[part 1 of 3: package /BMW/SystemComposition]
AUTOSAR XML (schema 4-2-2)
package /BMW/SystemComposition
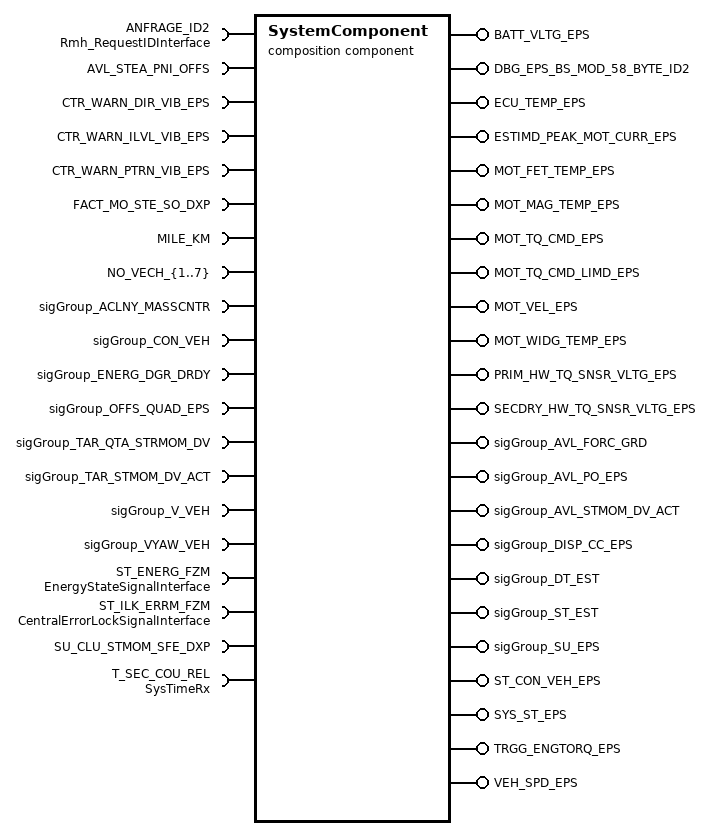
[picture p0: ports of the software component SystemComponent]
  composition sw component type SystemComponent
    23 x provide port:
      BATT_VLTG_EPS: nonqueued-sender-com-spec{data-element=BATT_VLTG_EPS, init-value=0}, provided-interface=BATT_VLTG_EPS
      DBG_EPS_BS_MOD_58_BYTE_ID2: nonqueued-sender-com-spec{data-element=DBG_EPS_BS_MOD_58_BYTE_ID2, init-value=1}, provided-interface=DBG_EPS_BS_MOD_58_BYTE_ID2
      ECU_TEMP_EPS: nonqueued-sender-com-spec=data-element=ECU_TEMP_EPS, provided-interface=ECU_TEMP_EPS
      ESTIMD_PEAK_MOT_CURR_EPS: nonqueued-sender-com-spec=data-element=ESTIMD_PEAK_MOT_CURR_EPS, provided-interface=ESTIMD_PEAK_MOT_CURR_EPS
      MOT_FET_TEMP_EPS: nonqueued-sender-com-spec=data-element=MOT_FET_TEMP_EPS, provided-interface=MOT_FET_TEMP_EPS
      MOT_MAG_TEMP_EPS: nonqueued-sender-com-spec=data-element=MOT_MAG_TEMP_EPS, provided-interface=MOT_MAG_TEMP_EPS
      MOT_TQ_CMD_EPS: nonqueued-sender-com-spec=data-element=MOT_TQ_CMD_EPS, provided-interface=MOT_TQ_CMD_EPS
      MOT_TQ_CMD_LIMD_EPS: nonqueued-sender-com-spec=data-element=MOT_TQ_CMD_LIMD_EPS, provided-interface=MOT_TQ_CMD_LIMD_EPS
      MOT_VEL_EPS: nonqueued-sender-com-spec=data-element=MOT_VEL_EPS, provided-interface=MOT_VEL_EPS
      MOT_WIDG_TEMP_EPS: nonqueued-sender-com-spec=data-element=MOT_WIDG_TEMP_EPS, provided-interface=MOT_WIDG_TEMP_EPS
      PRIM_HW_TQ_SNSR_VLTG_EPS: nonqueued-sender-com-spec=data-element=PRIM_HW_TQ_SNSR_VLTG_EPS, provided-interface=PRIM_HW_TQ_SNSR_VLTG_EPS
      SECDRY_HW_TQ_SNSR_VLTG_EPS: nonqueued-sender-com-spec=data-element=SECDRY_HW_TQ_SNSR_VLTG_EPS, provided-interface=SECDRY_HW_TQ_SNSR_VLTG_EPS
      sigGroup_AVL_FORC_GRD: nonqueued-sender-com-spec{data-element=sigGroup_AVL_FORC_GRD, uses-end-to-end-protection=true}, provided-interface=sigGroup_AVL_FORC_GRD
      sigGroup_AVL_PO_EPS: nonqueued-sender-com-spec{data-element=sigGroup_AVL_PO_EPS, uses-end-to-end-protection=true}, provided-interface=sigGroup_AVL_PO_EPS
      sigGroup_AVL_STMOM_DV_ACT: nonqueued-sender-com-spec{data-element=sigGroup_AVL_STMOM_DV_ACT, uses-end-to-end-protection=true}, provided-interface=sigGroup_AVL_STMOM_DV_ACT
      sigGroup_DISP_CC_EPS: nonqueued-sender-com-spec{data-element=sigGroup_DISP_CC_EPS, uses-end-to-end-protection=true}, provided-interface=sigGroup_DISP_CC_EPS
      sigGroup_DT_EST: nonqueued-sender-com-spec{data-element=sigGroup_DT_EST, uses-end-to-end-protection=true}, provided-interface=sigGroup_DT_EST
      sigGroup_ST_EST: nonqueued-sender-com-spec{data-element=sigGroup_ST_EST, uses-end-to-end-protection=true}, provided-interface=sigGroup_ST_EST
      sigGroup_SU_EPS: nonqueued-sender-com-spec{data-element=sigGroup_SU_EPS, uses-end-to-end-protection=true}, provided-interface=sigGroup_SU_EPS
      ST_CON_VEH_EPS: nonqueued-sender-com-spec=data-element=ST_CON_VEH_EPS, provided-interface=ST_CON_VEH_EPS
      SYS_ST_EPS: nonqueued-sender-com-spec=data-element=SYS_ST_EPS, provided-interface=SYS_ST_EPS
      TRGG_ENGTORQ_EPS: nonqueued-sender-com-spec=data-element=TRGG_ENGTORQ_EPS, provided-interface=TRGG_ENGTORQ_EPS
      VEH_SPD_EPS: nonqueued-sender-com-spec=data-element=VEH_SPD_EPS, provided-interface=VEH_SPD_EPS
    26 x require port:
      ANFRAGE_ID2: nonqueued-receiver-com-spec{data-element=requestedMsgID, filter=data-filter-type=ALWAYS}, required-interface=Rmh_RequestIDInterface
      AVL_STEA_PNI_OFFS: nonqueued-receiver-com-spec{data-element=AVL_STEA_PNI_OFFS, uses-end-to-end-protection=true, alive-timeout=0.11, enable-update=true, filter=data-filter-type=ALWAYS, init-value=2046}, required-interface=AVL_STEA_PNI_OFFS
      CTR_WARN_DIR_VIB_EPS: nonqueued-receiver-com-spec{data-element=CTR_WARN_DIR_VIB_EPS, alive-timeout=0.55, filter=data-filter-type=ALWAYS, init-value=3}, required-interface=CTR_WARN_DIR_VIB_EPS
      CTR_WARN_ILVL_VIB_EPS: nonqueued-receiver-com-spec{data-element=CTR_WARN_ILVL_VIB_EPS, alive-timeout=0.55, filter=data-filter-type=ALWAYS, init-value=15}, required-interface=CTR_WARN_ILVL_VIB_EPS
      CTR_WARN_PTRN_VIB_EPS: nonqueued-receiver-com-spec{data-element=CTR_WARN_PTRN_VIB_EPS, alive-timeout=0.55, filter=data-filter-type=ALWAYS, init-value=15}, required-interface=CTR_WARN_PTRN_VIB_EPS
      FACT_MO_STE_SO_DXP: nonqueued-receiver-com-spec{data-element=FACT_MO_STE_SO_DXP, alive-timeout=0.045, filter=data-filter-type=ALWAYS, init-value=255}, required-interface=FACT_MO_STE_SO_DXP
      MILE_KM: nonqueued-receiver-com-spec{data-element=MILE_KM, alive-timeout=11, filter=data-filter-type=ALWAYS, init-value=0}, required-interface=MILE_KM
      NO_VECH_{1..7}: nonqueued-receiver-com-spec{data-element=NO_VECH_{1..7}, filter=data-filter-type=ALWAYS}, required-interface=NO_VECH_{1..7}
      sigGroup_ACLNY_MASSCNTR: nonqueued-receiver-com-spec{data-element=sigGroup_ACLNY_MASSCNTR, uses-end-to-end-protection=true, alive-timeout=0.015, enable-update=true, filter=data-filter-type=ALWAYS}, required-interface=sigGroup_ACLNY_MASSCNTR
      sigGroup_CON_VEH: nonqueued-receiver-com-spec{data-element=sigGroup_CON_VEH, uses-end-to-end-protection=true, alive-timeout=0.11, enable-update=true, filter=data-filter-type=ALWAYS, init-value=fields=[0, CON_VEH_dummy_56_63:15, CRC_CON_VEH:0, CTR_BS_PRTNT:15, CTR_FKTN_PRTNT:15, QU_ST_CON_VEH:0, ST_CON_VEH:0]}, required-interface=sigGroup_CON_VEH
      sigGroup_ENERG_DGR_DRDY: nonqueued-receiver-com-spec{data-element=sigGroup_ENERG_DGR_DRDY, uses-end-to-end-protection=true, alive-timeout=0.015, enable-update=true, filter=data-filter-type=ALWAYS}, required-interface=sigGroup_ENERG_DGR_DRDY
      sigGroup_OFFS_QUAD_EPS: nonqueued-receiver-com-spec{data-element=sigGroup_OFFS_QUAD_EPS, uses-end-to-end-protection=true, alive-timeout=1.1, enable-update=true, filter=data-filter-type=ALWAYS, init-value=fields=[AVL_PO_IDX_ICM:65535, ST_OFFS_QUAD_EPS:15, CRC_OFFS_QUAD_EPS:0, OFFS_QUAD_RTR_EPS:255, ALIV_OFFS_QUAD_EPS:0]}, required-interface=sigGroup_OFFS_QUAD_EPS
      sigGroup_TAR_QTA_STRMOM_DV: nonqueued-receiver-com-spec{data-element=sigGroup_TAR_QTA_STRMOM_DV, uses-end-to-end-protection=true, alive-timeout=0.015, enable-update=true, filter=data-filter-type=ALWAYS}, required-interface=sigGroup_TAR_QTA_STRMOM_DV
      sigGroup_TAR_STMOM_DV_ACT: nonqueued-receiver-com-spec{data-element=sigGroup_TAR_STMOM_DV_ACT, uses-end-to-end-protection=true, alive-timeout=0.015, enable-update=true, filter=data-filter-type=ALWAYS}, required-interface=sigGroup_TAR_STMOM_DV_ACT
      sigGroup_V_VEH: nonqueued-receiver-com-spec{data-element=sigGroup_V_VEH, uses-end-to-end-protection=true, alive-timeout=0.02, enable-update=true, filter=data-filter-type=ALWAYS, init-value=fields=[0, CRC_V_VEH:0, DVCO_VEH:0, QU_V_VEH_COG:0, ST_V_VEH_NSS:1, V_VEH_COG:0, V_VEH_dummy_39_39:0]}, required-interface=sigGroup_V_VEH
      sigGroup_VYAW_VEH: nonqueued-receiver-com-spec{data-element=sigGroup_VYAW_VEH, uses-end-to-end-protection=true, alive-timeout=0.015, enable-update=true, filter=data-filter-type=ALWAYS}, required-interface=sigGroup_VYAW_VEH
      ST_ENERG_FZM: nonqueued-receiver-com-spec{data-element=energyState, uses-end-to-end-protection=true, alive-timeout=21, enable-update=true, filter=data-filter-type=ALWAYS, init-value=15}, required-interface=EnergyStateSignalInterface
      ST_ILK_ERRM_FZM: nonqueued-receiver-com-spec{data-element=centralErrorLock, alive-timeout=21, filter=data-filter-type=ALWAYS, init-value=3}, required-interface=CentralErrorLockSignalInterface
      SU_CLU_STMOM_SFE_DXP: nonqueued-receiver-com-spec{data-element=SU_CLU_STMOM_SFE_DXP, alive-timeout=0.045, filter=data-filter-type=ALWAYS, init-value=15}, required-interface=SU_CLU_STMOM_SFE_DXP
      T_SEC_COU_REL: nonqueued-receiver-com-spec{data-element=timeSignal, filter=data-filter-type=ALWAYS}, required-interface=SysTimeRx
    263 x component:
      AAACalRegn01Inin00_Dummy: type=AAACalRegn01Inin01_Dummy
      AAACalRegn01Inin00GroupA_Dummy: type=AAACalRegn01Inin01GroupA_Dummy
      AAACalRegn01Inin00GroupC_Dummy: type=AAACalRegn01Inin01GroupC_Dummy
      AAACalRegn01Inin00GroupD_Dummy: type=AAACalRegn01Inin01GroupD_Dummy
      AAACalRegn01Inin01_Dummy: type=AAACalRegn01Inin01_Dummy
      AAACalRegn01Inin01GroupA_Dummy: type=AAACalRegn01Inin01GroupA_Dummy
      AAACalRegn01Inin01GroupC_Dummy: type=AAACalRegn01Inin01GroupC_Dummy
      AAACalRegn01Inin01GroupD_Dummy: type=AAACalRegn01Inin01GroupD_Dummy
      AAACalRegn01Inin02_Dummy: type=AAACalRegn01Inin01_Dummy
      AAACalRegn01Inin02GroupA_Dummy: type=AAACalRegn01Inin01GroupA_Dummy
      AAACalRegn01Inin02GroupC_Dummy: type=AAACalRegn01Inin01GroupC_Dummy
      AAACalRegn01Inin02GroupD_Dummy: type=AAACalRegn01Inin01GroupD_Dummy
      AAACalRegn01Inin03_Dummy: type=AAACalRegn01Inin01_Dummy
      AAACalRegn01Inin03GroupA_Dummy: type=AAACalRegn01Inin01GroupA_Dummy
      AAACalRegn01Inin03GroupC_Dummy: type=AAACalRegn01Inin01GroupC_Dummy
      AAACalRegn01Inin03GroupD_Dummy: type=AAACalRegn01Inin01GroupD_Dummy
      AAACalRegn01Inin04_Dummy: type=AAACalRegn01Inin01_Dummy
      AAACalRegn01Inin04GroupA_Dummy: type=AAACalRegn01Inin01GroupA_Dummy
      AAACalRegn01Inin04GroupC_Dummy: type=AAACalRegn01Inin01GroupC_Dummy
      AAACalRegn01Inin04GroupD_Dummy: type=AAACalRegn01Inin01GroupD_Dummy
      AAACalRegn01Inin05_Dummy: type=AAACalRegn01Inin01_Dummy
      AAACalRegn01Inin05GroupA_Dummy: type=AAACalRegn01Inin01GroupA_Dummy
      AAACalRegn01Inin05GroupC_Dummy: type=AAACalRegn01Inin01GroupC_Dummy
      AAACalRegn01Inin05GroupD_Dummy: type=AAACalRegn01Inin01GroupD_Dummy
      AAACalRegn01Inin06_Dummy: type=AAACalRegn01Inin01_Dummy
      AAACalRegn01Inin06GroupA_Dummy: type=AAACalRegn01Inin01GroupA_Dummy
      AAACalRegn01Inin06GroupC_Dummy: type=AAACalRegn01Inin01GroupC_Dummy
      AAACalRegn01Inin06GroupD_Dummy: type=AAACalRegn01Inin01GroupD_Dummy
      AAACalRegn01IninOptSetA{00..03}_Dummy: type=AAACalRegn01IninOptSetA01_Dummy
      AAACalRegn02Rt00_Dummy: type=AAACalRegn02Rt01_Dummy
      AAACalRegn02Rt00GroupA_Dummy: type=AAACalRegn02Rt01GroupA_Dummy
      AAACalRegn02Rt00GroupC_Dummy: type=AAACalRegn02Rt01GroupC_Dummy
      AAACalRegn02Rt00GroupD_Dummy: type=AAACalRegn02Rt01GroupD_Dummy
      AAACalRegn02Rt01_Dummy: type=AAACalRegn02Rt01_Dummy
      AAACalRegn02Rt01GroupA_Dummy: type=AAACalRegn02Rt01GroupA_Dummy
      AAACalRegn02Rt01GroupC_Dummy: type=AAACalRegn02Rt01GroupC_Dummy
      AAACalRegn02Rt01GroupD_Dummy: type=AAACalRegn02Rt01GroupD_Dummy
      AAACalRegn02Rt02_Dummy: type=AAACalRegn02Rt01_Dummy
      AAACalRegn02Rt02GroupA_Dummy: type=AAACalRegn02Rt01GroupA_Dummy
      AAACalRegn02Rt02GroupC_Dummy: type=AAACalRegn02Rt01GroupC_Dummy
      AAACalRegn02Rt02GroupD_Dummy: type=AAACalRegn02Rt01GroupD_Dummy
      AAACalRegn02Rt03_Dummy: type=AAACalRegn02Rt01_Dummy
      AAACalRegn02Rt03GroupA_Dummy: type=AAACalRegn02Rt01GroupA_Dummy
      AAACalRegn02Rt03GroupC_Dummy: type=AAACalRegn02Rt01GroupC_Dummy
      AAACalRegn02Rt03GroupD_Dummy: type=AAACalRegn02Rt01GroupD_Dummy
      BacComIf: type=BacComIf
      BattVltg: type=BattVltg
      BattVltgCorrln: type=BattVltgCorrln
      BmwDiagcSrvHndlg: type=BmwDiagcSrvHndlg
      BmwDrvgDynStMac: type=BmwDrvgDynStMac
      BmwFltHndlg: type=BmwFltHndlg
      BmwHaptcFb: type=BmwHaptcFb
      BmwHwAgArbnAndEotPosn: type=BmwHwAgArbnAndEotPosn
      BmwHwTqOvrlArbn: type=BmwHwTqOvrlArbn
      BmwMotTqOvrlArbn: type=BmwMotTqOvrlArbn
      BmwMsgSlot107Bas0Repn1BusFrChA: type=BmwMsgSlot107Bas0Repn1BusFrChA
      BmwMsgSlot108Bas0Repn2BusFrChA: type=BmwMsgSlot108Bas0Repn2BusFrChA
      BmwMsgSlot121Bas1Repn2BusFrChA: type=BmwMsgSlot121Bas1Repn2BusFrChA
      BmwMsgSlot234Bas1Repn2BusFrChA: type=BmwMsgSlot234Bas1Repn2BusFrChA
      BmwMsgSlot269Bas2Repn4BusFrChA: type=BmwMsgSlot269Bas2Repn4BusFrChA
      BmwMsgSlot274Bas0Repn8BusFrChA: type=BmwMsgSlot274Bas0Repn8BusFrChA
      BmwMsgSlot274Bas2Repn4BusFrChA: type=BmwMsgSlot274Bas2Repn4BusFrChA
      BmwMsgSlot276Bas4Repn8BusFrChA: type=BmwMsgSlot276Bas4Repn8BusFrChA
      BmwMsgSlot315Bas0Repn1BusFrChA: type=BmwMsgSlot315Bas0Repn1BusFrChA
      BmwMsgSlot49Bas0Repn2BusFrChA: type=BmwMsgSlot49Bas0Repn2BusFrChA
      BmwMsgSlot49Bas1Repn2BusFrChA: type=BmwMsgSlot49Bas1Repn2BusFrChA
      BmwMsgSlot51Bas0Repn2BusFrChA: type=BmwMsgSlot51Bas0Repn2BusFrChA
      BmwMsgSlot53Bas3Repn8BusFrChA: type=BmwMsgSlot53Bas3Repn8BusFrChA
      BmwMsgSlot55Bas0Repn2BusFrChA: type=BmwMsgSlot55Bas0Repn2BusFrChA
      BmwMsgSlot55Bas3Repn4BusFrChA: type=BmwMsgSlot55Bas3Repn4BusFrChA
      BmwMsgSlot56Bas0Repn2BusFrChA: type=BmwMsgSlot56Bas0Repn2BusFrChA
      BmwMsgSlot68Bas0Repn2BusFrChA: type=BmwMsgSlot68Bas0Repn2BusFrChA
      BmwMsgSlot68Bas1Repn2BusFrChA: type=BmwMsgSlot68Bas1Repn2BusFrChA
      BmwPwrPrkgDampg: type=BmwPwrPrkgDampg
      BmwSplyCurrLim: type=BmwSplyCurrLim
      BmwStReqMgr: type=BmwStReqMgr
      BmwSwFctDi: type=BmwSwFctDi
      BmwTqOvrlCdngAndDrvgDynFac: type=BmwTqOvrlCdngAndDrvgDynFac
      BmwTrfcJamAssiDampg: type=BmwTrfcJamAssiDampg
      BmwTunSetHndlr: type=BmwTunSetHndlr
      BmwVehSpd: type=BmwVehSpd
      CalRegn01Cmn: type=CalRegn01Cmn
      CalRegn01CmnGroupA: type=CalRegn01CmnGroupA
      CalRegn01CmnGroupB: type=CalRegn01CmnGroupB
      CalRegn01CmnGroupC: type=CalRegn01CmnGroupC
      CalRegn01CmnGroupD: type=CalRegn01CmnGroupD
      CalRegn01Inin00: type=CalRegn01Inin00
      CalRegn01Inin00GroupA: type=CalRegn01Inin00GroupA
      CalRegn01Inin00GroupC: type=CalRegn01Inin00GroupC
      CalRegn01Inin00GroupD: type=CalRegn01Inin00GroupD
      CalRegn01Inin01: type=CalRegn01Inin01
      CalRegn01Inin01GroupA: type=CalRegn01Inin01GroupA
      CalRegn01Inin01GroupC: type=CalRegn01Inin01GroupC
      CalRegn01Inin01GroupD: type=CalRegn01Inin01GroupD
      CalRegn01Inin02: type=CalRegn01Inin02
      CalRegn01Inin02GroupA: type=CalRegn01Inin02GroupA
      CalRegn01Inin02GroupC: type=CalRegn01Inin02GroupC
      CalRegn01Inin02GroupD: type=CalRegn01Inin02GroupD
      CalRegn01Inin03: type=CalRegn01Inin03
      CalRegn01Inin03GroupA: type=CalRegn01Inin03GroupA
      CalRegn01Inin03GroupC: type=CalRegn01Inin03GroupC
      CalRegn01Inin03GroupD: type=CalRegn01Inin03GroupD
      CalRegn01Inin04: type=CalRegn01Inin04
      CalRegn01Inin04GroupA: type=CalRegn01Inin04GroupA
      CalRegn01Inin04GroupC: type=CalRegn01Inin04GroupC
      CalRegn01Inin04GroupD: type=CalRegn01Inin04GroupD
      CalRegn01Inin05: type=CalRegn01Inin05
      CalRegn01Inin05GroupA: type=CalRegn01Inin05GroupA
      CalRegn01Inin05GroupC: type=CalRegn01Inin05GroupC
      CalRegn01Inin05GroupD: type=CalRegn01Inin05GroupD
      CalRegn01Inin06: type=CalRegn01Inin06
      CalRegn01Inin06GroupA: type=CalRegn01Inin06GroupA
      CalRegn01Inin06GroupC: type=CalRegn01Inin06GroupC
      CalRegn01Inin06GroupD: type=CalRegn01Inin06GroupD
      CalRegn01IninOptSetA{00..03}: type=CalRegn01IninOptSetA{00..03}
      CalRegn02Rt00: type=CalRegn02Rt00
      CalRegn02Rt00GroupA: type=CalRegn02Rt00GroupA
      CalRegn02Rt00GroupC: type=CalRegn02Rt00GroupC
      CalRegn02Rt00GroupD: type=CalRegn02Rt00GroupD
      CalRegn02Rt01: type=CalRegn02Rt01
      CalRegn02Rt01GroupA: type=CalRegn02Rt01GroupA
      CalRegn02Rt01GroupC: type=CalRegn02Rt01GroupC
      CalRegn02Rt01GroupD: type=CalRegn02Rt01GroupD
      CalRegn02Rt02: type=CalRegn02Rt02
      CalRegn02Rt02GroupA: type=CalRegn02Rt02GroupA
      CalRegn02Rt02GroupC: type=CalRegn02Rt02GroupC
      CalRegn02Rt02GroupD: type=CalRegn02Rt02GroupD
      CalRegn02Rt03: type=CalRegn02Rt03
      CalRegn02Rt03GroupA: type=CalRegn02Rt03GroupA
      CalRegn02Rt03GroupC: type=CalRegn02Rt03GroupC
      CalRegn02Rt03GroupD: type=CalRegn02Rt03GroupD
      CDD_Adc0CfgAndUse: type=CDD_Adc0CfgAndUse
      CDD_Adc1CfgAndUse: type=CDD_Adc1CfgAndUse
      CDD_AdcDiagc: type=CDD_AdcDiagc
      CDD_BattRtnCurr: type=CDD_BattRtnCurr
      CDD_Bmw5441McuCfg: type=CDD_Bmw5441McuCfg
      CDD_ChkPtAppl10: type=CDD_ChkPtAppl10
      CDD_ChkPtAppl{7..9}: type=CDD_ChkPtAppl{7..9}
      CDD_CoreVltgMonr: type=CDD_CoreVltgMonr
      CDD_CurrMeas: type=CDD_CurrMeas
      CDD_CurrMeasArbn: type=CDD_CurrMeasArbn
      CDD_DataAndAdrPar: type=CDD_DataAndAdrPar
      CDD_DmaCfgAndUse: type=CDD_DmaCfgAndUse
      CDD_EcmOutpAndDiagc: type=CDD_EcmOutpAndDiagc
      CDD_ExcpnHndlg: type=CDD_ExcpnHndlg
      CDD_FlsMem: type=CDD_FlsMem
      CDD_GuardCfgAndDiagc: type=CDD_GuardCfgAndDiagc
      CDD_HwTq4Meas: type=CDD_HwTq4Meas
      CDD_HwTq5Meas: type=CDD_HwTq5Meas
      CDD_McuCoreCfgAndDiagc: type=CDD_McuCoreCfgAndDiagc
      CDD_McuDiagc: type=CDD_McuDiagc
      CDD_MotAg0Meas: type=CDD_MotAg0Meas
      CDD_MotAg1Meas: type=CDD_MotAg1Meas
      CDD_MotAg3Meas: type=CDD_MotAg3Meas
      CDD_MotAg4Meas: type=CDD_MotAg4Meas
      CDD_MotAgCmp: type=CDD_MotAgCmp
      CDD_MotCtrlMgr: type=CDD_MotCtrlMgr
      CDD_MotCurrRegVltgLimr: type=CDD_MotCurrRegVltgLimr
      CDD_MotVel: type=CDD_MotVel
      CDD_NvMProxy: type=CDD_NvMProxy
      CDD_NxtrTi: type=CDD_NxtrTi
      CDD_RamMem: type=CDD_RamMem
      CDD_SinVltgGenn: type=CDD_SinVltgGenn
      CDD_SyncCrc: type=CDD_SyncCrc
      CDD_Tauj0CfgAndUse: type=CDD_Tauj0CfgAndUse
      CDD_TSG31CfgAndUse: type=CDD_TSG31CfgAndUse
      CDD_VrfyCritReg: type=CDD_VrfyCritReg
      CDD_XcpIf: type=CDD_XcpIf
      CDD_XcpIfXcpEve2MilliSecDataAcqn: type=CDD_XcpIfXcpEve2MilliSecDataAcqn
      ClsdLoopDampg: type=ClsdLoopDampg
      ClsdLoopHys: type=ClsdLoopHys
      CmnMfgSrv: type=CmnMfgSrv
      CmnMfgSrvIf: type=CmnMfgSrvIf
      CmplncErr: type=CmplncErr
      Coding: type=Coding
      CtrldVelRtn: type=CtrldVelRtn
      CurrMeasCorrln: type=CurrMeasCorrln
      Darh: type=Darh
      DemWrapper: type=DemWrapper
      DiagcMgr: type=DiagcMgr
      DiagcMgrProxyAppl10: type=DiagcMgrProxyAppl10
      DiagcMgrProxyAppl{7..9}: type=DiagcMgrProxyAppl{7..9}
      DiagcMgrStub: type=DiagcMgrStub
      Dlog: type=Dlog
      DutyCycThermProtn: type=DutyCycThermProtn
      EcuTMeas: type=EcuTMeas
      Effort: type=Effort
      ElecPwrCns: type=ElecPwrCns
      EotProtn: type=EotProtn
      EPSInstance: type=EPSComponent
      EpsStEstimn: type=EpsStEstimn
      FalbckAssi: type=FalbckAssi
      FltInj: type=FltInj
      GateDrv0Ctrl: type=GateDrv0Ctrl
      GlbLimr: type=GlbLimr
      HiLoadStallLimr: type=HiLoadStallLimr
      HwRefTqSum: type=HwRefTqSum
      HwTqArbn: type=HwTqArbn
      HwTqCorrln: type=HwTqCorrln
      HwTqTrakgCtrl: type=HwTqTrakgCtrl
      InertiaCmpVel: type=InertiaCmpVel
      IoHwAb: type=IoHwAb
      LimrCdng: type=LimrCdng
      LoaMgr: type=LoaMgr
      LrndRackCentr: type=LrndRackCentr
      LrnPinionCentr: type=LrnPinionCentr
      McalErrHndlg: type=McalErrHndlg
      McuErrInj: type=McuErrInj
      MotAgCorrln: type=MotAgCorrln
      MotCtrlPrmEstimn: type=MotCtrlPrmEstimn
      MotCurrPeakEstimn: type=MotCurrPeakEstimn
      MotCurrRegCfg: type=MotCurrRegCfg
      MotQuadDetn: type=MotQuadDetn
      MotRefMdl: type=MotRefMdl
      MotTqCalcd: type=MotTqCalcd
      MotTqCmdSca: type=MotTqCmdSca
      MotTqTranlDampg: type=MotTqTranlDampg
      MotVelCtrl: type=MotVelCtrl
      NxtrCalIds: type=NxtrCalIds
      NxtrMath: type=NxtrMath
      NxtrSwIds: type=NxtrSwIds
      Omc: type=Omc
      PhaDiscnct: type=PhaDiscnct
      PolarityCfg: type=PolarityCfg
      PosnTrakgServo: type=PosnTrakgServo
      ProgMfgSrv: type=ProgMfgSrv
      PullCmpActv: type=PullCmpActv
      PwrDiscnct: type=PwrDiscnct
      PwrLimr: type=PwrLimr
      PwrSply: type=PwrSply
      PwrUpSeq: type=PwrUpSeq
      Rmh: type=Rmh
      Rmh_Cdd: type=Rmh_Cdd
      RvsBattProtn: type=RvsBattProtn
      ShtdwnMech: type=ShtdwnMech
      StdDiag: type=StdDiag
      SteerCmdArbnAndLim: type=SteerCmdArbnAndLim
      Stm: type=Stm
      StOutpCtrl: type=StOutpCtrl
      Swp: type=Swp
      SysFricLrng: type=SysFricLrng
      SysKineAndEff: type=SysKineAndEff
      SysStMod: type=SysStMod
      SysTime: type=SysTime
      TEstimn: type=TEstimn
      TmplMonr: type=TmplMonr
      TqOscn: type=TqOscn
      TunSelnAuthy: type=TunSelnAuthy
      TunSelnMngt: type=TunSelnMngt
      TurnCntrCorrln: type=TurnCntrCorrln
      VehSigCdng: type=VehSigCdng
      VehSpdLimr: type=VehSpdLimr
      Vin: type=Vin
    connect BacComIf.ComVin -> Vin.ComVin
    connect BattVltg.BrdgVltg -> BmwDiagcSrvHndlg.BrdgVltg
    connect BattVltg.BrdgVltg -> BmwMsgSlot315Bas0Repn1BusFrChA.BrdgVltg
    connect BattVltg.BrdgVltg -> BmwSplyCurrLim.BrdgVltg
    connect BattVltg.BrdgVltg -> CDD_CurrMeas.BrdgVltg
    connect BattVltg.BrdgVltg -> CDD_MotCtrlMgr.BrdgVltg
    connect BattVltg.BrdgVltg -> CmnMfgSrv.BrdgVltg
    connect BattVltg.BrdgVltg -> DiagcMgr.BrdgVltg
    connect BattVltg.BrdgVltg -> ElecPwrCns.BrdgVltg
    connect BattVltg.BrdgVltg -> MotRefMdl.BrdgVltg
    connect BattVltg.BrdgVltg -> PwrLimr.BrdgVltg
    connect BattVltgCorrln.BattSwdVltgCorrlnSts -> BattVltg.BattSwdVltgCorrlnSts
    connect BmwDiagcSrvHndlg.BmwHwAgOffs -> BmwHwAgArbnAndEotPosn.BmwHwAgOffs
    connect BmwDiagcSrvHndlg.LockToLockEna -> BmwMotTqOvrlArbn.PinionCentrLrnEna
    connect BmwDiagcSrvHndlg.LockToLockEna -> LrndRackCentr.PinionCentrLrnEna
    connect BmwDiagcSrvHndlg.LockToLockEna -> LrnPinionCentr.PinionCentrLrnEna
    connect BmwDrvgDynStMac.DrvgDynIfSt -> BmwDiagcSrvHndlg.DrvgDynIfSt
    connect BmwDrvgDynStMac.DrvgDynIfSt -> BmwHwTqOvrlArbn.DrvgDynIfSt
    connect BmwDrvgDynStMac.DrvgDynActv -> BmwMotTqOvrlArbn.DrvgDynActv
    connect BmwDrvgDynStMac.DrvgDynIfSt -> BmwMsgSlot234Bas1Repn2BusFrChA.DrvgDynIfSt
    connect BmwDrvgDynStMac.DrvgDynActv -> BmwTqOvrlCdngAndDrvgDynFac.DrvgDynActv
    connect BmwDrvgDynStMac.DrvgDynIfSt -> BmwTqOvrlCdngAndDrvgDynFac.DrvgDynIfSt
    connect BmwDrvgDynStMac.OutpTqOvrlRampInEna -> BmwTqOvrlCdngAndDrvgDynFac.OutpTqOvrlRampInEna
    connect BmwFltHndlg.BmwFltLampReqSts -> BmwMsgSlot274Bas2Repn4BusFrChA.BmwFltLampReqSts
    connect BmwFltHndlg.BmwFltLampReqTyp -> BmwMsgSlot274Bas2Repn4BusFrChA.BmwFltLampReqTyp
    connect BmwHaptcFb.HaptcFbSt -> BmwMsgSlot234Bas1Repn2BusFrChA.HaptcFbSt
    connect BmwHaptcFb.HwOscnEna -> TqOscn.HwOscnEna
    connect BmwHaptcFb.HwOscnFallRampRate -> TqOscn.HwOscnFallRampRate
    connect BmwHaptcFb.HwOscnFrq -> TqOscn.HwOscnFrq
    connect BmwHaptcFb.HwOscnMotAmp -> TqOscn.HwOscnMotAmp
    connect BmwHaptcFb.HwOscnRisngRampRate -> TqOscn.HwOscnRisngRampRate
    connect BmwHwAgArbnAndEotPosn.BmwPinionAg -> BmwDiagcSrvHndlg.BmwPinionAg
    connect BmwHwAgArbnAndEotPosn.BmwPinionAgQlfr -> BmwDiagcSrvHndlg.BmwPinionAgQlfr
    connect BmwHwAgArbnAndEotPosn.BmwRackCentrToVehCentrOffs -> BmwDiagcSrvHndlg.BmwRackCentrToVehCentrOffs
    connect BmwHwAgArbnAndEotPosn.BmwRackCentrToVehCentrOffsVld -> BmwDiagcSrvHndlg.BmwRackCntrToVehCntrOffsVld
    connect BmwHwAgArbnAndEotPosn.ClrBmwRackCentrToVehCentrOffs -> BmwDiagcSrvHndlg.ClrBmwRackCentrToVehCentrOffs
    connect BmwHwAgArbnAndEotPosn.ClrVehCentrPosn -> BmwDiagcSrvHndlg.ClrVehCentrPosn
    connect BmwHwAgArbnAndEotPosn.LongTermVehCentrCmpl -> BmwDiagcSrvHndlg.LongTermVehCentrCmpl
    connect BmwHwAgArbnAndEotPosn.PinionAg -> BmwDiagcSrvHndlg.PinionAg
    connect BmwHwAgArbnAndEotPosn.PinionAgConf -> BmwDiagcSrvHndlg.PinionAgConf
    connect BmwHwAgArbnAndEotPosn.SetVehCentrPosn -> BmwDiagcSrvHndlg.SetVehCentrPosn
    connect BmwHwAgArbnAndEotPosn.BmwPinionAg -> BmwMsgSlot51Bas0Repn2BusFrChA.BmwPinionAg
    connect BmwHwAgArbnAndEotPosn.BmwPinionAgQlfr -> BmwMsgSlot51Bas0Repn2BusFrChA.BmwPinionAgQlfr
    connect BmwHwAgArbnAndEotPosn.BmwRackCentrToVehCentrOffs -> BmwMsgSlot51Bas0Repn2BusFrChA.BmwRackCntrToVehCntrOffs
    connect BmwHwAgArbnAndEotPosn.BmwRackCentrToVehCentrOffsVld -> BmwMsgSlot51Bas0Repn2BusFrChA.BmwRackCntrToVehCntrOffsVld
    connect BmwHwAgArbnAndEotPosn.PinionAg -> BmwPwrPrkgDampg.PinionAg
    connect BmwHwAgArbnAndEotPosn.PinionAgConf -> BmwPwrPrkgDampg.PinionAgConf
    connect BmwHwAgArbnAndEotPosn.BmwPinionAgQlfr -> BmwVehSpd.BmwPinionAgQlfr
    connect BmwHwAgArbnAndEotPosn.PinionAg -> ClsdLoopHys.HwAg
    connect BmwHwAgArbnAndEotPosn.PinionAg -> CmnMfgSrv.PinionAg
    connect BmwHwAgArbnAndEotPosn.OffsCmpdPinionAg -> CtrldVelRtn.HwAg
    connect BmwHwAgArbnAndEotPosn.PinionAgConf -> CtrldVelRtn.HwAgAuthy
    connect BmwHwAgArbnAndEotPosn.PinionAg -> EotProtn.HwAg
    connect BmwHwAgArbnAndEotPosn.PinionAgConf -> EotProtn.HwAgAuthy
    connect BmwHwAgArbnAndEotPosn.HwAgCcwDetd -> EotProtn.HwAgCcwDetd
    connect BmwHwAgArbnAndEotPosn.HwAgCwDetd -> EotProtn.HwAgCwDetd
    connect BmwHwAgArbnAndEotPosn.HwAgEotCcw -> EotProtn.HwAgEotCcw
    connect BmwHwAgArbnAndEotPosn.HwAgEotCw -> EotProtn.HwAgEotCw
    connect BmwHwAgArbnAndEotPosn.AlgndPinionAg -> LrndRackCentr.HwAg
    connect BmwHwAgArbnAndEotPosn.PinionAg -> LrnPinionCentr.HwAg
    connect BmwHwAgArbnAndEotPosn.PinionAg -> MotTqTranlDampg.HwAg
    connect BmwHwAgArbnAndEotPosn.PinionAg -> PosnTrakgServo.HwAg
    connect BmwHwAgArbnAndEotPosn.PinionAg -> PullCmpActv.HwAg
    connect BmwHwAgArbnAndEotPosn.PinionAgConf -> PullCmpActv.PinionAgConf
    connect BmwHwAgArbnAndEotPosn.PinionAg -> SysFricLrng.HwAg
    connect BmwHwAgArbnAndEotPosn.PinionAgConf -> SysFricLrng.HwAgAuthy
    connect BmwHwAgArbnAndEotPosn.PinionAg -> SysKineAndEff.PinionAg
    connect BmwHwAgArbnAndEotPosn.PinionAg -> VehSpdLimr.HwAg
    connect BmwHwAgArbnAndEotPosn.PinionAgConf -> VehSpdLimr.HwAgAuthy
    connect BmwHwAgArbnAndEotPosn.HwAgEotCcw -> VehSpdLimr.HwAgEotCcw
    connect BmwHwAgArbnAndEotPosn.HwAgEotCw -> VehSpdLimr.HwAgEotCw
    connect BmwHwTqOvrlArbn.HwTqCmdOvrl -> HwRefTqSum.HwTqCmdOvrl
    connect BmwMotTqOvrlArbn.MotTqOvrlCmd -> BmwDrvgDynStMac.MotTqOvrlCmd
    connect BmwMotTqOvrlArbn.MotTqOvrlCmd -> HwTqTrakgCtrl.MotTqCmdOvrl
    connect BmwMsgSlot107Bas0Repn1BusFrChA.BmwQuadOffsSts -> BmwHwAgArbnAndEotPosn.BmwQuadOffsSts
    connect BmwMsgSlot107Bas0Repn1BusFrChA.BmwQuadOffsStsVld -> BmwHwAgArbnAndEotPosn.BmwQuadOffsStsVld
    connect BmwMsgSlot107Bas0Repn1BusFrChA.BmwQuadRtrOffs -> BmwHwAgArbnAndEotPosn.BmwQuadRotorOffs
    connect BmwMsgSlot107Bas0Repn1BusFrChA.BmwQuadRtrOffsVld -> BmwHwAgArbnAndEotPosn.BmwQuadRotorOffsVld
    connect BmwMsgSlot108Bas0Repn2BusFrChA.BmwPinionAgOffs -> BmwHwAgArbnAndEotPosn.BmwPinionAgOffs
    connect BmwMsgSlot108Bas0Repn2BusFrChA.BmwPinionAgOffsSts -> BmwHwAgArbnAndEotPosn.BmwPinionAgOffsSts
    connect BmwMsgSlot121Bas1Repn2BusFrChA.BmwBasPtlNetCtrl -> BmwDiagcSrvHndlg.BmwBasPtlNetCtrl
    connect BmwMsgSlot121Bas1Repn2BusFrChA.BmwVehCdn -> BmwDiagcSrvHndlg.BmwVehCdn
    connect BmwMsgSlot121Bas1Repn2BusFrChA.BmwVehCdn -> BmwDrvgDynStMac.BmwVehCdn
    connect BmwMsgSlot121Bas1Repn2BusFrChA.BmwVehCdn -> BmwMsgSlot315Bas0Repn1BusFrChA.BmwVehCdn
    connect BmwMsgSlot121Bas1Repn2BusFrChA.BmwVehCdn -> BmwStReqMgr.BmwVehCdn
    connect BmwMsgSlot121Bas1Repn2BusFrChA.BmwVehCdnVld -> BmwStReqMgr.BmwVehCdnVld
    connect BmwMsgSlot269Bas2Repn4BusFrChA.BmwHaptcFbIntenNr -> BmwHaptcFb.BmwHaptcFbIntenNr
    connect BmwMsgSlot269Bas2Repn4BusFrChA.BmwHaptcFbIntenNrVld -> BmwHaptcFb.BmwHaptcFbIntenNrVld
    connect BmwMsgSlot269Bas2Repn4BusFrChA.BmwHaptcFbPatNr -> BmwHaptcFb.BmwHaptcFbPatNr
    connect BmwMsgSlot269Bas2Repn4BusFrChA.BmwHaptcFbPatNrVld -> BmwHaptcFb.BmwHaptcFbPatNrVld
    connect BmwMsgSlot276Bas4Repn8BusFrChA.BmwOdomDst -> BmwDiagcSrvHndlg.BmwOdomDst
    connect BmwMsgSlot276Bas4Repn8BusFrChA.BmwOdomDstVld -> BmwDiagcSrvHndlg.BmwOdomDstVld
    connect BmwMsgSlot53Bas3Repn8BusFrChA.BmwRtIdx -> BmwTunSetHndlr.BmwRtIdx
    connect BmwMsgSlot53Bas3Repn8BusFrChA.BmwRtIdxVld -> BmwTunSetHndlr.BmwRtIdxVld
    connect BmwMsgSlot55Bas0Repn2BusFrChA.BmwVehLatA -> VehSigCdng.VehLatASerlCom
    connect BmwMsgSlot55Bas0Repn2BusFrChA.BmwVehLatAVld -> VehSigCdng.VehLatAVldSerlCom
    connect BmwMsgSlot55Bas3Repn4BusFrChA.BmwNearStillVehSpdSts -> BmwMotTqOvrlArbn.BmwNearStillVehSpdSts
    connect BmwMsgSlot55Bas3Repn4BusFrChA.BmwCogVehSpd -> BmwVehSpd.BmwCogVehSpd
    connect BmwMsgSlot55Bas3Repn4BusFrChA.BmwCogVehSpdQlfr -> BmwVehSpd.BmwCogVehSpdQlfr
    connect BmwMsgSlot55Bas3Repn4BusFrChA.BmwCogVehSpdQlfrVld -> BmwVehSpd.BmwCogVehSpdQlfrVld
    connect BmwMsgSlot55Bas3Repn4BusFrChA.BmwCogVehSpdVld -> BmwVehSpd.BmwCogVehSpdVld
    connect BmwMsgSlot55Bas3Repn4BusFrChA.BmwNearStillVehSpdSts -> BmwVehSpd.BmwNearStillVehSpdSts
    connect BmwMsgSlot55Bas3Repn4BusFrChA.BmwNearStillVehSpdStsVld -> BmwVehSpd.BmwNearStillVehSpdStsVld
    connect BmwMsgSlot56Bas0Repn2BusFrChA.BmwVehYawRate -> VehSigCdng.VehYawRateSerlCom
    connect BmwMsgSlot56Bas0Repn2BusFrChA.BmwVehYawRateVld -> VehSigCdng.VehYawRateVldSerlCom
    connect BmwMsgSlot68Bas0Repn2BusFrChA.BmwDrvgDynEnaRqst -> BmwDrvgDynStMac.BmwDrvgDynEnaReq
    connect BmwMsgSlot68Bas0Repn2BusFrChA.BmwDrvgDynFacQlfr -> BmwDrvgDynStMac.BmwDrvgDynFacQlfr
    connect BmwMsgSlot68Bas0Repn2BusFrChA.BmwDrvgDynFacQlfrVld -> BmwDrvgDynStMac.BmwDrvgDynFacQlfrVld
    connect BmwMsgSlot68Bas0Repn2BusFrChA.BmwTarHwTqOvrlQlfr -> BmwDrvgDynStMac.BmwTarHwTqOvrlQlfr
    connect BmwMsgSlot68Bas0Repn2BusFrChA.BmwTarHwTqOvrlQlfrVld -> BmwDrvgDynStMac.BmwTarHwTqOvrlQlfrVld
    connect BmwMsgSlot68Bas0Repn2BusFrChA.BmwTarSteerTqDrvrActrQlfr -> BmwDrvgDynStMac.BmwTarSteerTqDrvrActrQlfr
    connect BmwMsgSlot68Bas0Repn2BusFrChA.BmwTarSteerTqDrvrActrQlfrVld -> BmwDrvgDynStMac.BmwTarSteerTqDrvrActrQlfrVld
    connect BmwMsgSlot68Bas0Repn2BusFrChA.BmwTrfcJamAssiDampgStReq -> BmwDrvgDynStMac.BmwTrfcJamAssiDampgStReq
    connect BmwMsgSlot68Bas0Repn2BusFrChA.BmwTrfcJamAssiDampgStReqVld -> BmwDrvgDynStMac.BmwTrfcJamAssiDampgStReqVld
    connect BmwMsgSlot68Bas0Repn2BusFrChA.BmwDrvgDynErrIfActv -> BmwHwTqOvrlArbn.BmwDrvgDynErrIfActv
    connect BmwMsgSlot68Bas0Repn2BusFrChA.BmwTarHwTqOvrl -> BmwHwTqOvrlArbn.BmwTarHwTqOvrl
    connect BmwMsgSlot68Bas0Repn2BusFrChA.BmwTarHwTqOvrlQlfr -> BmwHwTqOvrlArbn.BmwTarHwTqOvrlQlfr
    connect BmwMsgSlot68Bas0Repn2BusFrChA.BmwDrvgDynDampgFacReq -> BmwTqOvrlCdngAndDrvgDynFac.BmwDrvgDynDampgFacReq
    connect BmwMsgSlot68Bas0Repn2BusFrChA.BmwDrvgDynEffortFacReq -> BmwTqOvrlCdngAndDrvgDynFac.BmwDrvgDynEffortFacReq
    connect BmwMsgSlot68Bas0Repn2BusFrChA.BmwDrvgDynErrIfActv -> BmwTqOvrlCdngAndDrvgDynFac.BmwDrvgDynErrIfActv
    connect BmwMsgSlot68Bas0Repn2BusFrChA.BmwDrvgDynRtnFacReq -> BmwTqOvrlCdngAndDrvgDynFac.BmwDrvgDynRtnFacReq
    connect BmwMsgSlot68Bas0Repn2BusFrChA.BmwTarSteerTqDrvrActr -> BmwTqOvrlCdngAndDrvgDynFac.BmwTarSteerTqDrvrActr
    connect BmwMsgSlot68Bas0Repn2BusFrChA.BmwTrfcJamAssiDampgScaReq -> BmwTrfcJamAssiDampg.BmwTrfcJamAssiDampgScaReq
    connect BmwMsgSlot68Bas0Repn2BusFrChA.BmwTrfcJamAssiDampgScaReqVld -> BmwTrfcJamAssiDampg.BmwTrfcJamAssiDampgScaReqVld
    connect BmwMsgSlot68Bas0Repn2BusFrChA.BmwTrfcJamAssiDampgStReq -> BmwTrfcJamAssiDampg.BmwTrfcJamAssiDampgStReq
    connect BmwMsgSlot68Bas0Repn2BusFrChA.BmwTrfcJamAssiDampgStReqVld -> BmwTrfcJamAssiDampg.BmwTrfcJamAssiDampgStReqVld
    connect BmwMsgSlot68Bas1Repn2BusFrChA.BmwMaxCurrLimr -> BmwSplyCurrLim.BmwMaxCurrLimr
    connect BmwMsgSlot68Bas1Repn2BusFrChA.BmwMaxCurrLimrSts -> BmwSplyCurrLim.BmwMaxCurrLimrSts
    connect BmwPwrPrkgDampg.DampgCmdPwrPrkg -> HwRefTqSum.HwTqCmdDampg
    connect BmwSplyCurrLim.SplyCurrLim -> PwrLimr.SplyCurrLim
    connect BmwStReqMgr.StsSteerAssi -> BmwDrvgDynStMac.StsSteerAssi
    connect BmwStReqMgr.StsSteerAssi -> BmwHaptcFb.StsSteerAssi
    connect BmwStReqMgr.BmwEpsFctSts -> BmwMsgSlot234Bas1Repn2BusFrChA.BmwEpsFctSts
    connect BmwStReqMgr.SysOperMotTqCmdSca -> StOutpCtrl.SysOperMotTqCmdSca
    connect BmwStReqMgr.SysOperRampRate -> StOutpCtrl.SysOperRampRate
    connect BmwStReqMgr.PwrSplyEnaReq -> SysStMod.PwrSplyEnaReq
    connect BmwStReqMgr.SysStReqEna -> SysStMod.SysStReqEna
    connect BmwSwFctDi.HaptcFbEna -> BmwHaptcFb.HaptcFbEna
    connect BmwSwFctDi.HwTqOvrlCmdEna -> BmwHwTqOvrlArbn.HwTqOvrlCmdEna
    connect BmwSwFctDi.DampgCmdPwrPrkgEna -> BmwPwrPrkgDampg.DampgCmdPwrPrkgEna
    connect BmwSwFctDi.MaxCurrAtHiSpd -> BmwSplyCurrLim.MaxCurrAtHiSpd
    connect BmwSwFctDi.MaxCurrAtLoSpd -> BmwSplyCurrLim.MaxCurrAtLoSpd
    connect BmwSwFctDi.BmwOutpTqOvrlCmdEna -> BmwTqOvrlCdngAndDrvgDynFac.BmwOutpTqOvrlCmdEna
    connect BmwSwFctDi.DrvgDynFacEna -> BmwTqOvrlCdngAndDrvgDynFac.DrvgDynFacEna
    connect BmwSwFctDi.TrfcJamAssiCmdEna -> BmwTrfcJamAssiDampg.TrfcJamAssiCmdEna
    connect BmwSwFctDi.TunSetHndlrEna -> BmwTunSetHndlr.TunSetHndlrEna
    connect BmwSwFctDi.HwTqCmdHysBmwOvrd -> HwRefTqSum.HwTqCmdHys
    connect BmwSwFctDi.CtrldVelRtnCmdBmwOvrd -> HwRefTqSum.RtnCmd
    connect BmwSwFctDi.InertiaCmpVelCmdDiBmwOvrd -> InertiaCmpVel.InertiaCmpVelCmdDi
    connect BmwSwFctDi.PullCmpCmdDiBmwOvrd -> PullCmpActv.PullCmpCmdDi
    connect BmwSwFctDi.FricLrngCustEna -> SysFricLrng.FricLrngCustEna
    connect BmwTqOvrlCdngAndDrvgDynFac.DampgCmdSca -> BmwDrvgDynStMac.DampgCmdSca
    connect BmwTqOvrlCdngAndDrvgDynFac.EffortCmdSca -> BmwDrvgDynStMac.EffortCmdSca
    connect BmwTqOvrlCdngAndDrvgDynFac.RtnCmdSca -> BmwDrvgDynStMac.RtnCmdSca
    connect BmwTqOvrlCdngAndDrvgDynFac.BmwOutpTqOvrlCmd -> BmwMotTqOvrlArbn.BmwOutpTqOvrlCmd
    connect BmwTqOvrlCdngAndDrvgDynFac.DampgCmdSca -> ClsdLoopDampg.DampgCmdSca
    connect BmwTqOvrlCdngAndDrvgDynFac.RtnCmdSca -> CtrldVelRtn.RtnCmdSca
    connect BmwTqOvrlCdngAndDrvgDynFac.EffortCmdSca -> Effort.EffortCmdSca
    connect BmwTrfcJamAssiDampg.BmwTrfcJamAssiDampgSt -> BmwMotTqOvrlArbn.BmwTrfcJamAssiDampgSt
    connect BmwTrfcJamAssiDampg.TrfcJamAssiCmd -> BmwMotTqOvrlArbn.TrfcJamAssiCmd
    connect BmwTunSetHndlr.MotVrntRead -> ProgMfgSrv.MotVrntRead
    connect BmwTunSetHndlr.MotVrntWr -> ProgMfgSrv.MotVrntWr
    connect BmwTunSetHndlr.TunVrntRead -> ProgMfgSrv.TunVrntRead
    connect BmwTunSetHndlr.TunVrntWr -> ProgMfgSrv.TunVrntWr
    connect BmwTunSetHndlr.DesIninIdx -> TunSelnMngt.DesIninIdx
    connect BmwTunSetHndlr.DesIninOptSetAIdx -> TunSelnMngt.DesIninOptSetAIdx
    connect BmwTunSetHndlr.DesRtIdx -> TunSelnMngt.DesRtIdx
    connect BmwVehSpd.VehSpd -> BmwDiagcSrvHndlg.VehSpd
    connect BmwVehSpd.VehSpd -> BmwHaptcFb.VehSpd
    connect BmwVehSpd.VehSpdVld -> BmwHaptcFb.VehSpdVld
    connect BmwVehSpd.BmwSecurVehSpdSts -> BmwHwAgArbnAndEotPosn.BmwVehSpdSts
    connect BmwVehSpd.VehSpd -> BmwHwAgArbnAndEotPosn.VehSpd
    connect BmwVehSpd.VehSpdVld -> BmwHwAgArbnAndEotPosn.VehSpdVld
    connect BmwVehSpd.VehSpd -> BmwHwTqOvrlArbn.VehSpd
    connect BmwVehSpd.VehSpd -> BmwMotTqOvrlArbn.VehSpd
    connect BmwVehSpd.VehSpd -> BmwMsgSlot315Bas0Repn1BusFrChA.VehSpd
    connect BmwVehSpd.VehSpd -> BmwPwrPrkgDampg.VehSpd
    connect BmwVehSpd.VehSpd -> BmwSplyCurrLim.VehSpd
    connect BmwVehSpd.BmwSecurVehSpdSts -> BmwStReqMgr.BmwVehSpdSts
    connect BmwVehSpd.VehSpd -> BmwStReqMgr.VehSpd
    connect BmwVehSpd.VehSpd -> BmwTqOvrlCdngAndDrvgDynFac.VehSpd
    connect BmwVehSpd.VehSpd -> BmwTrfcJamAssiDampg.VehSpd
    connect BmwVehSpd.VehSpd -> CDD_CurrMeas.VehSpd
    connect BmwVehSpd.VehSpdVld -> CDD_CurrMeas.VehSpdVld
    connect BmwVehSpd.VehSpd -> CDD_MotCtrlMgr.VehSpd
    connect BmwVehSpd.VehSpd -> ClsdLoopDampg.VehSpd
    connect BmwVehSpd.VehSpd -> ClsdLoopHys.VehSpd
    connect BmwVehSpd.VehSpd -> CtrldVelRtn.VehSpd
    connect BmwVehSpd.VehSpd -> Effort.VehSpd
    connect BmwVehSpd.VehSpd -> EotProtn.VehSpd
    connect BmwVehSpd.VehSpd -> FalbckAssi.VehSpd
    connect BmwVehSpd.VehSpd -> GlbLimr.VehSpd
    connect BmwVehSpd.VehSpd -> HwTqTrakgCtrl.VehSpd
    connect BmwVehSpd.VehSpd -> InertiaCmpVel.VehSpd
    connect BmwVehSpd.VehSpd -> LimrCdng.VehSpd
    connect BmwVehSpd.VehSpd -> MotCurrRegCfg.VehSpd
    connect BmwVehSpd.VehSpd -> MotTqTranlDampg.VehSpd
    connect BmwVehSpd.VehSpd -> PosnTrakgServo.VehSpd
    connect BmwVehSpd.VehSpd -> PullCmpActv.VehSpd
    connect BmwVehSpd.VehSpdVld -> PullCmpActv.VehSpdVld
    connect BmwVehSpd.VehSpd -> SteerCmdArbnAndLim.VehSpd
    connect BmwVehSpd.VehSpd -> Swp.VehSpd
    connect BmwVehSpd.VehSpdVld -> Swp.VehSpdVld
    connect BmwVehSpd.VehSpd -> SysFricLrng.VehSpd
    connect BmwVehSpd.VehSpdVld -> SysFricLrng.VehSpdVld
    connect BmwVehSpd.VehSpd -> TunSelnAuthy.VehSpd
    connect BmwVehSpd.VehSpd -> VehSigCdng.VehSpdSerlCom
    connect BmwVehSpd.VehSpdVld -> VehSigCdng.VehSpdVldSerlCom
    connect BmwVehSpd.VehSpd -> VehSpdLimr.VehSpd
    connect CalRegn01Cmn.BattVltgCorrlnAllwdVltgDif -> BattVltgCorrln.BattVltgCorrlnAllwdVltgDif
    connect CalRegn01Cmn.BattVltgCorrlnBattLoVltg -> BattVltgCorrln.BattVltgCorrlnBattLoVltg
    connect CalRegn01Cmn.BattVltgCorrlnBattOverVltg -> BattVltgCorrln.BattVltgCorrlnBattOverVltg
    connect CalRegn01Cmn.BattVltgCorrlnBattUnderVltg -> BattVltgCorrln.BattVltgCorrlnBattUnderVltg
    connect CalRegn01Cmn.BattVltgCorrlnNtc0x03C0x044FailStep -> BattVltgCorrln.BattVltgCorrlnNtc0x03C0x044FailStep
    connect CalRegn01Cmn.BattVltgCorrlnNtc0x03C0x044PassStep -> BattVltgCorrln.BattVltgCorrlnNtc0x03C0x044PassStep
    connect CalRegn01Cmn.BattVltgCorrlnNtc0x0B0FailStep -> BattVltgCorrln.BattVltgCorrlnNtc0x0B0FailStep
    connect CalRegn01Cmn.BattVltgCorrlnNtc0x0B0PassStep -> BattVltgCorrln.BattVltgCorrlnNtc0x0B0PassStep
    connect CalRegn01Cmn.BattVltgCorrlnNtc0x0B1FailStep -> BattVltgCorrln.BattVltgCorrlnNtc0x0B1FailStep
    connect CalRegn01Cmn.BattVltgCorrlnNtc0x0B1PassStep -> BattVltgCorrln.BattVltgCorrlnNtc0x0B1PassStep
    connect CalRegn01Cmn.BattVltgCorrlnNtc0x0B5FailStep -> BattVltgCorrln.BattVltgCorrlnNtc0x0B5FailStep
    connect CalRegn01Cmn.BattVltgCorrlnNtc0x0B5PassStep -> BattVltgCorrln.BattVltgCorrlnNtc0x0B5PassStep
    connect CalRegn01Cmn.BattVltgCorrlnRcvrlBattLoVltg -> BattVltgCorrln.BattVltgCorrlnRcvrlBattLoVltg
    connect CalRegn01Cmn.BattVltgCorrlnRcvrlBattOverVltg -> BattVltgCorrln.BattVltgCorrlnRcvrlBattOverVltg
    connect CalRegn01Cmn.BattVltgCorrlnRcvrlBattUnderVltg -> BattVltgCorrln.BattVltgCorrlnRcvrlBattUnderVltg
    connect CalRegn01Cmn.BattVltgCorrlnSwdMax -> BattVltgCorrln.BattVltgCorrlnSwdMax
    connect CalRegn01Cmn.BattVltgCorrlnSysMinVltg -> BattVltgCorrln.BattVltgCorrlnSysMinVltg
    connect CalRegn01Cmn.BmwHwAgArbnAndEotPosnBmwPinionAgOffsLim -> BmwHwAgArbnAndEotPosn.BmwHwAgArbnAndEotPosnBmwPinionAgOffsLim
    connect CalRegn01Cmn.BmwHwAgArbnAndEotPosnBmwPinionAgOffsRateLim -> BmwHwAgArbnAndEotPosn.BmwHwAgArbnAndEotPosnBmwPinionAgOffsRateLim
    connect CalRegn01Cmn.BmwHwAgArbnAndEotPosnMinVehSpdReqdVldAbsPos -> BmwHwAgArbnAndEotPosn.BmwHwAgArbnAndEotPosnMinVehSpdReqdVldAbsPos
    connect CalRegn01Cmn.BmwHwAgArbnAndEotPosnMotPosnDegArbdBlnd -> BmwHwAgArbnAndEotPosn.BmwHwAgArbnAndEotPosnMotPosnDegArbdBlnd
    connect CalRegn01Cmn.BmwHwAgArbnAndEotPosnOffsAuthy -> BmwHwAgArbnAndEotPosn.BmwHwAgArbnAndEotPosnOffsAuthy
    connect CalRegn01Cmn.BmwHwAgArbnAndEotPosnOffsCorrnAuthy -> BmwHwAgArbnAndEotPosn.BmwHwAgArbnAndEotPosnOffsCorrnAuthy
    connect CalRegn01Cmn.BmwHwAgArbnAndEotPosnPinionAgFltTmrThd -> BmwHwAgArbnAndEotPosn.BmwHwAgArbnAndEotPosnPinionAgFltTmrThd
    connect CalRegn01Cmn.BmwHwAgArbnAndEotPosnSysPolarityAssi -> BmwHwAgArbnAndEotPosn.BmwHwAgArbnAndEotPosnSysPolarityAssi
    connect CalRegn01Cmn.BmwHwAgArbnAndEotPosnTmpCmpdAuthy -> BmwHwAgArbnAndEotPosn.BmwHwAgArbnAndEotPosnTmpCmpdAuthy
    connect CalRegn01Cmn.BmwHwAgArbnAndEotPosnTurnCntrAuthy -> BmwHwAgArbnAndEotPosn.BmwHwAgArbnAndEotPosnTurnCntrAuthy
    connect CalRegn01Cmn.BmwHwAgArbnAndEotPosnTurnCntrCorrlnStsTmrThd -> BmwHwAgArbnAndEotPosn.BmwHwAgArbnAndEotPosnTurnCntrCorrlnStsTmrThd
    connect CalRegn01Cmn.BmwMotTqOvrlArbnPullCmpCmdLim -> BmwMotTqOvrlArbn.BmwMotTqOvrlArbnPullCmpCmdLim
    connect CalRegn01Cmn.BmwTunSetHndlrBmwRtIdxDebThd -> BmwTunSetHndlr.BmwTunSetHndlrBmwRtIdxDebThd
    connect CalRegn01Cmn.BmwTunSetHndlrNrOfMotVrnt -> BmwTunSetHndlr.BmwTunSetHndlrNrOfMotVrnt
    connect CalRegn01Cmn.BmwTunSetHndlrNrOfTunSet -> BmwTunSetHndlr.BmwTunSetHndlrNrOfTunSet
    connect CalRegn01Cmn.BmwVehSpdBmwSecurVehSpdStsSigValVldDurnTiVal -> BmwVehSpd.BmwVehSpdBmwSecurVehSpdStsSigValVldDurnTiVal
    connect CalRegn01Cmn.BmwVehSpdNearStillSubVehSpd -> BmwVehSpd.BmwVehSpdNearStillSubVehSpd
    connect CalRegn01Cmn.BmwVehSpdRunngSubVehSpd -> BmwVehSpd.BmwVehSpdRunngSubVehSpd
    connect CalRegn01Cmn.BmwVehSpdSecurVehSpdInvldRateLim -> BmwVehSpd.BmwVehSpdSecurVehSpdInvldRateLim
    connect CalRegn01Cmn.BmwVehSpdSecurVehSpdVldRateLim -> BmwVehSpd.BmwVehSpdSecurVehSpdVldRateLim
    connect CalRegn01Cmn.AdcDiagcNtc0x032FailStep -> CDD_AdcDiagc.AdcDiagcNtc0x032FailStep
    connect CalRegn01Cmn.AdcDiagcNtc0x032PassStep -> CDD_AdcDiagc.AdcDiagcNtc0x032PassStep
    connect CalRegn01Cmn.AdcDiagcNtc0x033FailStep -> CDD_AdcDiagc.AdcDiagcNtc0x033FailStep
    connect CalRegn01Cmn.AdcDiagcNtc0x033PassStep -> CDD_AdcDiagc.AdcDiagcNtc0x033PassStep
    connect CalRegn01Cmn.CurrMeasEolFixdPwmPerd -> CDD_CurrMeas.CurrMeasEolFixdPwmPerd
    connect CalRegn01Cmn.CurrMeasEolGainMax -> CDD_CurrMeas.CurrMeasEolGainMax
    connect CalRegn01Cmn.CurrMeasEolGainMin -> CDD_CurrMeas.CurrMeasEolGainMin
    connect CalRegn01Cmn.CurrMeasEolGainNom -> CDD_CurrMeas.CurrMeasEolGainNom
    connect CalRegn01Cmn.CurrMeasEolGainNrOfSample -> CDD_CurrMeas.CurrMeasEolGainNrOfSample
    connect CalRegn01Cmn.CurrMeasEolGainNumer -> CDD_CurrMeas.CurrMeasEolGainNumer
    connect CalRegn01Cmn.CurrMeasEolMaxMotVel -> CDD_CurrMeas.CurrMeasEolMaxMotVel
    connect CalRegn01Cmn.CurrMeasEolOffsHiBrdgVltgMin -> CDD_CurrMeas.CurrMeasEolOffsHiBrdgVltgMin
    connect CalRegn01Cmn.CurrMeasEolOffsHiCmuOffs -> CDD_CurrMeas.CurrMeasEolOffsHiCmuOffs
    connect CalRegn01Cmn.CurrMeasEolOffsLoCmuOffs -> CDD_CurrMeas.CurrMeasEolOffsLoCmuOffs
    connect CalRegn01Cmn.CurrMeasEolOffsMax -> CDD_CurrMeas.CurrMeasEolOffsMax
    connect CalRegn01Cmn.CurrMeasEolOffsMin -> CDD_CurrMeas.CurrMeasEolOffsMin
    connect CalRegn01Cmn.CurrMeasEolOffsNom -> CDD_CurrMeas.CurrMeasEolOffsNom
    connect CalRegn01Cmn.CurrMeasEolOffsNrOfSample -> CDD_CurrMeas.CurrMeasEolOffsNrOfSample
    connect CalRegn01Cmn.CurrMeasEolTranCntrThd -> CDD_CurrMeas.CurrMeasEolTranCntrThd
    connect CalRegn01Cmn.CurrMeasMinRqrdPhaOnTi -> CDD_CurrMeas.CurrMeasMinRqrdPhaOnTi
    connect CalRegn01Cmn.CurrMeasMotAgCompuDly -> CDD_CurrMeas.CurrMeasMotAgCompuDly
    connect CalRegn01Cmn.CurrMeasMotCurrAdcVlyWrmIninMax -> CDD_CurrMeas.CurrMeasMotCurrAdcVlyWrmIninMax
    connect CalRegn01Cmn.CurrMeasMotCurrAdcVlyWrmIninMin -> CDD_CurrMeas.CurrMeasMotCurrAdcVlyWrmIninMin
    connect CalRegn01Cmn.CurrMeasNtc0x05DFailStep -> CDD_CurrMeas.CurrMeasNtc0x05DFailStep
    connect CalRegn01Cmn.CurrMeasNtc0x05DPassStep -> CDD_CurrMeas.CurrMeasNtc0x05DPassStep
    connect CalRegn01Cmn.SysGlbPrmMotPoleCnt -> CDD_CurrMeas.SysGlbPrmMotPoleCnt
    connect CalRegn01Cmn.CurrMeasArbnMaxStallCntr -> CDD_CurrMeasArbn.CurrMeasArbnMaxStallCntr
    connect CalRegn01Cmn.HwTq4MeasHwTq4PrtclFltFailStep -> CDD_HwTq4Meas.HwTq4MeasHwTq4PrtclFltFailStep
    connect CalRegn01Cmn.HwTq4MeasHwTq4PrtclFltPassStep -> CDD_HwTq4Meas.HwTq4MeasHwTq4PrtclFltPassStep
    connect CalRegn01Cmn.HwTq4MeasHwTqRngHiLim -> CDD_HwTq4Meas.HwTq4MeasHwTqRngHiLim
    connect CalRegn01Cmn.HwTq4MeasHwTqRngLoLim -> CDD_HwTq4Meas.HwTq4MeasHwTqRngLoLim
    connect CalRegn01Cmn.HwTq4MeasMovgAvrgFilEna -> CDD_HwTq4Meas.HwTq4MeasMovgAvrgFilEna
    connect CalRegn01Cmn.HwTq5MeasHwTq5PrtclFltFailStep -> CDD_HwTq5Meas.HwTq5MeasHwTq5PrtclFltFailStep
    connect CalRegn01Cmn.HwTq5MeasHwTq5PrtclFltPassStep -> CDD_HwTq5Meas.HwTq5MeasHwTq5PrtclFltPassStep
    connect CalRegn01Cmn.HwTq5MeasHwTqRngHiLim -> CDD_HwTq5Meas.HwTq5MeasHwTqRngHiLim
    connect CalRegn01Cmn.HwTq5MeasHwTqRngLoLim -> CDD_HwTq5Meas.HwTq5MeasHwTqRngLoLim
    connect CalRegn01Cmn.HwTq5MeasMovgAvrgFilEna -> CDD_HwTq5Meas.HwTq5MeasMovgAvrgFilEna
    connect CalRegn01Cmn.McuDiagc2MilliSecCntrCompThd -> CDD_McuDiagc.McuDiagc2MilliSecCntrCompThd
    connect CalRegn01Cmn.McuDiagcFltFailStep -> CDD_McuDiagc.McuDiagcFltFailStep
    connect CalRegn01Cmn.McuDiagcFltPassStep -> CDD_McuDiagc.McuDiagcFltPassStep
    connect CalRegn01Cmn.MotAg0MeasSnsrIfErrNtcMask -> CDD_MotAg0Meas.MotAg0MeasSnsrIfErrNtcMask
    connect CalRegn01Cmn.MotAg1MeasOffs -> CDD_MotAg1Meas.MotAg1MeasOffs
    connect CalRegn01Cmn.MotAg1MeasSnsrIfErrNtcMask -> CDD_MotAg1Meas.MotAg1MeasSnsrIfErrNtcMask
    connect CalRegn01Cmn.SysGlbPrmMotPoleCnt -> CDD_MotAgCmp.SysGlbPrmMotPoleCnt
    connect CalRegn01Cmn.MotCurrRegCfgCurrLoopSecOrderTrfFctEna -> CDD_MotCurrRegVltgLimr.MotCurrRegCfgCurrLoopSecOrderTrfFctEna
    connect CalRegn01Cmn.MotCurrRegVltgLimrMotCurrPredEna -> CDD_MotCurrRegVltgLimr.MotCurrRegVltgLimrMotCurrPredEna
    connect CalRegn01Cmn.MotCurrRegVltgLimrMotCurrPredTi -> CDD_MotCurrRegVltgLimr.MotCurrRegVltgLimrMotCurrPredTi
    connect CalRegn01Cmn.MotCurrRegVltgLimrMotCurrQaxRefMdfnRplEna -> CDD_MotCurrRegVltgLimr.MotCurrRegVltgLimrMotCurrQaxRefMdfnRplEna
    connect CalRegn01Cmn.MotCurrRegVltgLimrMotVltgBrdgFilEna -> CDD_MotCurrRegVltgLimr.MotCurrRegVltgLimrMotVltgBrdgFilEna
    connect CalRegn01Cmn.MotCurrRegVltgLimrMotVltgQaxFfFilEna -> CDD_MotCurrRegVltgLimr.MotCurrRegVltgLimrMotVltgQaxFfFilEna
    connect CalRegn01Cmn.MotRefMdlFbCtrlDi -> CDD_MotCurrRegVltgLimr.MotRefMdlFbCtrlDi
    connect CalRegn01Cmn.MotRefMdlIvtrDeadTiBrdgVltgSca -> CDD_MotCurrRegVltgLimr.MotRefMdlIvtrDeadTiBrdgVltgSca
    connect CalRegn01Cmn.SinVltgGennDthrEna -> CDD_SinVltgGenn.SinVltgGennDthrEna
    connect CalRegn01Cmn.SinVltgGennDthrLpFilCoeff -> CDD_SinVltgGenn.SinVltgGennDthrLpFilCoeff
    connect CalRegn01Cmn.CurrMeasEolFixdPwmPerd -> CDD_TSG31CfgAndUse.CurrMeasEolFixdPwmPerd
    connect CalRegn01Cmn.CurrMeasEolOffsHiCmuOffs -> CDD_TSG31CfgAndUse.CurrMeasEolOffsHiCmuOffs
    connect CalRegn01Cmn.CurrMeasEolOffsLoCmuOffs -> CDD_TSG31CfgAndUse.CurrMeasEolOffsLoCmuOffs
    connect CalRegn01Cmn.PhaDiscnctFixdPhaOnTi -> CDD_TSG31CfgAndUse.PhaDiscnctFixdPhaOnTi
    connect CalRegn01Cmn.PhaDiscnctFixdPwmPerd -> CDD_TSG31CfgAndUse.PhaDiscnctFixdPwmPerd
    connect CalRegn01Cmn.TSG31CfgAndUseAdcStrtOfCnvn2Offs -> CDD_TSG31CfgAndUse.TSG31CfgAndUseAdcStrtOfCnvn2Offs
    connect CalRegn01Cmn.TSG31CfgAndUseAdcStrtOfCnvnMotCtrlPeakOffs -> CDD_TSG31CfgAndUse.TSG31CfgAndUseAdcStrtOfCnvnMotCtrlPeakOffs
    connect CalRegn01Cmn.TSG31CfgAndUseAdcStrtOfCnvnMotCtrlVlyOffs -> CDD_TSG31CfgAndUse.TSG31CfgAndUseAdcStrtOfCnvnMotCtrlVlyOffs
    connect CalRegn01Cmn.TSG31CfgAndUseMtrAg0SPIStart -> CDD_TSG31CfgAndUse.TSG31CfgAndUseMtrAg0SPIStart
    connect CalRegn01Cmn.TSG31CfgAndUsePwmDbnd -> CDD_TSG31CfgAndUse.TSG31CfgAndUsePwmDbnd
    connect CalRegn01Cmn.CmnMfgSrvSecuAcsAtmptTiOut -> CmnMfgSrv.CmnMfgSrvSecuAcsAtmptTiOut
    connect CalRegn01Cmn.CmnMfgSrvSecuAcsMaxNrAtmpt -> CmnMfgSrv.CmnMfgSrvSecuAcsMaxNrAtmpt
    connect CalRegn01Cmn.CmplncErrHwAgNonLinCmplncDepTblY -> CmplncErr.CmplncErrHwAgNonLinCmplncDepTblY
    connect CalRegn01Cmn.CmplncErrHwAgNonLinCmplncIndTblX -> CmplncErr.CmplncErrHwAgNonLinCmplncIndTblX
    connect CalRegn01Cmn.CmplncErrMotAgNonLinCmplncDepTblY -> CmplncErr.CmplncErrMotAgNonLinCmplncDepTblY
    connect CalRegn01Cmn.CmplncErrMotAgNonLinCmplncIndTblX -> CmplncErr.CmplncErrMotAgNonLinCmplncIndTblX
    connect CalRegn01Cmn.CurrMeasCorrlnMaxErrCurr -> CurrMeasCorrln.CurrMeasCorrlnMaxErrCurr
    connect CalRegn01Cmn.CurrMeasCorrlnMaxStallCntr -> CurrMeasCorrln.CurrMeasCorrlnMaxStallCntr
    connect CalRegn01Cmn.CurrMeasCorrlnNtc0x04DFailStep -> CurrMeasCorrln.CurrMeasCorrlnNtc0x04DFailStep
    connect CalRegn01Cmn.CurrMeasCorrlnNtc0x04DPassStep -> CurrMeasCorrln.CurrMeasCorrlnNtc0x04DPassStep
    connect CalRegn01Cmn.DiagcMgrFltResp -> DiagcMgr.DiagcMgrFltResp
    connect CalRegn01Cmn.DiagcMgrFltResp -> DiagcMgrProxyAppl10.DiagcMgrFltResp
    connect CalRegn01Cmn.DiagcMgrFltResp -> DiagcMgrProxyAppl{7..9}.DiagcMgrFltResp
    connect CalRegn01Cmn.ElecPwrCnsCtrlrInpR -> ElecPwrCns.ElecPwrCnsCtrlrInpR
    connect CalRegn01Cmn.GateDrv0CtrlErrFilFrq -> GateDrv0Ctrl.GateDrv0CtrlErrFilFrq
    connect CalRegn01Cmn.GateDrv0CtrlErrOffs -> GateDrv0Ctrl.GateDrv0CtrlErrOffs
    connect CalRegn01Cmn.GateDrv0CtrlErrThd -> GateDrv0Ctrl.GateDrv0CtrlErrThd
    connect CalRegn01Cmn.GateDrv0CtrlNtcNr0x050FailStep -> GateDrv0Ctrl.GateDrv0CtrlNtcNr0x050FailStep
    connect CalRegn01Cmn.GateDrv0CtrlNtcNr0x050PassStep -> GateDrv0Ctrl.GateDrv0CtrlNtcNr0x050PassStep
    connect CalRegn01Cmn.GateDrv0CtrlNtcNr0x051FailStep -> GateDrv0Ctrl.GateDrv0CtrlNtcNr0x051FailStep
    connect CalRegn01Cmn.GateDrv0CtrlNtcNr0x051PassStep -> GateDrv0Ctrl.GateDrv0CtrlNtcNr0x051PassStep
    connect CalRegn01Cmn.GateDrv0CtrlNtcNr0x055FailStep -> GateDrv0Ctrl.GateDrv0CtrlNtcNr0x055FailStep
    connect CalRegn01Cmn.GateDrv0CtrlNtcNr0x055PassStep -> GateDrv0Ctrl.GateDrv0CtrlNtcNr0x055PassStep
    connect CalRegn01Cmn.GateDrv0CtrlUnit0Cfg{2..4}WrVal -> GateDrv0Ctrl.GateDrv0CtrlUnit0Cfg{2..4}WrVal
    connect CalRegn01Cmn.GateDrv0CtrlUnit0Cfg7WrVal -> GateDrv0Ctrl.GateDrv0CtrlUnit0Cfg7WrVal
    connect CalRegn01Cmn.HiLoadStallLimrMotTqCmdFetMtgtnEnaFilFrq -> HiLoadStallLimr.HiLoadStallLimrMotTqCmdFetMtgtnEnaFilFrq
    connect CalRegn01Cmn.HiLoadStallLimrMotTqCmdFilFrq -> HiLoadStallLimr.HiLoadStallLimrMotTqCmdFilFrq
    connect CalRegn01Cmn.HwTqCorrlnChACmnModCmpLpFilActvnThd -> HwTqCorrln.HwTqCorrlnChACmnModCmpLpFilActvnThd
    connect CalRegn01Cmn.HwTqCorrlnChACmnModCmpLpFilFrq -> HwTqCorrln.HwTqCorrlnChACmnModCmpLpFilFrq
    connect CalRegn01Cmn.HwTqCorrlnChACmnModCmpLpFilOutpLim -> HwTqCorrln.HwTqCorrlnChACmnModCmpLpFilOutpLim
    connect CalRegn01Cmn.HwTqCorrlnChAImdtCorrlnChkFailThd -> HwTqCorrln.HwTqCorrlnChAImdtCorrlnChkFailThd
    connect CalRegn01Cmn.HwTqCorrlnChAImdtCorrlnChkPassThd -> HwTqCorrln.HwTqCorrlnChAImdtCorrlnChkPassThd
    connect CalRegn01Cmn.HwTqCorrlnChAStabStClrFltThd -> HwTqCorrln.HwTqCorrlnChAStabStClrFltThd
    connect CalRegn01Cmn.HwTqCorrlnChAStabStLpFilFrq -> HwTqCorrln.HwTqCorrlnChAStabStLpFilFrq
    connect CalRegn01Cmn.HwTqCorrlnChAStabStSetFltThd -> HwTqCorrln.HwTqCorrlnChAStabStSetFltThd
    connect CalRegn01Cmn.HwTqCorrlnChATqSumMaxLim -> HwTqCorrln.HwTqCorrlnChATqSumMaxLim
    connect CalRegn01Cmn.HwTqCorrlnChATraLpFilX -> HwTqCorrln.HwTqCorrlnChATraLpFilX
    connect CalRegn01Cmn.HwTqCorrlnChATraLpFilY -> HwTqCorrln.HwTqCorrlnChATraLpFilY
    connect CalRegn01Cmn.HwTqCorrlnChATraSumClrFltThd -> HwTqCorrln.HwTqCorrlnChATraSumClrFltThd
    connect CalRegn01Cmn.HwTqCorrlnChATraSumSetFltThd -> HwTqCorrln.HwTqCorrlnChATraSumSetFltThd
    connect CalRegn01Cmn.SysGlbPrmTorsBarStfn -> InertiaCmpVel.SysGlbPrmTorsBarStfn
    connect CalRegn01Cmn.LimrCdngGainDecSlew -> LimrCdng.LimrCdngGainDecSlew
    connect CalRegn01Cmn.LimrCdngGainIncSlewX -> LimrCdng.LimrCdngGainIncSlewX
    connect CalRegn01Cmn.LimrCdngGainIncSlewY -> LimrCdng.LimrCdngGainIncSlewY
    connect CalRegn01Cmn.LimrCdngTqDecSlew -> LimrCdng.LimrCdngTqDecSlew
    connect CalRegn01Cmn.LimrCdngTqIncSlewX -> LimrCdng.LimrCdngTqIncSlewX
    connect CalRegn01Cmn.LimrCdngTqIncSlewY -> LimrCdng.LimrCdngTqIncSlewY
    connect CalRegn01Cmn.LoaMgrCurrIvtrMtgtnRate -> LoaMgr.LoaMgrCurrIvtrMtgtnRate
    connect CalRegn01Cmn.LoaMgrCurrIvtrMtgtnSca -> LoaMgr.LoaMgrCurrIvtrMtgtnSca
    connect CalRegn01Cmn.LoaMgrCurrIvtrMtgtnScaZeroEna -> LoaMgr.LoaMgrCurrIvtrMtgtnScaZeroEna
    connect CalRegn01Cmn.LoaMgrCurrMeasIdptSig{0..2}Resp -> LoaMgr.LoaMgrCurrMeasIdptSig{0..2}Resp
    connect CalRegn01Cmn.LoaMgrCurrMeasIdptSigFltThd -> LoaMgr.LoaMgrCurrMeasIdptSigFltThd
    connect CalRegn01Cmn.LoaMgrCurrMeasMtgtnRate -> LoaMgr.LoaMgrCurrMeasMtgtnRate
    connect CalRegn01Cmn.LoaMgrCurrMeasMtgtnSca -> LoaMgr.LoaMgrCurrMeasMtgtnSca
    connect CalRegn01Cmn.LoaMgrCurrMeasMtgtnScaZeroEna -> LoaMgr.LoaMgrCurrMeasMtgtnScaZeroEna
    connect CalRegn01Cmn.LoaMgrFadeOutStRate -> LoaMgr.LoaMgrFadeOutStRate
    connect CalRegn01Cmn.LoaMgrHwTqIdptSig0NoTqLoaResp -> LoaMgr.LoaMgrHwTqIdptSig0NoTqLoaResp
    connect CalRegn01Cmn.LoaMgrHwTqIdptSig1NoTqLoaResp -> LoaMgr.LoaMgrHwTqIdptSig1NoTqLoaResp
    connect CalRegn01Cmn.LoaMgrHwTqIdptSig{2..4}Resp -> LoaMgr.LoaMgrHwTqIdptSig{2..4}Resp
    connect CalRegn01Cmn.LoaMgrHwTqIdptSigFltThd -> LoaMgr.LoaMgrHwTqIdptSigFltThd
    connect CalRegn01Cmn.LoaMgrHwTqLoaAvlResp -> LoaMgr.LoaMgrHwTqLoaAvlResp
    connect CalRegn01Cmn.LoaMgrIvtrIdptSig{0..2}Resp -> LoaMgr.LoaMgrIvtrIdptSig{0..2}Resp
    connect CalRegn01Cmn.LoaMgrIvtrIdptSigFltThd -> LoaMgr.LoaMgrIvtrIdptSigFltThd
    connect CalRegn01Cmn.LoaMgrIvtrMtgtnRate -> LoaMgr.LoaMgrIvtrMtgtnRate
    connect CalRegn01Cmn.LoaMgrIvtrMtgtnSca -> LoaMgr.LoaMgrIvtrMtgtnSca
    connect CalRegn01Cmn.LoaMgrIvtrMtgtnScaZeroEna -> LoaMgr.LoaMgrIvtrMtgtnScaZeroEna
    connect CalRegn01Cmn.LoaMgrLimdStRate -> LoaMgr.LoaMgrLimdStRate
    connect CalRegn01Cmn.LoaMgrLimdStSca -> LoaMgr.LoaMgrLimdStSca
    connect CalRegn01Cmn.LoaMgrMotAgAvlSnsrlsResp -> LoaMgr.LoaMgrMotAgAvlSnsrlsResp
    connect CalRegn01Cmn.LoaMgrMotAgIdptSig0NoSnsrlsResp -> LoaMgr.LoaMgrMotAgIdptSig0NoSnsrlsResp
    connect CalRegn01Cmn.LoaMgrMotAgIdptSig1NoSnsrlsResp -> LoaMgr.LoaMgrMotAgIdptSig1NoSnsrlsResp
    connect CalRegn01Cmn.LoaMgrMotAgIdptSig2Resp -> LoaMgr.LoaMgrMotAgIdptSig2Resp
    connect CalRegn01Cmn.LoaMgrMotAgIdptSig3Resp -> LoaMgr.LoaMgrMotAgIdptSig3Resp
    connect CalRegn01Cmn.LoaMgrMotAgIdptSigFltThd -> LoaMgr.LoaMgrMotAgIdptSigFltThd
    connect CalRegn01Cmn.LoaMgrMotAgMtgtnRate -> LoaMgr.LoaMgrMotAgMtgtnRate
    connect CalRegn01Cmn.LoaMgrMotAgMtgtnSca -> LoaMgr.LoaMgrMotAgMtgtnSca
    connect CalRegn01Cmn.LoaMgrMotAgMtgtnScaZeroEna -> LoaMgr.LoaMgrMotAgMtgtnScaZeroEna
    connect CalRegn01Cmn.LrndRackCentrAllwManIniLrng -> LrndRackCentr.LrndRackCentrAllwManIniLrng
    connect CalRegn01Cmn.LrndRackCentrConfTrvlThd -> LrndRackCentr.LrndRackCentrConfTrvlThd
    connect CalRegn01Cmn.LrndRackCentrHwAgFilFrq -> LrndRackCentr.LrndRackCentrHwAgFilFrq
    connect CalRegn01Cmn.LrndRackCentrMinMaxAdjmtFac -> LrndRackCentr.LrndRackCentrMinMaxAdjmtFac
    connect CalRegn01Cmn.LrndRackCentrRackCentrPosnChgAllwd -> LrndRackCentr.LrndRackCentrRackCentrPosnChgAllwd
    connect CalRegn01Cmn.LrndRackCentrTiThd -> LrndRackCentr.LrndRackCentrTiThd
    connect CalRegn01Cmn.LrnPinionCentrDampgCtrlGain -> LrnPinionCentr.LrnPinionCentrDampgCtrlGain
    connect CalRegn01Cmn.LrnPinionCentrHldTq -> LrnPinionCentr.LrnPinionCentrHldTq
    connect CalRegn01Cmn.LrnPinionCentrHldTqErrThd -> LrnPinionCentr.LrnPinionCentrHldTqErrThd
    connect CalRegn01Cmn.LrnPinionCentrHldTqRateLim -> LrnPinionCentr.LrnPinionCentrHldTqRateLim
    connect CalRegn01Cmn.LrnPinionCentrHwPosnErrThd -> LrnPinionCentr.LrnPinionCentrHwPosnErrThd
    connect CalRegn01Cmn.LrnPinionCentrIntglCtrlGain -> LrnPinionCentr.LrnPinionCentrIntglCtrlGain
    connect CalRegn01Cmn.LrnPinionCentrMaxTqCmd -> LrnPinionCentr.LrnPinionCentrMaxTqCmd
    connect CalRegn01Cmn.LrnPinionCentrMinMotTq -> LrnPinionCentr.LrnPinionCentrMinMotTq
    connect CalRegn01Cmn.LrnPinionCentrMotVelThd -> LrnPinionCentr.LrnPinionCentrMotVelThd
    connect CalRegn01Cmn.LrnPinionCentrPropCtrlGain -> LrnPinionCentr.LrnPinionCentrPropCtrlGain
    connect CalRegn01Cmn.LrnPinionCentrTiOutThd -> LrnPinionCentr.LrnPinionCentrTiOutThd
    connect CalRegn01Cmn.LrnPinionCentrTiThd -> LrnPinionCentr.LrnPinionCentrTiThd
    connect CalRegn01Cmn.SysGlbPrmMotPoleCnt -> MotAgCorrln.SysGlbPrmMotPoleCnt
    connect CalRegn01Cmn.MotCtrlPrmEstimnFetThermCoeff -> MotCtrlPrmEstimn.MotCtrlPrmEstimnFetThermCoeff
    connect CalRegn01Cmn.MotCtrlPrmEstimnMagThermCoeff -> MotCtrlPrmEstimn.MotCtrlPrmEstimnMagThermCoeff
    connect CalRegn01Cmn.MotCurrRegCfgCtrlrDynGainVehSpdCutOff -> MotCurrRegCfg.MotCurrRegCfgCtrlrDynGainVehSpdCutOff
    connect CalRegn01Cmn.MotCurrRegCfgCurrLoopSecOrderTrfFctEna -> MotCurrRegCfg.MotCurrRegCfgCurrLoopSecOrderTrfFctEna
    connect CalRegn01Cmn.MotCurrRegCfgIntglGainSampleTi -> MotCurrRegCfg.MotCurrRegCfgIntglGainSampleTi
    connect CalRegn01Cmn.MotCurrRegCfgMotAgCompuDly -> MotCurrRegCfg.MotCurrRegCfgMotAgCompuDly
    connect CalRegn01Cmn.MotCurrRegCfgMotCtrlPrmSelnX -> MotCurrRegCfg.MotCurrRegCfgMotCtrlPrmSelnX
    connect CalRegn01Cmn.MotRefMdlFbCtrlDi -> MotCurrRegCfg.MotRefMdlFbCtrlDi
    connect CalRegn01Cmn.SysGlbPrmMotPoleCnt -> MotCurrRegCfg.SysGlbPrmMotPoleCnt
    connect CalRegn01Cmn.MotQuadDetnMotDirHysInsts -> MotQuadDetn.MotQuadDetnMotDirHysInsts
    connect CalRegn01Cmn.MotRefMdlFbCtrlDi -> MotRefMdl.MotRefMdlFbCtrlDi
    connect CalRegn01Cmn.MotRefMdlIvtrDeadTiBrdgVltgSca -> MotRefMdl.MotRefMdlIvtrDeadTiBrdgVltgSca
    connect CalRegn01Cmn.MotRefMdlMinCurrItrnLim -> MotRefMdl.MotRefMdlMinCurrItrnLim
    connect CalRegn01Cmn.MotRefMdlMotVelLpFilFrq -> MotRefMdl.MotRefMdlMotVelLpFilFrq
    connect CalRegn01Cmn.MotRefMdlMotVltgDerivtvTiCon -> MotRefMdl.MotRefMdlMotVltgDerivtvTiCon
    connect CalRegn01Cmn.MotRefMdlRefLocnItrnLim -> MotRefMdl.MotRefMdlRefLocnItrnLim
    connect CalRegn01Cmn.MotRefMdlTqItrnLim -> MotRefMdl.MotRefMdlTqItrnLim
    connect CalRegn01Cmn.MotRefMdlTqItrnTolr -> MotRefMdl.MotRefMdlTqItrnTolr
    connect CalRegn01Cmn.MotRefMdlVltgModDynCmpEna -> MotRefMdl.MotRefMdlVltgModDynCmpEna
    connect CalRegn01Cmn.SysGlbPrmMotPoleCnt -> MotRefMdl.SysGlbPrmMotPoleCnt
    connect CalRegn01Cmn.SysGlbPrmMotPoleCnt -> MotTqCalcd.SysGlbPrmMotPoleCnt
    connect CalRegn01Cmn.MotTqCmdScaMax -> MotTqCmdSca.MotTqCmdScaMax
    connect CalRegn01Cmn.MotTqCmdScaMin -> MotTqCmdSca.MotTqCmdScaMin
    connect CalRegn01Cmn.MotTqTranlDampgDampgCoeff -> MotTqTranlDampg.MotTqTranlDampgDampgCoeff
    connect CalRegn01Cmn.MotTqTranlDampgRampEnd -> MotTqTranlDampg.MotTqTranlDampgRampEnd
    connect CalRegn01Cmn.MotTqTranlDampgTmrPt1 -> MotTqTranlDampg.MotTqTranlDampgTmrPt1
    connect CalRegn01Cmn.MotTqTranlDampgTmrPt2 -> MotTqTranlDampg.MotTqTranlDampgTmrPt2
    connect CalRegn01Cmn.MotTqTranlDampgVehSpdBlndX -> MotTqTranlDampg.MotTqTranlDampgVehSpdBlndX
    connect CalRegn01Cmn.MotTqTranlDampgVehSpdBlndY -> MotTqTranlDampg.MotTqTranlDampgVehSpdBlndY
    connect CalRegn01Cmn.NxtrCalIdsCal0DevlpAuthor -> NxtrCalIds.NxtrCalIdsCal0DevlpAuthor
    connect CalRegn01Cmn.NxtrCalIdsCal0DevlpDesc -> NxtrCalIds.NxtrCalIdsCal0DevlpDescr
    connect CalRegn01Cmn.NxtrCalIdsCal0DevlpRelNr -> NxtrCalIds.NxtrCalIdsCal0DevlpRelNr
    connect CalRegn01Cmn.NxtrCalIdsCal0DevlpRelSt -> NxtrCalIds.NxtrCalIdsCal0DevlpRelSt
    connect CalRegn01Cmn.NxtrCalIdsCal0DevlpTiStamp -> NxtrCalIds.NxtrCalIdsCal0DevlpTiStamp
    connect CalRegn01Cmn.NxtrCalIdsCal0DevlpVers -> NxtrCalIds.NxtrCalIdsCal0DevlpVers
    connect CalRegn01Cmn.NxtrCalIdsCal1DevlpAuthor -> NxtrCalIds.NxtrCalIdsCal1DevlpAuthor
    connect CalRegn01Cmn.NxtrCalIdsCal1DevlpDesc -> NxtrCalIds.NxtrCalIdsCal1DevlpDescr
    connect CalRegn01Cmn.NxtrCalIdsCal1DevlpRelNr -> NxtrCalIds.NxtrCalIdsCal1DevlpRelNr
    connect CalRegn01Cmn.NxtrCalIdsCal1DevlpRelSt -> NxtrCalIds.NxtrCalIdsCal1DevlpRelSt
    connect CalRegn01Cmn.NxtrCalIdsCal1DevlpTiStamp -> NxtrCalIds.NxtrCalIdsCal1DevlpTiStamp
    connect CalRegn01Cmn.NxtrCalIdsCal1DevlpVers -> NxtrCalIds.NxtrCalIdsCal1DevlpVers
    connect CalRegn01Cmn.NxtrCalIdsCal2DevlpAuthor -> NxtrCalIds.NxtrCalIdsCal2DevlpAuthor
    connect CalRegn01Cmn.NxtrCalIdsCal2DevlpDesc -> NxtrCalIds.NxtrCalIdsCal2DevlpDescr
    connect CalRegn01Cmn.NxtrCalIdsCal2DevlpRelNr -> NxtrCalIds.NxtrCalIdsCal2DevlpRelNr
    connect CalRegn01Cmn.NxtrCalIdsCal2DevlpRelSt -> NxtrCalIds.NxtrCalIdsCal2DevlpRelSt
    connect CalRegn01Cmn.NxtrCalIdsCal2DevlpTiStamp -> NxtrCalIds.NxtrCalIdsCal2DevlpTiStamp
    connect CalRegn01Cmn.NxtrCalIdsCal2DevlpVers -> NxtrCalIds.NxtrCalIdsCal2DevlpVers
    connect CalRegn01Cmn.PhaDiscnctClsDlyTi -> PhaDiscnct.PhaDiscnctClsDlyTi
    connect CalRegn01Cmn.PhaDiscnctFixdPhaOnTi -> PhaDiscnct.PhaDiscnctFixdPhaOnTi
    connect CalRegn01Cmn.PhaDiscnctFixdPwmPerd -> PhaDiscnct.PhaDiscnctFixdPwmPerd
    connect CalRegn01Cmn.PhaDiscnctOpenDlyTi -> PhaDiscnct.PhaDiscnctOpenDlyTi
    connect CalRegn01Cmn.PhaDiscnctTestCurrTestVal -> PhaDiscnct.PhaDiscnctTestCurrTestVal
    connect CalRegn01Cmn.PhaDiscnctTestFailScanMax -> PhaDiscnct.PhaDiscnctTestFailScanMax
    connect CalRegn01Cmn.PhaDiscnctTestIninScan -> PhaDiscnct.PhaDiscnctTestIninScan
    connect CalRegn01Cmn.PhaDiscnctTestScanCnt -> PhaDiscnct.PhaDiscnctTestScanCnt
    connect CalRegn01Cmn.PosnTrakgServoHwAgTarRateLimTblY -> PosnTrakgServo.PosnTrakgServoHwAgTarRateLimTblY
    connect CalRegn01Cmn.PosnTrakgServoHwVelTarRateLimTblY -> PosnTrakgServo.PosnTrakgServoHwVelTarRateLimTblY
    connect CalRegn01Cmn.PosnTrakgServoIntglLim -> PosnTrakgServo.PosnTrakgServoIntglLim
    connect CalRegn01Cmn.PosnTrakgServoIntgtrAntiWdupGain -> PosnTrakgServo.PosnTrakgServoIntgtrAntiWdupGain
    connect CalRegn01Cmn.PosnTrakgServoIntgtrStCorrnGain -> PosnTrakgServo.PosnTrakgServoIntgtrStCorrnGain
    connect CalRegn01Cmn.PosnTrakgServoLpFilCutOffFrq -> PosnTrakgServo.PosnTrakgServoLpFilCutOffFrq
    connect CalRegn01Cmn.PosnTrakgServoOutpAntiWdupGain -> PosnTrakgServo.PosnTrakgServoOutpAntiWdupGain
    connect CalRegn01Cmn.PosnTrakgServoOutpLim -> PosnTrakgServo.PosnTrakgServoOutpLim
    connect CalRegn01Cmn.PwrLimrSplyCurrLimTblX -> PwrLimr.PwrLimrSplyCurrLimTblX
    connect CalRegn01Cmn.PwrLimrSplyCurrLimTblY -> PwrLimr.PwrLimrSplyCurrLimTblY
    connect CalRegn01Cmn.PwrSplyNtc0x07BFailStep -> PwrSply.PwrSplyNtc0x07BFailStep
    connect CalRegn01Cmn.PwrSplyNtc0x07BPassStep -> PwrSply.PwrSplyNtc0x07BPassStep
    connect CalRegn01Cmn.PwrSplyNtc0x07CFailStep -> PwrSply.PwrSplyNtc0x07CFailStep
    connect CalRegn01Cmn.PwrSplyNtc0x07CPassStep -> PwrSply.PwrSplyNtc0x07CPassStep
    connect CalRegn01Cmn.PwrSplyNtc0x07DFailStep -> PwrSply.PwrSplyNtc0x07DFailStep
    connect CalRegn01Cmn.PwrSplyNtc0x07DPassStep -> PwrSply.PwrSplyNtc0x07DPassStep
    connect CalRegn01Cmn.SysKineAndEffCmplncErrDerivtvCutOffFrq -> SysKineAndEff.SysKineAndEffCmplncErrDerivtvCutOffFrq
    connect CalRegn01Cmn.SysKineAndEffMotAgScaX -> SysKineAndEff.SysKineAndEffMotAgScaX
    connect CalRegn01Cmn.SysKineAndEffMotToRackEffScaY -> SysKineAndEff.SysKineAndEffMotToRackEffScaY
    connect CalRegn01Cmn.SysKineAndEffRackPosScaY -> SysKineAndEff.SysKineAndEffRackPosScaY
    connect CalRegn01Cmn.TEstimnIgnOffCtrlEna -> TEstimn.TEstimnIgnOffCtrlEna
    connect CalRegn01Cmn.TEstimnIgnOffMsgWaitTi -> TEstimn.TEstimnIgnOffMsgWaitTi
    connect CalRegn01Cmn.TqOscnAmpLimY -> TqOscn.TqOscnAmpLimY
    connect CalRegn01Cmn.TqOscnFallRampRateCal -> TqOscn.TqOscnFallRampRateCal
    connect CalRegn01Cmn.TqOscnFrqIn -> TqOscn.TqOscnFrqIn
    connect CalRegn01Cmn.TqOscnRisngRampRateCal -> TqOscn.TqOscnRisngRampRateCal
    connect CalRegn01Cmn.TqOscnUseRampRateCal -> TqOscn.TqOscnUseRampRateCal
    connect CalRegn01Cmn.TunSelnAuthyHwTqY -> TunSelnAuthy.TunSelnAuthyHwTqY
    connect CalRegn01Cmn.TunSelnAuthyHwVelY -> TunSelnAuthy.TunSelnAuthyHwVelY
    connect CalRegn01Cmn.TunSelnAuthyTunSelnRtDiCmd -> TunSelnAuthy.TunSelnAuthyTunSelnRtDiCmd
    connect CalRegn01Cmn.VehSigCdngDftLatA -> VehSigCdng.VehSigCdngDftLatA
    connect CalRegn01Cmn.VehSigCdngDftLgtA -> VehSigCdng.VehSigCdngDftLgtA
    connect CalRegn01Cmn.VehSigCdngDftVehSpd -> VehSigCdng.VehSigCdngDftVehSpd
    connect CalRegn01Cmn.VehSigCdngDftYawRate -> VehSigCdng.VehSigCdngDftYawRate
    connect CalRegn01Cmn.VehSigCdngLatADifThd -> VehSigCdng.VehSigCdngLatADifThd
    connect CalRegn01Cmn.VehSigCdngLatAFilFrq -> VehSigCdng.VehSigCdngLatAFilFrq
    connect CalRegn01Cmn.VehSigCdngLatASlewRate -> VehSigCdng.VehSigCdngLatASlewRate
    connect CalRegn01Cmn.VehSigCdngLtgADifThd -> VehSigCdng.VehSigCdngLtgADifThd
    connect CalRegn01Cmn.VehSigCdngLtgASlewRate -> VehSigCdng.VehSigCdngLtgASlewRate
    connect CalRegn01Cmn.VehSigCdngVehSpdDifThd -> VehSigCdng.VehSigCdngVehSpdDifThd
    connect CalRegn01Cmn.VehSigCdngVehSpdSlewRate -> VehSigCdng.VehSigCdngVehSpdSlewRate
    connect CalRegn01Cmn.VehSigCdngVehYawSlewRate -> VehSigCdng.VehSigCdngVehYawSlewRate
    connect CalRegn01Cmn.VehSigCdngYawRateDifThd -> VehSigCdng.VehSigCdngYawRateDifThd
    connect CalRegn01Cmn.VehSpdLimrMaxAssiX -> VehSpdLimr.VehSpdLimrMaxAssiX
    connect CalRegn01Cmn.VehSpdLimrMaxAssiY -> VehSpdLimr.VehSpdLimrMaxAssiY
    connect CalRegn01Cmn.VehSpdLimrPosMaxOffs1 -> VehSpdLimr.VehSpdLimrPosMaxOffs1
    connect CalRegn01CmnGroupA.BmwHwAgArbnAndEotPosnAllwExitFromInit -> BmwHwAgArbnAndEotPosn.BmwHwAgArbnAndEotPosnAllwExitFromInit
    connect CalRegn01CmnGroupA.BmwHwAgArbnAndEotPosnMotToHwResl -> BmwHwAgArbnAndEotPosn.BmwHwAgArbnAndEotPosnMotToHwResl
    connect CalRegn01CmnGroupA.BmwHwAgArbnAndEotPosnOffsCorrnTmrThd -> BmwHwAgArbnAndEotPosn.BmwHwAgArbnAndEotPosnOffsCorrnTmrThd
    connect CalRegn01CmnGroupA.BmwHwAgArbnAndEotPosnPinionAgConfRampDwnRate -> BmwHwAgArbnAndEotPosn.BmwHwAgArbnAndEotPosnPinionAgConfRampDwnRate
    connect CalRegn01CmnGroupA.BmwHwAgArbnAndEotPosnPinionAgConfRampUpRate -> BmwHwAgArbnAndEotPosn.BmwHwAgArbnAndEotPosnPinionAgConfRampUpRate
    connect CalRegn01CmnGroupA.BmwHwAgArbnAndEotPosnPinionAgDifThd -> BmwHwAgArbnAndEotPosn.BmwHwAgArbnAndEotPosnPinionAgDifThd
    connect CalRegn01CmnGroupA.BmwHwAgArbnAndEotPosnPinionAgFilFrq -> BmwHwAgArbnAndEotPosn.BmwHwAgArbnAndEotPosnPinionAgFilFrq
    connect CalRegn01CmnGroupA.BmwPwrPrkgDampgMinPinionAgConf -> BmwPwrPrkgDampg.BmwPwrPrkgDampgMinPinionAgConf
    connect CalRegn01CmnGroupA.BmwStReqMgrVehCdnOvrd -> BmwStReqMgr.BmwStReqMgrVehCdnOvrd
    connect CalRegn01CmnGroupA.BmwSwFctDiBmwActvRtnOvrd -> BmwSwFctDi.BmwSwFctDiBmwActvRtnOvrd
    connect CalRegn01CmnGroupA.BmwSwFctDiBmwEngStrtStopOvrd -> BmwSwFctDi.BmwSwFctDiBmwEngStrtStopOvrd
    connect CalRegn01CmnGroupA.BmwSwFctDiBmwEpsOscnOvrd -> BmwSwFctDi.BmwSwFctDiBmwEpsOscnOvrd
    connect CalRegn01CmnGroupA.BmwSwFctDiBmwFricCmpOvrd -> BmwSwFctDi.BmwSwFctDiBmwFricCmpOvrd
    connect CalRegn01CmnGroupA.BmwSwFctDiBmwGearInertiaCmpOvrd -> BmwSwFctDi.BmwSwFctDiBmwGearInertiaCmpOvrd
    connect CalRegn01CmnGroupA.BmwSwFctDiBmwHwInertiaCmpOvrd -> BmwSwFctDi.BmwSwFctDiBmwHwInertiaCmpOvrd
    connect CalRegn01CmnGroupA.BmwSwFctDiBmwHysActvInflOvrd -> BmwSwFctDi.BmwSwFctDiBmwHysActvInflOvrd
    connect CalRegn01CmnGroupA.BmwSwFctDiBmwIfNegDampgOvrd -> BmwSwFctDi.BmwSwFctDiBmwIfNegDampgOvrd
    connect CalRegn01CmnGroupA.BmwSwFctDiBmwIfNegFacOvrd -> BmwSwFctDi.BmwSwFctDiBmwIfNegFacOvrd
    connect CalRegn01CmnGroupA.BmwSwFctDiBmwIfNegHwTqOvrd -> BmwSwFctDi.BmwSwFctDiBmwIfNegHwTqOvrd
    connect CalRegn01CmnGroupA.BmwSwFctDiBmwIfNegMotTqOvrd -> BmwSwFctDi.BmwSwFctDiBmwIfNegMotTqOvrd
    connect CalRegn01CmnGroupA.BmwSwFctDiBmwLrnSwtOvrd -> BmwSwFctDi.BmwSwFctDiBmwLrnSwtOvrd
    connect CalRegn01CmnGroupA.BmwSwFctDiBmwPrkgPwrDampgOvrd -> BmwSwFctDi.BmwSwFctDiBmwPrkgPwrDampgOvrd
    connect CalRegn01CmnGroupA.BmwSwFctDiBmwPullCmpOvrd -> BmwSwFctDi.BmwSwFctDiBmwPullCmpOvrd
    connect CalRegn01CmnGroupA.BmwSwFctDiCodingOvrd -> BmwSwFctDi.BmwSwFctDiCodingOvrd
    connect CalRegn01CmnGroupA.BmwSwFctDiMaxCurrAtHiSpdOvrd -> BmwSwFctDi.BmwSwFctDiMaxCurrAtHiSpdOvrd
    connect CalRegn01CmnGroupA.BmwSwFctDiMaxCurrAtLoSpdOvrd -> BmwSwFctDi.BmwSwFctDiMaxCurrAtLoSpdOvrd
    connect CalRegn01CmnGroupA.BmwTunSetHndlrCptDisadOutp -> BmwTunSetHndlr.BmwTunSetHndlrCptDisadOutp
    connect CalRegn01CmnGroupA.BmwTunSetHndlrOvrdDesRtIdx -> BmwTunSetHndlr.BmwTunSetHndlrOvrdDesRtIdx
    connect CalRegn01CmnGroupA.ElecPwrCnsPrstcPwrLoss -> ElecPwrCns.ElecPwrCnsPrstcPwrLoss
    connect CalRegn01CmnGroupA.HwTqTrakgCtrlMotTqCmdOvrlGain -> HwTqTrakgCtrl.HwTqTrakgCtrlMotTqCmdOvrlGain
    connect CalRegn01CmnGroupA.PosnTrakgServoFfGain -> PosnTrakgServo.PosnTrakgServoFfGain
    connect CalRegn01CmnGroupA.PosnTrakgServoFfVelGain -> PosnTrakgServo.PosnTrakgServoFfVelGain
    connect CalRegn01CmnGroupA.PosnTrakgServoGain{1..4} -> PosnTrakgServo.PosnTrakgServoGain{1..4}
    connect CalRegn01CmnGroupA.PosnTrakgServoHwAgTarMgnLimTblY -> PosnTrakgServo.PosnTrakgServoHwAgTarMgnLimTblY
    connect CalRegn01CmnGroupA.PosnTrakgServoIntglGain -> PosnTrakgServo.PosnTrakgServoIntglGain
    connect CalRegn01CmnGroupA.PosnTrakgServoVehSpdTbl -> PosnTrakgServo.PosnTrakgServoVehSpdTbl
    connect CalRegn01CmnGroupB.BmwDrvgDynStMacAssiLvlThd -> BmwDrvgDynStMac.BmwDrvgDynStMacAssiLvlThd
    connect CalRegn01CmnGroupB.BmwDrvgDynStMacDampgCmdScaDft -> BmwDrvgDynStMac.BmwDrvgDynStMacDampgCmdScaDft
    connect CalRegn01CmnGroupB.BmwDrvgDynStMacEffortCmdScaDft -> BmwDrvgDynStMac.BmwDrvgDynStMacEffortCmdScaDft
    connect CalRegn01CmnGroupB.BmwDrvgDynStMacErrIfTmrThd -> BmwDrvgDynStMac.BmwDrvgDynStMacErrIfTmrThd
    connect CalRegn01CmnGroupB.BmwDrvgDynStMacMotTqCmdOvrlActvtThd -> BmwDrvgDynStMac.BmwDrvgDynStMacMotTqCmdOvrlActvtThd
    connect CalRegn01CmnGroupB.BmwDrvgDynStMacMotTqCmdOvrlDeactvtThd -> BmwDrvgDynStMac.BmwDrvgDynStMacMotTqCmdOvrlDeactvtThd
    connect CalRegn01CmnGroupB.BmwDrvgDynStMacRtnCmdScaDft -> BmwDrvgDynStMac.BmwDrvgDynStMacRtnCmdScaDft
    connect CalRegn01CmnGroupB.BmwDrvgDynStMacVehCdnTmrThd -> BmwDrvgDynStMac.BmwDrvgDynStMacVehCdnTmrThd
    connect CalRegn01CmnGroupB.BmwHaptcFbAmpAndIntenHwTqTblX -> BmwHaptcFb.BmwHaptcFbAmpAndIntenHwTqTblX
    connect CalRegn01CmnGroupB.BmwHaptcFbAmpBilnrSeln -> BmwHaptcFb.BmwHaptcFbAmpBilnrSeln
    connect CalRegn01CmnGroupB.BmwHaptcFbAmpSelnTblY -> BmwHaptcFb.BmwHaptcFbAmpSelnTblY
    connect CalRegn01CmnGroupB.BmwHaptcFbEpsDegradedFltThd -> BmwHaptcFb.BmwHaptcFbEpsDegradedFltThd
    connect CalRegn01CmnGroupB.BmwHaptcFbFrqBilnrSeln -> BmwHaptcFb.BmwHaptcFbFrqBilnrSeln
    connect CalRegn01CmnGroupB.BmwHaptcFbFrqSelnTblY -> BmwHaptcFb.BmwHaptcFbFrqSelnTblY
    connect CalRegn01CmnGroupB.BmwHaptcFbHwTqFrqTblY -> BmwHaptcFb.BmwHaptcFbHwTqFrqTblY
    connect CalRegn01CmnGroupB.BmwHaptcFbIntenSelnTblX -> BmwHaptcFb.BmwHaptcFbIntenSelnTblX
    connect CalRegn01CmnGroupB.BmwHaptcFbMotTqAmpTblY -> BmwHaptcFb.BmwHaptcFbMotTqAmpTblY
    connect CalRegn01CmnGroupB.BmwHaptcFbPatActvTiTblY -> BmwHaptcFb.BmwHaptcFbPatActvTiTblY
    connect CalRegn01CmnGroupB.BmwHaptcFbPatPasTiTblY -> BmwHaptcFb.BmwHaptcFbPatPasTiTblY
    connect CalRegn01CmnGroupB.BmwHaptcFbPatRisngSlewTblY -> BmwHaptcFb.BmwHaptcFbPatRisngSlewTblY
    connect CalRegn01CmnGroupB.BmwHwTqOvrlArbnCmdErrThd -> BmwHwTqOvrlArbn.BmwHwTqOvrlArbnCmdErrThd
    connect CalRegn01CmnGroupB.BmwHwTqOvrlArbnHwTqThdY -> BmwHwTqOvrlArbn.BmwHwTqOvrlArbnHwTqThdY
    connect CalRegn01CmnGroupB.BmwHwTqOvrlArbnOutpTqCmdLim -> BmwHwTqOvrlArbn.BmwHwTqOvrlArbnOutpTqCmdLim
    connect CalRegn01CmnGroupB.BmwHwTqOvrlArbnRampRate -> BmwHwTqOvrlArbn.BmwHwTqOvrlArbnRampRate
    connect CalRegn01CmnGroupB.BmwHwTqOvrlArbnRefTiThd -> BmwHwTqOvrlArbn.BmwHwTqOvrlArbnRefTiThd
    connect CalRegn01CmnGroupB.BmwHwTqOvrlArbnVehSpdX -> BmwHwTqOvrlArbn.BmwHwTqOvrlArbnVehSpdX
    connect CalRegn01CmnGroupB.BmwMotTqOvrlArbnBmwNearStillVehSpdStsRefTiThd -> BmwMotTqOvrlArbn.BmwMotTqOvrlArbnBmwNearStillVehSpdStsRefTiThd
    connect CalRegn01CmnGroupB.BmwMotTqOvrlArbnMfgModCmdRefTiThd -> BmwMotTqOvrlArbn.BmwMotTqOvrlArbnMfgModCmdRefTiThd
    connect CalRegn01CmnGroupB.BmwMotTqOvrlArbnMfgModCmdThd -> BmwMotTqOvrlArbn.BmwMotTqOvrlArbnMfgModCmdThd
    connect CalRegn01CmnGroupB.BmwMotTqOvrlArbnMfgModVehSpdThd -> BmwMotTqOvrlArbn.BmwMotTqOvrlArbnMfgModVehSpdThd
    connect CalRegn01CmnGroupB.BmwMotTqOvrlArbnVehSpdRefTiThd -> BmwMotTqOvrlArbn.BmwMotTqOvrlArbnVehSpdRefTiThd
    connect CalRegn01CmnGroupB.BmwSplyCurrLimBmwMaxCurrLimMax -> BmwSplyCurrLim.BmwSplyCurrLimBmwMaxCurrLimMax
    connect CalRegn01CmnGroupB.BmwSplyCurrLimBmwMaxCurrLimMin -> BmwSplyCurrLim.BmwSplyCurrLimBmwMaxCurrLimMin
    connect CalRegn01CmnGroupB.BmwSplyCurrLimBmwMaxCurrLimrGrdt -> BmwSplyCurrLim.BmwSplyCurrLimBmwMaxCurrLimrGrdt
    connect CalRegn01CmnGroupB.BmwSplyCurrLimDegradedVltgMaxCurrX -> BmwSplyCurrLim.BmwSplyCurrLimDegradedVltgMaxCurrX
    connect CalRegn01CmnGroupB.BmwSplyCurrLimDegradedVltgMaxCurrY -> BmwSplyCurrLim.BmwSplyCurrLimDegradedVltgMaxCurrY
    connect CalRegn01CmnGroupB.BmwSplyCurrLimEpsCpbyOffs -> BmwSplyCurrLim.BmwSplyCurrLimEpsCpbyOffs
    connect CalRegn01CmnGroupB.BmwSplyCurrLimEpsMaxGrdt -> BmwSplyCurrLim.BmwSplyCurrLimEpsMaxGrdt
    connect CalRegn01CmnGroupB.BmwSplyCurrLimEpsMinGrdt -> BmwSplyCurrLim.BmwSplyCurrLimEpsMinGrdt
    connect CalRegn01CmnGroupB.BmwSplyCurrLimMaxCurrLim -> BmwSplyCurrLim.BmwSplyCurrLimMaxCurrLim
    connect CalRegn01CmnGroupB.BmwSplyCurrLimNormVltgMaxCurrX -> BmwSplyCurrLim.BmwSplyCurrLimNormVltgMaxCurrX
    connect CalRegn01CmnGroupB.BmwSplyCurrLimNormVltgMaxCurrY -> BmwSplyCurrLim.BmwSplyCurrLimNormVltgMaxCurrY
    connect CalRegn01CmnGroupB.BmwSplyCurrLimRemCtrlPrkgLim -> BmwSplyCurrLim.BmwSplyCurrLimRemCtrlPrkgLim
    connect CalRegn01CmnGroupB.BmwSplyCurrLimVehSpdDptCurrLimX -> BmwSplyCurrLim.BmwSplyCurrLimVehSpdDptCurrLimX
    connect CalRegn01CmnGroupB.BmwSplyCurrLimVehSpdDptCurrLimY -> BmwSplyCurrLim.BmwSplyCurrLimVehSpdDptCurrLimY
    connect CalRegn01CmnGroupB.BmwSplyCurrLimVltgDptCurrGrdtDecX -> BmwSplyCurrLim.BmwSplyCurrLimVltgDptCurrGrdtDecX
    connect CalRegn01CmnGroupB.BmwSplyCurrLimVltgDptCurrGrdtDecY -> BmwSplyCurrLim.BmwSplyCurrLimVltgDptCurrGrdtDecY
    connect CalRegn01CmnGroupB.BmwSplyCurrLimVltgDptCurrGrdtIncX -> BmwSplyCurrLim.BmwSplyCurrLimVltgDptCurrGrdtIncX
    connect CalRegn01CmnGroupB.BmwSplyCurrLimVltgDptCurrGrdtIncY -> BmwSplyCurrLim.BmwSplyCurrLimVltgDptCurrGrdtIncY
    connect CalRegn01CmnGroupB.BmwSplyCurrLimVltgDptCurrLimFltThd -> BmwSplyCurrLim.BmwSplyCurrLimVltgDptCurrLimFltThd
    connect CalRegn01CmnGroupB.BmwSplyCurrLimVrntMaxCurr -> BmwSplyCurrLim.BmwSplyCurrLimVrntMaxCurr
    connect CalRegn01CmnGroupB.BmwTqOvrlCdngAndDrvgDynFacActvDampgSlewRate -> BmwTqOvrlCdngAndDrvgDynFac.BmwTqOvrlCdngAndDrvgDynFacActvDampgSlewRate
    connect CalRegn01CmnGroupB.BmwTqOvrlCdngAndDrvgDynFacActvEffortSlewRate -> BmwTqOvrlCdngAndDrvgDynFac.BmwTqOvrlCdngAndDrvgDynFacActvEffortSlewRate
    connect CalRegn01CmnGroupB.BmwTqOvrlCdngAndDrvgDynFacActvRtnSlewRate -> BmwTqOvrlCdngAndDrvgDynFac.BmwTqOvrlCdngAndDrvgDynFacActvRtnSlewRate
    connect CalRegn01CmnGroupB.BmwTqOvrlCdngAndDrvgDynFacDampgScaLoLimX -> BmwTqOvrlCdngAndDrvgDynFac.BmwTqOvrlCdngAndDrvgDynFacDampgScaLoLimX
    connect CalRegn01CmnGroupB.BmwTqOvrlCdngAndDrvgDynFacDampgScaLoLimY -> BmwTqOvrlCdngAndDrvgDynFac.BmwTqOvrlCdngAndDrvgDynFacDampgScaLoLimY
    connect CalRegn01CmnGroupB.BmwTqOvrlCdngAndDrvgDynFacEffortScaHiLimX -> BmwTqOvrlCdngAndDrvgDynFac.BmwTqOvrlCdngAndDrvgDynFacEffortScaHiLimX
    connect CalRegn01CmnGroupB.BmwTqOvrlCdngAndDrvgDynFacEffortScaHiLimY -> BmwTqOvrlCdngAndDrvgDynFac.BmwTqOvrlCdngAndDrvgDynFacEffortScaHiLimY
    connect CalRegn01CmnGroupB.BmwTqOvrlCdngAndDrvgDynFacInactvDampgSlewRate -> BmwTqOvrlCdngAndDrvgDynFac.BmwTqOvrlCdngAndDrvgDynFacInactvDampgSlewRate
    connect CalRegn01CmnGroupB.BmwTqOvrlCdngAndDrvgDynFacInactvEffortSlewRate -> BmwTqOvrlCdngAndDrvgDynFac.BmwTqOvrlCdngAndDrvgDynFacInactvEffortSlewRate
    connect CalRegn01CmnGroupB.BmwTqOvrlCdngAndDrvgDynFacInactvRtnSlewRate -> BmwTqOvrlCdngAndDrvgDynFac.BmwTqOvrlCdngAndDrvgDynFacInactvRtnSlewRate
    connect CalRegn01CmnGroupB.BmwTqOvrlCdngAndDrvgDynFacOutpTqOvrlSlew -> BmwTqOvrlCdngAndDrvgDynFac.BmwTqOvrlCdngAndDrvgDynFacOutpTqOvrlSlew
    connect CalRegn01CmnGroupB.BmwTqOvrlCdngAndDrvgDynFacReqdRtnCmdScaLoLim -> BmwTqOvrlCdngAndDrvgDynFac.BmwTqOvrlCdngAndDrvgDynFacReqdRtnCmdScaLoLim
    connect CalRegn01CmnGroupB.BmwTqOvrlCdngAndDrvgDynFacTarSteerTqDrvrActrLpFilFrq -> BmwTqOvrlCdngAndDrvgDynFac.BmwTqOvrlCdngAndDrvgDynFacTarSteerTqDrvrActrLpFilFrq
    connect CalRegn01CmnGroupB.BmwTqOvrlCdngAndDrvgDynFacTarSteerTqDrvrActrMaxY -> BmwTqOvrlCdngAndDrvgDynFac.BmwTqOvrlCdngAndDrvgDynFacTarSteerTqDrvrActrMaxY
    connect CalRegn01CmnGroupB.BmwTqOvrlCdngAndDrvgDynFacTarSteerTqDrvrActrSpdX -> BmwTqOvrlCdngAndDrvgDynFac.BmwTqOvrlCdngAndDrvgDynFacTarSteerTqDrvrActrSpdX
    connect CalRegn01CmnGroupB.BmwTrfcJamAssiDampgBasDampgX -> BmwTrfcJamAssiDampg.BmwTrfcJamAssiDampgBasDampgX
    connect CalRegn01CmnGroupB.BmwTrfcJamAssiDampgBasDampgY -> BmwTrfcJamAssiDampg.BmwTrfcJamAssiDampgBasDampgY
    connect CalRegn01CmnGroupB.BmwTrfcJamAssiDampgLimdDampgX -> BmwTrfcJamAssiDampg.BmwTrfcJamAssiDampgLimdDampgX
    connect CalRegn01CmnGroupB.BmwTrfcJamAssiDampgLimdDampgY -> BmwTrfcJamAssiDampg.BmwTrfcJamAssiDampgLimdDampgY
    connect CalRegn01CmnGroupB.BmwTrfcJamAssiDampgLimExcddFltRefTiThd -> BmwTrfcJamAssiDampg.BmwTrfcJamAssiDampgLimExcddFltRefTiThd
    connect CalRegn01CmnGroupB.BmwTrfcJamAssiDampgRatThd -> BmwTrfcJamAssiDampg.BmwTrfcJamAssiDampgRatThd
    connect CalRegn01CmnGroupB.BmwTrfcJamAssiDampgSlewRateDwnActv -> BmwTrfcJamAssiDampg.BmwTrfcJamAssiDampgSlewRateDwnActv
    connect CalRegn01CmnGroupB.BmwTrfcJamAssiDampgSlewRateDwnInactv -> BmwTrfcJamAssiDampg.BmwTrfcJamAssiDampgSlewRateDwnInactv
    connect CalRegn01CmnGroupB.BmwTrfcJamAssiDampgSlewRateDwnInvld -> BmwTrfcJamAssiDampg.BmwTrfcJamAssiDampgSlewRateDwnInvld
    connect CalRegn01CmnGroupB.BmwTrfcJamAssiDampgSlewRateUp -> BmwTrfcJamAssiDampg.BmwTrfcJamAssiDampgSlewRateUp
    connect CalRegn01CmnGroupC.CtrldVelRtnAntiWdup -> CtrldVelRtn.CtrldVelRtnAntiWdup
    connect CalRegn01CmnGroupC.CtrldVelRtnDampgEna -> CtrldVelRtn.CtrldVelRtnDampgEna
    connect CalRegn01CmnGroupC.CtrldVelRtnDampgScaEna -> CtrldVelRtn.CtrldVelRtnDampgScaEna
    connect CalRegn01CmnGroupC.CtrldVelRtnDrvrTqEna -> CtrldVelRtn.CtrldVelRtnDrvrTqEna
    connect CalRegn01CmnGroupC.CtrldVelRtnDrvrTqMtrxA -> CtrldVelRtn.CtrldVelRtnDrvrTqMtrxA
    connect CalRegn01CmnGroupC.CtrldVelRtnDrvrTqMtrxB -> CtrldVelRtn.CtrldVelRtnDrvrTqMtrxB
    connect CalRegn01CmnGroupC.CtrldVelRtnDrvrTqMtrxC -> CtrldVelRtn.CtrldVelRtnDrvrTqMtrxC
    connect CalRegn01CmnGroupC.CtrldVelRtnDrvrTqMtrxD -> CtrldVelRtn.CtrldVelRtnDrvrTqMtrxD
    connect CalRegn01CmnGroupC.CtrldVelRtnHwAuthyScaX -> CtrldVelRtn.CtrldVelRtnHwAuthyScaX
    connect CalRegn01CmnGroupC.CtrldVelRtnHwAuthyScaY -> CtrldVelRtn.CtrldVelRtnHwAuthyScaY
    connect CalRegn01CmnGroupC.CtrldVelRtnHwAuthySlewThd -> CtrldVelRtn.CtrldVelRtnHwAuthySlewThd
    connect CalRegn01CmnGroupC.CtrldVelRtnRtnCmdLimY -> CtrldVelRtn.CtrldVelRtnRtnCmdLimY
    connect CalRegn01CmnGroupC.CtrldVelRtnTqGrdtScaEna -> CtrldVelRtn.CtrldVelRtnTqGrdtScaEna
    connect CalRegn01CmnGroupC.SteerCmdArbnAndLimFalbckTiThd -> SteerCmdArbnAndLim.SteerCmdArbnAndLimFalbckTiThd
    connect CalRegn01CmnGroupC.SteerCmdArbnAndLimFwTiThd -> SteerCmdArbnAndLim.SteerCmdArbnAndLimFwTiThd
    connect CalRegn01CmnGroupD.EotProtnActvRegnBypMaxThd -> EotProtn.EotProtnActvRegnBypMaxThd
    connect CalRegn01CmnGroupD.EotProtnDampgSlew -> EotProtn.EotProtnDampgSlew
    connect CalRegn01CmnGroupD.EotProtnDftPosn -> EotProtn.EotProtnDftPosn
    connect CalRegn01CmnGroupD.EotProtnHwAgGain -> EotProtn.EotProtnHwAgGain
    connect CalRegn01CmnGroupD.EotProtnHwAgMax -> EotProtn.EotProtnHwAgMax
    connect CalRegn01CmnGroupD.EotProtnHwAgMin -> EotProtn.EotProtnHwAgMin
    connect CalRegn01CmnGroupD.EotProtnRackTrvlLimrEna -> EotProtn.EotProtnRackTrvlLimrEna
    connect CalRegn01CmnGroupD.EotProtnSoftEndStopAuthyThd -> EotProtn.EotProtnSoftEndStopAuthyThd
    connect CalRegn01CmnGroupD.EotProtnSoftEndStopEna -> EotProtn.EotProtnSoftEndStopEna
    connect CalRegn01CmnGroupD.EotProtnSoftEndStopVehSpdThd -> EotProtn.EotProtnSoftEndStopVehSpdThd
    connect CalRegn01Inin00.BmwHwAgArbnAndEotPosnKineIntegrityDiagcMaxRackLim -> AAACalRegn01Inin00_Dummy.BmwHwAgArbnAndEotPosnKineIntegrityDiagcMaxRackLim
    connect CalRegn01Inin00.EffortScaBlndX -> AAACalRegn01Inin00_Dummy.EffortScaBlndX
    connect CalRegn01Inin00.EffortScaBlndY -> AAACalRegn01Inin00_Dummy.EffortScaBlndY
    connect CalRegn01Inin00.EffortScaRackFThd -> AAACalRegn01Inin00_Dummy.EffortScaRackFThd
    connect CalRegn01Inin00.PosnTrakgServoArbnFltMtgtnLpFilCutOffFrq -> AAACalRegn01Inin00_Dummy.PosnTrakgServoArbnFltMtgtnLpFilCutOffFrq
    connect CalRegn01Inin00.PullCmpActvHwTqFilFrqLrngEna -> AAACalRegn01Inin00_Dummy.PullCmpActvHwTqFilFrqLrngEna
    connect CalRegn01Inin00.PullCmpActvYawRateFilFrq -> AAACalRegn01Inin00_Dummy.PullCmpActvYawRateFilFrq
    connect CalRegn01Inin00.SysFricLrngAvrgFricFrq -> AAACalRegn01Inin00_Dummy.SysFricLrngAvrgFricFrq
    connect CalRegn01Inin00.SysFricLrngBasLineEolFric -> AAACalRegn01Inin00_Dummy.SysFricLrngBasLineEolFric
    connect CalRegn01Inin00.SysFricLrngBasLineFric -> AAACalRegn01Inin00_Dummy.SysFricLrngBasLineFric
    connect CalRegn01Inin00.SysFricLrngBasLineHys -> AAACalRegn01Inin00_Dummy.SysFricLrngBasLineHys
    connect CalRegn01Inin00.SysFricLrngBasLineRngCntr -> AAACalRegn01Inin00_Dummy.SysFricLrngBasLineRngCntr
    connect CalRegn01Inin00.SysFricLrngDataPrepLpFilFrq -> AAACalRegn01Inin00_Dummy.SysFricLrngDataPrepLpFilFrq
    connect CalRegn01Inin00.SysFricLrngDebStep -> AAACalRegn01Inin00_Dummy.SysFricLrngDebStep
    connect CalRegn01Inin00.SysFricLrngEolFricDifHiLim -> AAACalRegn01Inin00_Dummy.SysFricLrngEolFricDifHiLim
    connect CalRegn01Inin00.SysFricLrngEolFricDifLoLim -> AAACalRegn01Inin00_Dummy.SysFricLrngEolFricDifLoLim
    connect CalRegn01Inin00.SysFricLrngEolFricDifScagFac -> AAACalRegn01Inin00_Dummy.SysFricLrngEolFricDifScagFac
    connect CalRegn01Inin00.SysFricLrngFricChgWght -> AAACalRegn01Inin00_Dummy.SysFricLrngFricChgWght
    connect CalRegn01Inin00.SysFricLrngFricDiagcThd -> AAACalRegn01Inin00_Dummy.SysFricLrngFricDiagcThd
    connect CalRegn01Inin00.SysFricLrngFricHysHwAgPt -> AAACalRegn01Inin00_Dummy.SysFricLrngFricHysHwAgPt
    connect CalRegn01Inin00.SysFricLrngFricOffs -> AAACalRegn01Inin00_Dummy.SysFricLrngFricOffs
    connect CalRegn01Inin00.SysFricLrngFricOffsHiLim -> AAACalRegn01Inin00_Dummy.SysFricLrngFricOffsHiLim
    connect CalRegn01Inin00.SysFricLrngFricOffsLoLim -> AAACalRegn01Inin00_Dummy.SysFricLrngFricOffsLoLim
    connect CalRegn01Inin00.SysFricLrngFricOffsLpFilFrq -> AAACalRegn01Inin00_Dummy.SysFricLrngFricOffsLpFilFrq
    connect CalRegn01Inin00.SysFricLrngGain -> AAACalRegn01Inin00_Dummy.SysFricLrngGain
    connect CalRegn01Inin00.SysFricLrngHiFricDebStep -> AAACalRegn01Inin00_Dummy.SysFricLrngHiFricDebStep
    connect CalRegn01Inin00.SysFricLrngHiFricDiagcThd -> AAACalRegn01Inin00_Dummy.SysFricLrngHiFricDiagcThd
    connect CalRegn01Inin00.SysFricLrngHwPosnAuthyThd -> AAACalRegn01Inin00_Dummy.SysFricLrngHwPosnAuthyThd
    connect CalRegn01Inin00.SysFricLrngHwVelConstrLim -> AAACalRegn01Inin00_Dummy.SysFricLrngHwVelConstrLim
    connect CalRegn01Inin00.SysFricLrngHwVelHiLim -> AAACalRegn01Inin00_Dummy.SysFricLrngHwVelHiLim
    connect CalRegn01Inin00.SysFricLrngHwVelLoLim -> AAACalRegn01Inin00_Dummy.SysFricLrngHwVelLoLim
    connect CalRegn01Inin00.SysFricLrngIgnCycFricChgLim -> AAACalRegn01Inin00_Dummy.SysFricLrngIgnCycFricChgLim
    connect CalRegn01Inin00.SysFricLrngIgnCycFricOffs -> AAACalRegn01Inin00_Dummy.SysFricLrngIgnCycFricOffs
    connect CalRegn01Inin00.SysFricLrngIvsTrsmRatX -> AAACalRegn01Inin00_Dummy.SysFricLrngIvsTrsmRatX
    connect CalRegn01Inin00.SysFricLrngIvsTrsmRatY -> AAACalRegn01Inin00_Dummy.SysFricLrngIvsTrsmRatY
    connect CalRegn01Inin00.SysFricLrngLatAHiLim -> AAACalRegn01Inin00_Dummy.SysFricLrngLatAHiLim
    connect CalRegn01Inin00.SysFricLrngLatALoLim -> AAACalRegn01Inin00_Dummy.SysFricLrngLatALoLim
    connect CalRegn01Inin00.SysFricLrngMaskVehSpd -> AAACalRegn01Inin00_Dummy.SysFricLrngMaskVehSpd
    connect CalRegn01Inin00.SysFricLrngRngCntrThd -> AAACalRegn01Inin00_Dummy.SysFricLrngRngCntrThd
    connect CalRegn01Inin00.SysFricLrngThd -> AAACalRegn01Inin00_Dummy.SysFricLrngThd
    connect CalRegn01Inin00.SysFricLrngTHiLim -> AAACalRegn01Inin00_Dummy.SysFricLrngTHiLim
    connect CalRegn01Inin00.SysFricLrngTLoLim -> AAACalRegn01Inin00_Dummy.SysFricLrngTLoLim
    connect CalRegn01Inin00.SysFricLrngVehSpd -> AAACalRegn01Inin00_Dummy.SysFricLrngVehSpd
    connect CalRegn01Inin00.SysGlbPrmSysKineRat -> AAACalRegn01Inin00_Dummy.SysGlbPrmSysKineRat
    connect CalRegn01Inin00.SysGlbPrmVehSpdBilnrSeln -> AAACalRegn01Inin00_Dummy.SysGlbPrmVehSpdBilnrSeln
    connect CalRegn01Inin00.SysKineAndEffMotAgToRackPosRatScaY -> AAACalRegn01Inin00_Dummy.SysKineAndEffMotAgToRackPosRatScaY
    connect CalRegn01Inin00.SysKineAndEffPinionAgToRackPosRatScaY -> AAACalRegn01Inin00_Dummy.SysKineAndEffPinionAgToRackPosRatScaY
    connect CalRegn01Inin00.SysKineAndEffPinionToRackEffScaY -> AAACalRegn01Inin00_Dummy.SysKineAndEffPinionToRackEffScaY
    connect CalRegn01Inin00.SysKineAndEffRoadWhlFromRackPosScaY -> AAACalRegn01Inin00_Dummy.SysKineAndEffRoadWhlFromRackPosScaY
    connect CalRegn01Inin00.SysKineAndEffSteerArmLenFromRackPosScaY -> AAACalRegn01Inin00_Dummy.SysKineAndEffSteerArmLenFromRackPosScaY
    connect CalRegn01Inin00.TunSelnAuthyVehSpdX -> AAACalRegn01Inin00_Dummy.TunSelnAuthyVehSpdX
    connect CalRegn01Inin00.SysGlbPrmVehSpdBilnrSeln -> BmwHaptcFb.SysGlbPrmVehSpdBilnrSeln
    connect CalRegn01Inin00.BmwHwAgArbnAndEotPosnKineIntegrityDiagcMaxRackLim -> BmwHwAgArbnAndEotPosn.BmwHwAgArbnAndEotPosnKineIntegrityDiagcMaxRackLim
    connect CalRegn01Inin00.SysGlbPrmSysKineRat -> BmwHwAgArbnAndEotPosn.SysGlbPrmSysKineRat
    connect CalRegn01Inin00.SysGlbPrmVehSpdBilnrSeln -> BmwTqOvrlCdngAndDrvgDynFac.SysGlbPrmVehSpdBilnrSeln
    connect CalRegn01Inin00.SysGlbPrmVehSpdBilnrSeln -> BmwTrfcJamAssiDampg.SysGlbPrmVehSpdBilnrSeln
    connect CalRegn01Inin00.SysGlbPrmSysKineRat -> CDD_MotAgCmp.SysGlbPrmSysKineRat
    connect CalRegn01Inin00.SysGlbPrmVehSpdBilnrSeln -> ClsdLoopDampg.SysGlbPrmVehSpdBilnrSeln
    connect CalRegn01Inin00.SysGlbPrmVehSpdBilnrSeln -> ClsdLoopHys.SysGlbPrmVehSpdBilnrSeln
    connect CalRegn01Inin00.EffortScaBlndX -> Effort.EffortScaBlndX
    connect CalRegn01Inin00.EffortScaBlndY -> Effort.EffortScaBlndY
    connect CalRegn01Inin00.EffortScaRackFThd -> Effort.EffortScaRackFThd
    connect CalRegn01Inin00.SysGlbPrmVehSpdBilnrSeln -> FalbckAssi.SysGlbPrmVehSpdBilnrSeln
    connect CalRegn01Inin00.SysGlbPrmSysKineRat -> InertiaCmpVel.SysGlbPrmSysKineRat
    connect CalRegn01Inin00.SysGlbPrmVehSpdBilnrSeln -> InertiaCmpVel.SysGlbPrmVehSpdBilnrSeln
    connect CalRegn01Inin00.SysGlbPrmSysKineRat -> LrndRackCentr.SysGlbPrmSysKineRat
    connect CalRegn01Inin00.SysGlbPrmSysKineRat -> LrnPinionCentr.SysGlbPrmSysKineRat
    connect CalRegn01Inin00.PosnTrakgServoArbnFltMtgtnLpFilCutOffFrq -> PosnTrakgServo.PosnTrakgServoArbnFltMtgtnLpFilCutOffFrq
    connect CalRegn01Inin00.SysGlbPrmSysKineRat -> PosnTrakgServo.SysGlbPrmSysKineRat
    connect CalRegn01Inin00.PullCmpActvHwTqFilFrqLrngEna -> PullCmpActv.PullCmpActvHwTqFilFrqLrngEna
    connect CalRegn01Inin00.PullCmpActvYawRateFilFrq -> PullCmpActv.PullCmpActvYawRateFilFrq
    connect CalRegn01Inin00.SysFricLrngAvrgFricFrq -> SysFricLrng.SysFricLrngAvrgFricFrq
    connect CalRegn01Inin00.SysFricLrngBasLineEolFric -> SysFricLrng.SysFricLrngBasLineEolFric
    connect CalRegn01Inin00.SysFricLrngBasLineFric -> SysFricLrng.SysFricLrngBasLineFric
    connect CalRegn01Inin00.SysFricLrngBasLineHys -> SysFricLrng.SysFricLrngBasLineHys
    connect CalRegn01Inin00.SysFricLrngBasLineRngCntr -> SysFricLrng.SysFricLrngBasLineRngCntr
    connect CalRegn01Inin00.SysFricLrngDataPrepLpFilFrq -> SysFricLrng.SysFricLrngDataPrepLpFilFrq
    connect CalRegn01Inin00.SysFricLrngDebStep -> SysFricLrng.SysFricLrngDebStep
    connect CalRegn01Inin00.SysFricLrngEolFricDifHiLim -> SysFricLrng.SysFricLrngEolFricDifHiLim
    connect CalRegn01Inin00.SysFricLrngEolFricDifLoLim -> SysFricLrng.SysFricLrngEolFricDifLoLim
    connect CalRegn01Inin00.SysFricLrngEolFricDifScagFac -> SysFricLrng.SysFricLrngEolFricDifScagFac
    connect CalRegn01Inin00.SysFricLrngFricChgWght -> SysFricLrng.SysFricLrngFricChgWght
    connect CalRegn01Inin00.SysFricLrngFricDiagcThd -> SysFricLrng.SysFricLrngFricDiagcThd
    connect CalRegn01Inin00.SysFricLrngFricHysHwAgPt -> SysFricLrng.SysFricLrngFricHysHwAgPt
    connect CalRegn01Inin00.SysFricLrngFricOffs -> SysFricLrng.SysFricLrngFricOffs
    connect CalRegn01Inin00.SysFricLrngFricOffsHiLim -> SysFricLrng.SysFricLrngFricOffsHiLim
    connect CalRegn01Inin00.SysFricLrngFricOffsLoLim -> SysFricLrng.SysFricLrngFricOffsLoLim
    connect CalRegn01Inin00.SysFricLrngFricOffsLpFilFrq -> SysFricLrng.SysFricLrngFricOffsLpFilFrq
    connect CalRegn01Inin00.SysFricLrngGain -> SysFricLrng.SysFricLrngGain
    connect CalRegn01Inin00.SysFricLrngHiFricDebStep -> SysFricLrng.SysFricLrngHiFricDebStep
    connect CalRegn01Inin00.SysFricLrngHiFricDiagcThd -> SysFricLrng.SysFricLrngHiFricDiagcThd
    connect CalRegn01Inin00.SysFricLrngHwPosnAuthyThd -> SysFricLrng.SysFricLrngHwPosnAuthyThd
    connect CalRegn01Inin00.SysFricLrngHwVelConstrLim -> SysFricLrng.SysFricLrngHwVelConstrLim
    connect CalRegn01Inin00.SysFricLrngHwVelHiLim -> SysFricLrng.SysFricLrngHwVelHiLim
    connect CalRegn01Inin00.SysFricLrngHwVelLoLim -> SysFricLrng.SysFricLrngHwVelLoLim
    connect CalRegn01Inin00.SysFricLrngIgnCycFricChgLim -> SysFricLrng.SysFricLrngIgnCycFricChgLim
    connect CalRegn01Inin00.SysFricLrngIgnCycFricOffs -> SysFricLrng.SysFricLrngIgnCycFricOffs
    connect CalRegn01Inin00.SysFricLrngIvsTrsmRatX -> SysFricLrng.SysFricLrngIvsTrsmRatX
    connect CalRegn01Inin00.SysFricLrngIvsTrsmRatY -> SysFricLrng.SysFricLrngIvsTrsmRatY
    connect CalRegn01Inin00.SysFricLrngLatAHiLim -> SysFricLrng.SysFricLrngLatAHiLim
    connect CalRegn01Inin00.SysFricLrngLatALoLim -> SysFricLrng.SysFricLrngLatALoLim
    connect CalRegn01Inin00.SysFricLrngMaskVehSpd -> SysFricLrng.SysFricLrngMaskVehSpd
    connect CalRegn01Inin00.SysFricLrngRngCntrThd -> SysFricLrng.SysFricLrngRngCntrThd
    connect CalRegn01Inin00.SysFricLrngThd -> SysFricLrng.SysFricLrngThd
    connect CalRegn01Inin00.SysFricLrngTHiLim -> SysFricLrng.SysFricLrngTHiLim
    connect CalRegn01Inin00.SysFricLrngTLoLim -> SysFricLrng.SysFricLrngTLoLim
    connect CalRegn01Inin00.SysFricLrngVehSpd -> SysFricLrng.SysFricLrngVehSpd
    connect CalRegn01Inin00.SysKineAndEffMotAgToRackPosRatScaY -> SysKineAndEff.SysKineAndEffMotAgToRackPosRatScaY
    connect CalRegn01Inin00.SysKineAndEffPinionAgToRackPosRatScaY -> SysKineAndEff.SysKineAndEffPinionAgToRackPosRatScaY
    connect CalRegn01Inin00.SysKineAndEffPinionToRackEffScaY -> SysKineAndEff.SysKineAndEffPinionToRackEffScaY
    connect CalRegn01Inin00.SysKineAndEffRoadWhlFromRackPosScaY -> SysKineAndEff.SysKineAndEffRoadWhlFromRackPosScaY
    connect CalRegn01Inin00.SysKineAndEffSteerArmLenFromRackPosScaY -> SysKineAndEff.SysKineAndEffSteerArmLenFromRackPosScaY
    connect CalRegn01Inin00.TunSelnAuthyVehSpdX -> TunSelnAuthy.TunSelnAuthyVehSpdX
    connect CalRegn01Inin00GroupA.BmwHwAgArbnAndEotPosnEotCcwMax -> AAACalRegn01Inin00GroupA_Dummy.BmwHwAgArbnAndEotPosnEotCcwMax
    connect CalRegn01Inin00GroupA.BmwHwAgArbnAndEotPosnEotCcwMin -> AAACalRegn01Inin00GroupA_Dummy.BmwHwAgArbnAndEotPosnEotCcwMin
    connect CalRegn01Inin00GroupA.BmwHwAgArbnAndEotPosnEotCwMax -> AAACalRegn01Inin00GroupA_Dummy.BmwHwAgArbnAndEotPosnEotCwMax
    connect CalRegn01Inin00GroupA.BmwHwAgArbnAndEotPosnEotCwMin -> AAACalRegn01Inin00GroupA_Dummy.BmwHwAgArbnAndEotPosnEotCwMin
    connect CalRegn01Inin00GroupA.BmwPwrPrkgDampgDiScadDampg -> AAACalRegn01Inin00GroupA_Dummy.BmwPwrPrkgDampgDiScadDampg
    connect CalRegn01Inin00GroupA.BmwPwrPrkgDampgMaxRate -> AAACalRegn01Inin00GroupA_Dummy.BmwPwrPrkgDampgMaxRate
    connect CalRegn01Inin00GroupA.EpsStEstimnMtrxA -> AAACalRegn01Inin00GroupA_Dummy.EpsStEstimnMtrxA
    connect CalRegn01Inin00GroupA.EpsStEstimnMtrxB -> AAACalRegn01Inin00GroupA_Dummy.EpsStEstimnMtrxB
    connect CalRegn01Inin00GroupA.EpsStEstimnMtrxC -> AAACalRegn01Inin00GroupA_Dummy.EpsStEstimnMtrxC
    connect CalRegn01Inin00GroupA.EpsStEstimnMtrxD -> AAACalRegn01Inin00GroupA_Dummy.EpsStEstimnMtrxD
    connect CalRegn01Inin00GroupA.HwTqTrakgCtrlFbGain{1..5} -> AAACalRegn01Inin00GroupA_Dummy.HwTqTrakgCtrlFbGain{1..5}
    connect CalRegn01Inin00GroupA.HwTqTrakgCtrlFfGainScaY -> AAACalRegn01Inin00GroupA_Dummy.HwTqTrakgCtrlFfGainScaY
    connect CalRegn01Inin00GroupA.HwTqTrakgCtrlVehSpdScaX -> AAACalRegn01Inin00GroupA_Dummy.HwTqTrakgCtrlVehSpdScaX
    connect CalRegn01Inin00GroupA.PosnTrakgServoEnaBlndFacTblX -> AAACalRegn01Inin00GroupA_Dummy.PosnTrakgServoEnaBlndFacTblX
    connect CalRegn01Inin00GroupA.PosnTrakgServoEnaBlndFacTblY -> AAACalRegn01Inin00GroupA_Dummy.PosnTrakgServoEnaBlndFacTblY
    connect CalRegn01Inin00GroupA.PosnTrakgServoGainArbnFltMtgtn -> AAACalRegn01Inin00GroupA_Dummy.PosnTrakgServoGainArbnFltMtgtn
    connect CalRegn01Inin00GroupA.PullCmpActvCmpLrnTiDecShoTerm -> AAACalRegn01Inin00GroupA_Dummy.PullCmpActvCmpLrnTiDecShoTerm
    connect CalRegn01Inin00GroupA.PullCmpActvCmpLrnTiIncShoTerm -> AAACalRegn01Inin00GroupA_Dummy.PullCmpActvCmpLrnTiIncShoTerm
    connect CalRegn01Inin00GroupA.PullCmpActvCmpLrnTiLongTerm -> AAACalRegn01Inin00GroupA_Dummy.PullCmpActvCmpLrnTiLongTerm
    connect CalRegn01Inin00GroupA.PullCmpActvCmpShoTermRstHwAgThd -> AAACalRegn01Inin00GroupA_Dummy.PullCmpActvCmpShoTermRstHwAgThd
    connect CalRegn01Inin00GroupA.PullCmpActvCmpShoTermRstHwTqThd -> AAACalRegn01Inin00GroupA_Dummy.PullCmpActvCmpShoTermRstHwTqThd
    connect CalRegn01Inin00GroupA.PullCmpActvCmpShoTermRstLatAThd -> AAACalRegn01Inin00GroupA_Dummy.PullCmpActvCmpShoTermRstLatAThd
    connect CalRegn01Inin00GroupA.PullCmpActvCmpShoTermRstYawRateThd -> AAACalRegn01Inin00GroupA_Dummy.PullCmpActvCmpShoTermRstYawRateThd
    connect CalRegn01Inin00GroupA.PullCmpActvEna -> AAACalRegn01Inin00GroupA_Dummy.PullCmpActvEna
    connect CalRegn01Inin00GroupA.PullCmpActvHwTqFilFrqLongTerm -> AAACalRegn01Inin00GroupA_Dummy.PullCmpActvHwTqFilFrqLongTerm
    connect CalRegn01Inin00GroupA.PullCmpActvHwTqFilFrqShoTerm -> AAACalRegn01Inin00GroupA_Dummy.PullCmpActvHwTqFilFrqShoTerm
    connect CalRegn01Inin00GroupA.PullCmpActvLongTermLim -> AAACalRegn01Inin00GroupA_Dummy.PullCmpActvLongTermLim
    connect CalRegn01Inin00GroupA.PullCmpActvLrngEnaAgConfMinMgn -> AAACalRegn01Inin00GroupA_Dummy.PullCmpActvLrngEnaAgConfMinMgn
    connect CalRegn01Inin00GroupA.PullCmpActvLrngEnaHwAgMaxMgn -> AAACalRegn01Inin00GroupA_Dummy.PullCmpActvLrngEnaHwAgMaxMgn
    connect CalRegn01Inin00GroupA.PullCmpActvLrngEnaHwTqMaxMgn -> AAACalRegn01Inin00GroupA_Dummy.PullCmpActvLrngEnaHwTqMaxMgn
    connect CalRegn01Inin00GroupA.PullCmpActvLrngEnaHwVelMaxMgn -> AAACalRegn01Inin00GroupA_Dummy.PullCmpActvLrngEnaHwVelMaxMgn
    connect CalRegn01Inin00GroupA.PullCmpActvLrngEnaLatAMaxMgn -> AAACalRegn01Inin00GroupA_Dummy.PullCmpActvLrngEnaLatAMaxMgn
    connect CalRegn01Inin00GroupA.PullCmpActvLrngEnaTiThd -> AAACalRegn01Inin00GroupA_Dummy.PullCmpActvLrngEnaTiThd
    connect CalRegn01Inin00GroupA.PullCmpActvLrngEnaVehSpdMaxMgn -> AAACalRegn01Inin00GroupA_Dummy.PullCmpActvLrngEnaVehSpdMaxMgn
    connect CalRegn01Inin00GroupA.PullCmpActvLrngEnaVehSpdMinMgn -> AAACalRegn01Inin00GroupA_Dummy.PullCmpActvLrngEnaVehSpdMinMgn
    connect CalRegn01Inin00GroupA.PullCmpActvLrngEnaVehSpdRateMaxMgn -> AAACalRegn01Inin00GroupA_Dummy.PullCmpActvLrngEnaVehSpdRateMaxMgn
    connect CalRegn01Inin00GroupA.PullCmpActvLrngEnaYawRateMaxMgn -> AAACalRegn01Inin00GroupA_Dummy.PullCmpActvLrngEnaYawRateMaxMgn
    connect CalRegn01Inin00GroupA.PullCmpActvOpstSignTiShoTerm -> AAACalRegn01Inin00GroupA_Dummy.PullCmpActvOpstSignTiShoTerm
    connect CalRegn01Inin00GroupA.PullCmpActvOutpMaxRate -> AAACalRegn01Inin00GroupA_Dummy.PullCmpActvOutpMaxRate
    connect CalRegn01Inin00GroupA.PullCmpActvPullCmpShoTermLim -> AAACalRegn01Inin00GroupA_Dummy.PullCmpActvPullCmpShoTermLim
    connect CalRegn01Inin00GroupA.PullCmpActvPullCmpTotLim -> AAACalRegn01Inin00GroupA_Dummy.PullCmpActvPullCmpTotLim
    connect CalRegn01Inin00GroupA.PullCmpActvPullErrLimLongTerm -> AAACalRegn01Inin00GroupA_Dummy.PullCmpActvPullErrLimLongTerm
    connect CalRegn01Inin00GroupA.PullCmpActvPullErrMgnThd -> AAACalRegn01Inin00GroupA_Dummy.PullCmpActvPullErrMgnThd
    connect CalRegn01Inin00GroupA.PullCmpActvPullErrShoTermLim -> AAACalRegn01Inin00GroupA_Dummy.PullCmpActvPullErrShoTermLim
    connect CalRegn01Inin00GroupA.PullCmpActvShoTermRampTi -> AAACalRegn01Inin00GroupA_Dummy.PullCmpActvShoTermRampTi
    connect CalRegn01Inin00GroupA.PullCmpActvVehSpdScaTblX -> AAACalRegn01Inin00GroupA_Dummy.PullCmpActvVehSpdScaTblX
    connect CalRegn01Inin00GroupA.PullCmpActvVehSpdScaTblY -> AAACalRegn01Inin00GroupA_Dummy.PullCmpActvVehSpdScaTblY
    connect CalRegn01Inin00GroupA.BmwHwAgArbnAndEotPosnEotCcwMax -> BmwHwAgArbnAndEotPosn.BmwHwAgArbnAndEotPosnEotCcwMax
    connect CalRegn01Inin00GroupA.BmwHwAgArbnAndEotPosnEotCcwMin -> BmwHwAgArbnAndEotPosn.BmwHwAgArbnAndEotPosnEotCcwMin
    connect CalRegn01Inin00GroupA.BmwHwAgArbnAndEotPosnEotCwMax -> BmwHwAgArbnAndEotPosn.BmwHwAgArbnAndEotPosnEotCwMax
    connect CalRegn01Inin00GroupA.BmwHwAgArbnAndEotPosnEotCwMin -> BmwHwAgArbnAndEotPosn.BmwHwAgArbnAndEotPosnEotCwMin
    connect CalRegn01Inin00GroupA.BmwPwrPrkgDampgDiScadDampg -> BmwPwrPrkgDampg.BmwPwrPrkgDampgDiScadDampg
    connect CalRegn01Inin00GroupA.BmwPwrPrkgDampgMaxRate -> BmwPwrPrkgDampg.BmwPwrPrkgDampgMaxRate
    connect CalRegn01Inin00GroupA.EpsStEstimnMtrxA -> EpsStEstimn.EpsStEstimnMtrxA
    connect CalRegn01Inin00GroupA.EpsStEstimnMtrxB -> EpsStEstimn.EpsStEstimnMtrxB
    connect CalRegn01Inin00GroupA.EpsStEstimnMtrxC -> EpsStEstimn.EpsStEstimnMtrxC
    connect CalRegn01Inin00GroupA.EpsStEstimnMtrxD -> EpsStEstimn.EpsStEstimnMtrxD
    connect CalRegn01Inin00GroupA.HwTqTrakgCtrlFbGain{1..5} -> HwTqTrakgCtrl.HwTqTrakgCtrlFbGain{1..5}
    connect CalRegn01Inin00GroupA.HwTqTrakgCtrlFfGainScaY -> HwTqTrakgCtrl.HwTqTrakgCtrlFfGainScaY
    connect CalRegn01Inin00GroupA.HwTqTrakgCtrlVehSpdScaX -> HwTqTrakgCtrl.HwTqTrakgCtrlVehSpdScaX
    connect CalRegn01Inin00GroupA.PosnTrakgServoEnaBlndFacTblX -> PosnTrakgServo.PosnTrakgServoEnaBlndFacTblX
    connect CalRegn01Inin00GroupA.PosnTrakgServoEnaBlndFacTblY -> PosnTrakgServo.PosnTrakgServoEnaBlndFacTblY
    connect CalRegn01Inin00GroupA.PosnTrakgServoGainArbnFltMtgtn -> PosnTrakgServo.PosnTrakgServoGainArbnFltMtgtn
    connect CalRegn01Inin00GroupA.PullCmpActvCmpLrnTiDecShoTerm -> PullCmpActv.PullCmpActvCmpLrnTiDecShoTerm
    connect CalRegn01Inin00GroupA.PullCmpActvCmpLrnTiIncShoTerm -> PullCmpActv.PullCmpActvCmpLrnTiIncShoTerm
    connect CalRegn01Inin00GroupA.PullCmpActvCmpLrnTiLongTerm -> PullCmpActv.PullCmpActvCmpLrnTiLongTerm
    connect CalRegn01Inin00GroupA.PullCmpActvCmpShoTermRstHwAgThd -> PullCmpActv.PullCmpActvCmpShoTermRstHwAgThd
    connect CalRegn01Inin00GroupA.PullCmpActvCmpShoTermRstHwTqThd -> PullCmpActv.PullCmpActvCmpShoTermRstHwTqThd
    connect CalRegn01Inin00GroupA.PullCmpActvCmpShoTermRstLatAThd -> PullCmpActv.PullCmpActvCmpShoTermRstLatAThd
    connect CalRegn01Inin00GroupA.PullCmpActvCmpShoTermRstYawRateThd -> PullCmpActv.PullCmpActvCmpShoTermRstYawRateThd
    connect CalRegn01Inin00GroupA.PullCmpActvEna -> PullCmpActv.PullCmpActvEna
    connect CalRegn01Inin00GroupA.PullCmpActvHwTqFilFrqLongTerm -> PullCmpActv.PullCmpActvHwTqFilFrqLongTerm
    connect CalRegn01Inin00GroupA.PullCmpActvHwTqFilFrqShoTerm -> PullCmpActv.PullCmpActvHwTqFilFrqShoTerm
    connect CalRegn01Inin00GroupA.PullCmpActvLongTermLim -> PullCmpActv.PullCmpActvLongTermLim
    connect CalRegn01Inin00GroupA.PullCmpActvLrngEnaAgConfMinMgn -> PullCmpActv.PullCmpActvLrngEnaAgConfMinMgn
    connect CalRegn01Inin00GroupA.PullCmpActvLrngEnaHwAgMaxMgn -> PullCmpActv.PullCmpActvLrngEnaHwAgMaxMgn
    connect CalRegn01Inin00GroupA.PullCmpActvLrngEnaHwTqMaxMgn -> PullCmpActv.PullCmpActvLrngEnaHwTqMaxMgn
    connect CalRegn01Inin00GroupA.PullCmpActvLrngEnaHwVelMaxMgn -> PullCmpActv.PullCmpActvLrngEnaHwVelMaxMgn
    connect CalRegn01Inin00GroupA.PullCmpActvLrngEnaLatAMaxMgn -> PullCmpActv.PullCmpActvLrngEnaLatAMaxMgn
    connect CalRegn01Inin00GroupA.PullCmpActvLrngEnaTiThd -> PullCmpActv.PullCmpActvLrngEnaTiThd
    connect CalRegn01Inin00GroupA.PullCmpActvLrngEnaVehSpdMaxMgn -> PullCmpActv.PullCmpActvLrngEnaVehSpdMaxMgn
    connect CalRegn01Inin00GroupA.PullCmpActvLrngEnaVehSpdMinMgn -> PullCmpActv.PullCmpActvLrngEnaVehSpdMinMgn
    connect CalRegn01Inin00GroupA.PullCmpActvLrngEnaVehSpdRateMaxMgn -> PullCmpActv.PullCmpActvLrngEnaVehSpdRateMaxMgn
    connect CalRegn01Inin00GroupA.PullCmpActvLrngEnaYawRateMaxMgn -> PullCmpActv.PullCmpActvLrngEnaYawRateMaxMgn
    connect CalRegn01Inin00GroupA.PullCmpActvOpstSignTiShoTerm -> PullCmpActv.PullCmpActvOpstSignTiShoTerm
    connect CalRegn01Inin00GroupA.PullCmpActvOutpMaxRate -> PullCmpActv.PullCmpActvOutpMaxRate
    connect CalRegn01Inin00GroupA.PullCmpActvPullCmpShoTermLim -> PullCmpActv.PullCmpActvPullCmpShoTermLim
    connect CalRegn01Inin00GroupA.PullCmpActvPullCmpTotLim -> PullCmpActv.PullCmpActvPullCmpTotLim
    connect CalRegn01Inin00GroupA.PullCmpActvPullErrLimLongTerm -> PullCmpActv.PullCmpActvPullErrLimLongTerm
    connect CalRegn01Inin00GroupA.PullCmpActvPullErrMgnThd -> PullCmpActv.PullCmpActvPullErrMgnThd
    connect CalRegn01Inin00GroupA.PullCmpActvPullErrShoTermLim -> PullCmpActv.PullCmpActvPullErrShoTermLim
    connect CalRegn01Inin00GroupA.PullCmpActvShoTermRampTi -> PullCmpActv.PullCmpActvShoTermRampTi
    connect CalRegn01Inin00GroupA.PullCmpActvVehSpdScaTblX -> PullCmpActv.PullCmpActvVehSpdScaTblX
    connect CalRegn01Inin00GroupA.PullCmpActvVehSpdScaTblY -> PullCmpActv.PullCmpActvVehSpdScaTblY
    connect CalRegn01Inin00GroupC.CtrldVelRtnDesVelLpFilFrq -> AAACalRegn01Inin00GroupC_Dummy.CtrldVelRtnDesVelLpFilFrq
    connect CalRegn01Inin00GroupC.CtrldVelRtnHwTqLpFilFrq -> AAACalRegn01Inin00GroupC_Dummy.CtrldVelRtnHwTqLpFilFrq
    connect CalRegn01Inin00GroupC.CtrldVelRtnHwTqScaSelnSlewHiLim -> AAACalRegn01Inin00GroupC_Dummy.CtrldVelRtnHwTqScaSelnSlewHiLim
    connect CalRegn01Inin00GroupC.CtrldVelRtnHwTqScaSelnSlewLoLim -> AAACalRegn01Inin00GroupC_Dummy.CtrldVelRtnHwTqScaSelnSlewLoLim
    connect CalRegn01Inin00GroupC.CtrldVelRtnHwTqScaSelnTqThd -> AAACalRegn01Inin00GroupC_Dummy.CtrldVelRtnHwTqScaSelnTqThd
    connect CalRegn01Inin00GroupC.CtrldVelRtnHwTqScaSelnVelThd -> AAACalRegn01Inin00GroupC_Dummy.CtrldVelRtnHwTqScaSelnVelThd
    connect CalRegn01Inin00GroupC.CtrldVelRtnIntgrLimY -> AAACalRegn01Inin00GroupC_Dummy.CtrldVelRtnIntgrLimY
    connect CalRegn01Inin00GroupC.CtrldVelRtnOffsSlewThd -> AAACalRegn01Inin00GroupC_Dummy.CtrldVelRtnOffsSlewThd
    connect CalRegn01Inin00GroupC.CtrldVelRtnOffsThd -> AAACalRegn01Inin00GroupC_Dummy.CtrldVelRtnOffsThd
    connect CalRegn01Inin00GroupC.CtrldVelRtnScaLpFilFrq -> AAACalRegn01Inin00GroupC_Dummy.CtrldVelRtnScaLpFilFrq
    connect CalRegn01Inin00GroupC.FalbckAssiAssiX -> AAACalRegn01Inin00GroupC_Dummy.FalbckAssiAssiX
    connect CalRegn01Inin00GroupC.FalbckAssiAssiY -> AAACalRegn01Inin00GroupC_Dummy.FalbckAssiAssiY
    connect CalRegn01Inin00GroupC.FalbckAssiNotchFil -> AAACalRegn01Inin00GroupC_Dummy.FalbckAssiNotchFil
    connect CalRegn01Inin00GroupC.GlbLimrBndX -> AAACalRegn01Inin00GroupC_Dummy.GlbLimrBndX
    connect CalRegn01Inin00GroupC.GlbLimrBndY -> AAACalRegn01Inin00GroupC_Dummy.GlbLimrBndY
    connect CalRegn01Inin00GroupC.GlbLimrNotchFilStruct -> AAACalRegn01Inin00GroupC_Dummy.GlbLimrNotchFilStruct
    connect CalRegn01Inin00GroupC.GlbLimrVehSpdBilnrSeln -> AAACalRegn01Inin00GroupC_Dummy.GlbLimrVehSpdBilnrSeln
    connect CalRegn01Inin00GroupC.CtrldVelRtnDesVelLpFilFrq -> CtrldVelRtn.CtrldVelRtnDesVelLpFilFrq
    connect CalRegn01Inin00GroupC.CtrldVelRtnHwTqLpFilFrq -> CtrldVelRtn.CtrldVelRtnHwTqLpFilFrq
    connect CalRegn01Inin00GroupC.CtrldVelRtnHwTqScaSelnSlewHiLim -> CtrldVelRtn.CtrldVelRtnHwTqScaSelnSlewHiLim
    connect CalRegn01Inin00GroupC.CtrldVelRtnHwTqScaSelnSlewLoLim -> CtrldVelRtn.CtrldVelRtnHwTqScaSelnSlewLoLim
    connect CalRegn01Inin00GroupC.CtrldVelRtnHwTqScaSelnTqThd -> CtrldVelRtn.CtrldVelRtnHwTqScaSelnTqThd
    connect CalRegn01Inin00GroupC.CtrldVelRtnHwTqScaSelnVelThd -> CtrldVelRtn.CtrldVelRtnHwTqScaSelnVelThd
    connect CalRegn01Inin00GroupC.CtrldVelRtnIntgrLimY -> CtrldVelRtn.CtrldVelRtnIntgrLimY
    connect CalRegn01Inin00GroupC.CtrldVelRtnOffsSlewThd -> CtrldVelRtn.CtrldVelRtnOffsSlewThd
    connect CalRegn01Inin00GroupC.CtrldVelRtnOffsThd -> CtrldVelRtn.CtrldVelRtnOffsThd
    connect CalRegn01Inin00GroupC.CtrldVelRtnScaLpFilFrq -> CtrldVelRtn.CtrldVelRtnScaLpFilFrq
    connect CalRegn01Inin00GroupC.FalbckAssiAssiX -> FalbckAssi.FalbckAssiAssiX
    connect CalRegn01Inin00GroupC.FalbckAssiAssiY -> FalbckAssi.FalbckAssiAssiY
    connect CalRegn01Inin00GroupC.FalbckAssiNotchFil -> FalbckAssi.FalbckAssiNotchFil
    connect CalRegn01Inin00GroupC.GlbLimrBndX -> GlbLimr.GlbLimrBndX
    connect CalRegn01Inin00GroupC.GlbLimrBndY -> GlbLimr.GlbLimrBndY
    connect CalRegn01Inin00GroupC.GlbLimrNotchFilStruct -> GlbLimr.GlbLimrNotchFilStruct
    connect CalRegn01Inin00GroupC.GlbLimrVehSpdBilnrSeln -> GlbLimr.GlbLimrVehSpdBilnrSeln
    connect CalRegn01Inin00GroupD.EotProtnDampgVehSpdTbl -> AAACalRegn01Inin00GroupD_Dummy.EotProtnDampgVehSpdTbl
    connect CalRegn01Inin00GroupD.EotProtnDeltaTqThd -> AAACalRegn01Inin00GroupD_Dummy.EotProtnDeltaTqThd
    connect CalRegn01Inin00GroupD.EotProtnEntrGainAuthyThd -> AAACalRegn01Inin00GroupD_Dummy.EotProtnEntrGainAuthyThd
    connect CalRegn01Inin00GroupD.EotProtnEntrGainVehSpdTbl -> AAACalRegn01Inin00GroupD_Dummy.EotProtnEntrGainVehSpdTbl
    connect CalRegn01Inin00GroupD.EotProtnEntrGainX -> AAACalRegn01Inin00GroupD_Dummy.EotProtnEntrGainX
    connect CalRegn01Inin00GroupD.EotProtnEntrGainY -> AAACalRegn01Inin00GroupD_Dummy.EotProtnEntrGainY
    connect CalRegn01Inin00GroupD.EotProtnEntrStLpFilFrq -> AAACalRegn01Inin00GroupD_Dummy.EotProtnEntrStLpFilFrq
    connect CalRegn01Inin00GroupD.EotProtnExitDampgY -> AAACalRegn01Inin00GroupD_Dummy.EotProtnExitDampgY
    connect CalRegn01Inin00GroupD.EotProtnExitStLpFilFrq -> AAACalRegn01Inin00GroupD_Dummy.EotProtnExitStLpFilFrq
    connect CalRegn01Inin00GroupD.EotProtnHwDegDampgX -> AAACalRegn01Inin00GroupD_Dummy.EotProtnHwDegDampgX
    connect CalRegn01Inin00GroupD.EotProtnHwTqLpFilFrq -> AAACalRegn01Inin00GroupD_Dummy.EotProtnHwTqLpFilFrq
    connect CalRegn01Inin00GroupD.EotProtnHwTqScaX -> AAACalRegn01Inin00GroupD_Dummy.EotProtnHwTqScaX
    connect CalRegn01Inin00GroupD.EotProtnLoAuthyEntrGainY -> AAACalRegn01Inin00GroupD_Dummy.EotProtnLoAuthyEntrGainY
    connect CalRegn01Inin00GroupD.EotProtnMotSpdIncptSca -> AAACalRegn01Inin00GroupD_Dummy.EotProtnMotSpdIncptSca
    connect CalRegn01Inin00GroupD.EotProtnMotSpdIncptX -> AAACalRegn01Inin00GroupD_Dummy.EotProtnMotSpdIncptX
    connect CalRegn01Inin00GroupD.EotProtnMotSpdIncptY -> AAACalRegn01Inin00GroupD_Dummy.EotProtnMotSpdIncptY
    connect CalRegn01Inin00GroupD.EotProtnMotVelGain -> AAACalRegn01Inin00GroupD_Dummy.EotProtnMotVelGain
    connect CalRegn01Inin00GroupD.EotProtnNormDampgY -> AAACalRegn01Inin00GroupD_Dummy.EotProtnNormDampgY
    connect CalRegn01Inin00GroupD.EotProtnPosnRampStep -> AAACalRegn01Inin00GroupD_Dummy.EotProtnPosnRampStep
    connect CalRegn01Inin00GroupD.EotProtnRackTrvlLimrAuthyThd -> AAACalRegn01Inin00GroupD_Dummy.EotProtnRackTrvlLimrAuthyThd
    connect CalRegn01Inin00GroupD.EotProtnRackTrvlLimrAuthyThdLimd -> AAACalRegn01Inin00GroupD_Dummy.EotProtnRackTrvlLimrAuthyThdLimd
    connect CalRegn01Inin00GroupD.EotProtnRackTrvlLimrRng -> AAACalRegn01Inin00GroupD_Dummy.EotProtnRackTrvlLimrRng
    connect CalRegn01Inin00GroupD.EotProtnRackTrvlLimrRngLimd -> AAACalRegn01Inin00GroupD_Dummy.EotProtnRackTrvlLimrRngLimd
    connect CalRegn01Inin00GroupD.EotProtnRackTrvlLimrVehSpdThd -> AAACalRegn01Inin00GroupD_Dummy.EotProtnRackTrvlLimrVehSpdThd
    connect CalRegn01Inin00GroupD.EotProtnRunEotVelImpctAndSoftEndStop -> AAACalRegn01Inin00GroupD_Dummy.EotProtnRunEotVelImpctAndSoftEndStop
    connect CalRegn01Inin00GroupD.InertiaCmpVelAssiBasdDampgCoeffX -> AAACalRegn01Inin00GroupD_Dummy.InertiaCmpVelAssiBasdDampgCoeffX
    connect CalRegn01Inin00GroupD.InertiaCmpVelAssiBasdDampgRollgWhlImbRejctnOnY -> AAACalRegn01Inin00GroupD_Dummy.InertiaCmpVelAssiBasdDampgRollgWhlImbRejctnOnY
    connect CalRegn01Inin00GroupD.InertiaCmpVelAssiBasdDampgRollgY -> AAACalRegn01Inin00GroupD_Dummy.InertiaCmpVelAssiBasdDampgRollgY
    connect CalRegn01Inin00GroupD.InertiaCmpVelAssiBasdDampgStatWhlImbRejctnOnY -> AAACalRegn01Inin00GroupD_Dummy.InertiaCmpVelAssiBasdDampgStatWhlImbRejctnOnY
    connect CalRegn01Inin00GroupD.InertiaCmpVelAssiBasdDampgStatY -> AAACalRegn01Inin00GroupD_Dummy.InertiaCmpVelAssiBasdDampgStatY
    connect CalRegn01Inin00GroupD.InertiaCmpVelCmdScaY -> AAACalRegn01Inin00GroupD_Dummy.InertiaCmpVelCmdScaY
    connect CalRegn01Inin00GroupD.InertiaCmpVelDampgDecelGain -> AAACalRegn01Inin00GroupD_Dummy.InertiaCmpVelDampgDecelGain
    connect CalRegn01Inin00GroupD.InertiaCmpVelDampgDecelGainFallSlew -> AAACalRegn01Inin00GroupD_Dummy.InertiaCmpVelDampgDecelGainFallSlew
    connect CalRegn01Inin00GroupD.InertiaCmpVelDampgDecelGainRisngSlewX -> AAACalRegn01Inin00GroupD_Dummy.InertiaCmpVelDampgDecelGainRisngSlewX
    connect CalRegn01Inin00GroupD.InertiaCmpVelDampgDecelGainRisngSlewY -> AAACalRegn01Inin00GroupD_Dummy.InertiaCmpVelDampgDecelGainRisngSlewY
    connect CalRegn01Inin00GroupD.InertiaCmpVelDampgFilFrq -> AAACalRegn01Inin00GroupD_Dummy.InertiaCmpVelDampgFilFrq
    connect CalRegn01Inin00GroupD.InertiaCmpVelDampgFilFrqWhlImbRejctnOn -> AAACalRegn01Inin00GroupD_Dummy.InertiaCmpVelDampgFilFrqWhlImbRejctnOn
    connect CalRegn01Inin00GroupD.InertiaCmpVelDampgGainOffThd -> AAACalRegn01Inin00GroupD_Dummy.InertiaCmpVelDampgGainOffThd
    connect CalRegn01Inin00GroupD.InertiaCmpVelDampgGainOnThd -> AAACalRegn01Inin00GroupD_Dummy.InertiaCmpVelDampgGainOnThd
    connect CalRegn01Inin00GroupD.InertiaCmpVelDampgSpdBlndY -> AAACalRegn01Inin00GroupD_Dummy.InertiaCmpVelDampgSpdBlndY
    connect CalRegn01Inin00GroupD.InertiaCmpVelDampgWhlImbRejctnBlndX -> AAACalRegn01Inin00GroupD_Dummy.InertiaCmpVelDampgWhlImbRejctnBlndX
    connect CalRegn01Inin00GroupD.InertiaCmpVelDampgWhlImbRejctnBlndY -> AAACalRegn01Inin00GroupD_Dummy.InertiaCmpVelDampgWhlImbRejctnBlndY
    connect CalRegn01Inin00GroupD.InertiaCmpVelDecelGainEnaCal -> AAACalRegn01Inin00GroupD_Dummy.InertiaCmpVelDecelGainEnaCal
    connect CalRegn01Inin00GroupD.InertiaCmpVelModWhlImbRejctnBlndX -> AAACalRegn01Inin00GroupD_Dummy.InertiaCmpVelModWhlImbRejctnBlndX
    connect CalRegn01Inin00GroupD.InertiaCmpVelModWhlImbRejctnBlndY -> AAACalRegn01Inin00GroupD_Dummy.InertiaCmpVelModWhlImbRejctnBlndY
    connect CalRegn01Inin00GroupD.InertiaCmpVelMotInertia -> AAACalRegn01Inin00GroupD_Dummy.InertiaCmpVelMotInertia
    connect CalRegn01Inin00GroupD.InertiaCmpVelMotVelBasdOutpScagX -> AAACalRegn01Inin00GroupD_Dummy.InertiaCmpVelMotVelBasdOutpScagX
    connect CalRegn01Inin00GroupD.InertiaCmpVelMotVelBasdOutpScagY -> AAACalRegn01Inin00GroupD_Dummy.InertiaCmpVelMotVelBasdOutpScagY
    connect CalRegn01Inin00GroupD.InertiaCmpVelNotchBlndY -> AAACalRegn01Inin00GroupD_Dummy.InertiaCmpVelNotchBlndY
    connect CalRegn01Inin00GroupD.InertiaCmpVelNotchFilStruct -> AAACalRegn01Inin00GroupD_Dummy.InertiaCmpVelNotchFilStruct
    connect CalRegn01Inin00GroupD.InertiaCmpVelTqSnsrVelFilFrq -> AAACalRegn01Inin00GroupD_Dummy.InertiaCmpVelTqSnsrVelFilFrq
    connect CalRegn01Inin00GroupD.InertiaCmpVelTqSnsrVelSca -> AAACalRegn01Inin00GroupD_Dummy.InertiaCmpVelTqSnsrVelSca
    connect CalRegn01Inin00GroupD.EotProtnDampgVehSpdTbl -> EotProtn.EotProtnDampgVehSpdTbl
    connect CalRegn01Inin00GroupD.EotProtnDeltaTqThd -> EotProtn.EotProtnDeltaTqThd
    connect CalRegn01Inin00GroupD.EotProtnEntrGainAuthyThd -> EotProtn.EotProtnEntrGainAuthyThd
    connect CalRegn01Inin00GroupD.EotProtnEntrGainVehSpdTbl -> EotProtn.EotProtnEntrGainVehSpdTbl
    connect CalRegn01Inin00GroupD.EotProtnEntrGainX -> EotProtn.EotProtnEntrGainX
    connect CalRegn01Inin00GroupD.EotProtnEntrGainY -> EotProtn.EotProtnEntrGainY
    connect CalRegn01Inin00GroupD.EotProtnEntrStLpFilFrq -> EotProtn.EotProtnEntrStLpFilFrq
    connect CalRegn01Inin00GroupD.EotProtnExitDampgY -> EotProtn.EotProtnExitDampgY
    connect CalRegn01Inin00GroupD.EotProtnExitStLpFilFrq -> EotProtn.EotProtnExitStLpFilFrq
    connect CalRegn01Inin00GroupD.EotProtnHwDegDampgX -> EotProtn.EotProtnHwDegDampgX
    connect CalRegn01Inin00GroupD.EotProtnHwTqLpFilFrq -> EotProtn.EotProtnHwTqLpFilFrq
    connect CalRegn01Inin00GroupD.EotProtnHwTqScaX -> EotProtn.EotProtnHwTqScaX
    connect CalRegn01Inin00GroupD.EotProtnLoAuthyEntrGainY -> EotProtn.EotProtnLoAuthyEntrGainY
    connect CalRegn01Inin00GroupD.EotProtnMotSpdIncptSca -> EotProtn.EotProtnMotSpdIncptSca
    connect CalRegn01Inin00GroupD.EotProtnMotSpdIncptX -> EotProtn.EotProtnMotSpdIncptX
    connect CalRegn01Inin00GroupD.EotProtnMotSpdIncptY -> EotProtn.EotProtnMotSpdIncptY
    connect CalRegn01Inin00GroupD.EotProtnMotVelGain -> EotProtn.EotProtnMotVelGain
    connect CalRegn01Inin00GroupD.EotProtnNormDampgY -> EotProtn.EotProtnNormDampgY
    connect CalRegn01Inin00GroupD.EotProtnPosnRampStep -> EotProtn.EotProtnPosnRampStep
    connect CalRegn01Inin00GroupD.EotProtnRackTrvlLimrAuthyThd -> EotProtn.EotProtnRackTrvlLimrAuthyThd
    connect CalRegn01Inin00GroupD.EotProtnRackTrvlLimrAuthyThdLimd -> EotProtn.EotProtnRackTrvlLimrAuthyThdLimd
    connect CalRegn01Inin00GroupD.EotProtnRackTrvlLimrRng -> EotProtn.EotProtnRackTrvlLimrRng
    connect CalRegn01Inin00GroupD.EotProtnRackTrvlLimrRngLimd -> EotProtn.EotProtnRackTrvlLimrRngLimd
    connect CalRegn01Inin00GroupD.EotProtnRackTrvlLimrVehSpdThd -> EotProtn.EotProtnRackTrvlLimrVehSpdThd
    connect CalRegn01Inin00GroupD.EotProtnRunEotVelImpctAndSoftEndStop -> EotProtn.EotProtnRunEotVelImpctAndSoftEndStop
    connect CalRegn01Inin00GroupD.InertiaCmpVelAssiBasdDampgCoeffX -> InertiaCmpVel.InertiaCmpVelAssiBasdDampgCoeffX
    connect CalRegn01Inin00GroupD.InertiaCmpVelAssiBasdDampgRollgWhlImbRejctnOnY -> InertiaCmpVel.InertiaCmpVelAssiBasdDampgRollgWhlImbRejctnOnY
    connect CalRegn01Inin00GroupD.InertiaCmpVelAssiBasdDampgRollgY -> InertiaCmpVel.InertiaCmpVelAssiBasdDampgRollgY
    connect CalRegn01Inin00GroupD.InertiaCmpVelAssiBasdDampgStatWhlImbRejctnOnY -> InertiaCmpVel.InertiaCmpVelAssiBasdDampgStatWhlImbRejctnOnY
    connect CalRegn01Inin00GroupD.InertiaCmpVelAssiBasdDampgStatY -> InertiaCmpVel.InertiaCmpVelAssiBasdDampgStatY
    connect CalRegn01Inin00GroupD.InertiaCmpVelCmdScaY -> InertiaCmpVel.InertiaCmpVelCmdScaY
    connect CalRegn01Inin00GroupD.InertiaCmpVelDampgDecelGain -> InertiaCmpVel.InertiaCmpVelDampgDecelGain
    connect CalRegn01Inin00GroupD.InertiaCmpVelDampgDecelGainFallSlew -> InertiaCmpVel.InertiaCmpVelDampgDecelGainFallSlew
    connect CalRegn01Inin00GroupD.InertiaCmpVelDampgDecelGainRisngSlewX -> InertiaCmpVel.InertiaCmpVelDampgDecelGainRisngSlewX
    connect CalRegn01Inin00GroupD.InertiaCmpVelDampgDecelGainRisngSlewY -> InertiaCmpVel.InertiaCmpVelDampgDecelGainRisngSlewY
    connect CalRegn01Inin00GroupD.InertiaCmpVelDampgFilFrq -> InertiaCmpVel.InertiaCmpVelDampgFilFrq
    connect CalRegn01Inin00GroupD.InertiaCmpVelDampgFilFrqWhlImbRejctnOn -> InertiaCmpVel.InertiaCmpVelDampgFilFrqWhlImbRejctnOn
    connect CalRegn01Inin00GroupD.InertiaCmpVelDampgGainOffThd -> InertiaCmpVel.InertiaCmpVelDampgGainOffThd
    connect CalRegn01Inin00GroupD.InertiaCmpVelDampgGainOnThd -> InertiaCmpVel.InertiaCmpVelDampgGainOnThd
    connect CalRegn01Inin00GroupD.InertiaCmpVelDampgSpdBlndY -> InertiaCmpVel.InertiaCmpVelDampgSpdBlndY
    connect CalRegn01Inin00GroupD.InertiaCmpVelDampgWhlImbRejctnBlndX -> InertiaCmpVel.InertiaCmpVelDampgWhlImbRejctnBlndX
    connect CalRegn01Inin00GroupD.InertiaCmpVelDampgWhlImbRejctnBlndY -> InertiaCmpVel.InertiaCmpVelDampgWhlImbRejctnBlndY
    connect CalRegn01Inin00GroupD.InertiaCmpVelDecelGainEnaCal -> InertiaCmpVel.InertiaCmpVelDecelGainEnaCal
    connect CalRegn01Inin00GroupD.InertiaCmpVelModWhlImbRejctnBlndX -> InertiaCmpVel.InertiaCmpVelModWhlImbRejctnBlndX
    connect CalRegn01Inin00GroupD.InertiaCmpVelModWhlImbRejctnBlndY -> InertiaCmpVel.InertiaCmpVelModWhlImbRejctnBlndY
    connect CalRegn01Inin00GroupD.InertiaCmpVelMotInertia -> InertiaCmpVel.InertiaCmpVelMotInertia
    connect CalRegn01Inin00GroupD.InertiaCmpVelMotVelBasdOutpScagX -> InertiaCmpVel.InertiaCmpVelMotVelBasdOutpScagX
    connect CalRegn01Inin00GroupD.InertiaCmpVelMotVelBasdOutpScagY -> InertiaCmpVel.InertiaCmpVelMotVelBasdOutpScagY
    connect CalRegn01Inin00GroupD.InertiaCmpVelNotchBlndY -> InertiaCmpVel.InertiaCmpVelNotchBlndY
    connect CalRegn01Inin00GroupD.InertiaCmpVelNotchFilStruct -> InertiaCmpVel.InertiaCmpVelNotchFilStruct
    connect CalRegn01Inin00GroupD.InertiaCmpVelTqSnsrVelFilFrq -> InertiaCmpVel.InertiaCmpVelTqSnsrVelFilFrq
    connect CalRegn01Inin00GroupD.InertiaCmpVelTqSnsrVelSca -> InertiaCmpVel.InertiaCmpVelTqSnsrVelSca
    connect CalRegn01Inin01.BmwHwAgArbnAndEotPosnKineIntegrityDiagcMaxRackLim -> AAACalRegn01Inin01_Dummy.BmwHwAgArbnAndEotPosnKineIntegrityDiagcMaxRackLim
    connect CalRegn01Inin01.EffortScaBlndX -> AAACalRegn01Inin01_Dummy.EffortScaBlndX
    connect CalRegn01Inin01.EffortScaBlndY -> AAACalRegn01Inin01_Dummy.EffortScaBlndY
    connect CalRegn01Inin01.EffortScaRackFThd -> AAACalRegn01Inin01_Dummy.EffortScaRackFThd
    connect CalRegn01Inin01.PosnTrakgServoArbnFltMtgtnLpFilCutOffFrq -> AAACalRegn01Inin01_Dummy.PosnTrakgServoArbnFltMtgtnLpFilCutOffFrq
    connect CalRegn01Inin01.PullCmpActvHwTqFilFrqLrngEna -> AAACalRegn01Inin01_Dummy.PullCmpActvHwTqFilFrqLrngEna
    connect CalRegn01Inin01.PullCmpActvYawRateFilFrq -> AAACalRegn01Inin01_Dummy.PullCmpActvYawRateFilFrq
    connect CalRegn01Inin01.SysFricLrngAvrgFricFrq -> AAACalRegn01Inin01_Dummy.SysFricLrngAvrgFricFrq
    connect CalRegn01Inin01.SysFricLrngBasLineEolFric -> AAACalRegn01Inin01_Dummy.SysFricLrngBasLineEolFric
    connect CalRegn01Inin01.SysFricLrngBasLineFric -> AAACalRegn01Inin01_Dummy.SysFricLrngBasLineFric
    connect CalRegn01Inin01.SysFricLrngBasLineHys -> AAACalRegn01Inin01_Dummy.SysFricLrngBasLineHys
    connect CalRegn01Inin01.SysFricLrngBasLineRngCntr -> AAACalRegn01Inin01_Dummy.SysFricLrngBasLineRngCntr
    connect CalRegn01Inin01.SysFricLrngDataPrepLpFilFrq -> AAACalRegn01Inin01_Dummy.SysFricLrngDataPrepLpFilFrq
    connect CalRegn01Inin01.SysFricLrngDebStep -> AAACalRegn01Inin01_Dummy.SysFricLrngDebStep
    connect CalRegn01Inin01.SysFricLrngEolFricDifHiLim -> AAACalRegn01Inin01_Dummy.SysFricLrngEolFricDifHiLim
    connect CalRegn01Inin01.SysFricLrngEolFricDifLoLim -> AAACalRegn01Inin01_Dummy.SysFricLrngEolFricDifLoLim
    connect CalRegn01Inin01.SysFricLrngEolFricDifScagFac -> AAACalRegn01Inin01_Dummy.SysFricLrngEolFricDifScagFac
    connect CalRegn01Inin01.SysFricLrngFricChgWght -> AAACalRegn01Inin01_Dummy.SysFricLrngFricChgWght
    connect CalRegn01Inin01.SysFricLrngFricDiagcThd -> AAACalRegn01Inin01_Dummy.SysFricLrngFricDiagcThd
    connect CalRegn01Inin01.SysFricLrngFricHysHwAgPt -> AAACalRegn01Inin01_Dummy.SysFricLrngFricHysHwAgPt
    connect CalRegn01Inin01.SysFricLrngFricOffs -> AAACalRegn01Inin01_Dummy.SysFricLrngFricOffs
    connect CalRegn01Inin01.SysFricLrngFricOffsHiLim -> AAACalRegn01Inin01_Dummy.SysFricLrngFricOffsHiLim
    connect CalRegn01Inin01.SysFricLrngFricOffsLoLim -> AAACalRegn01Inin01_Dummy.SysFricLrngFricOffsLoLim
    connect CalRegn01Inin01.SysFricLrngFricOffsLpFilFrq -> AAACalRegn01Inin01_Dummy.SysFricLrngFricOffsLpFilFrq
    connect CalRegn01Inin01.SysFricLrngGain -> AAACalRegn01Inin01_Dummy.SysFricLrngGain
    connect CalRegn01Inin01.SysFricLrngHiFricDebStep -> AAACalRegn01Inin01_Dummy.SysFricLrngHiFricDebStep
    connect CalRegn01Inin01.SysFricLrngHiFricDiagcThd -> AAACalRegn01Inin01_Dummy.SysFricLrngHiFricDiagcThd
    connect CalRegn01Inin01.SysFricLrngHwPosnAuthyThd -> AAACalRegn01Inin01_Dummy.SysFricLrngHwPosnAuthyThd
    connect CalRegn01Inin01.SysFricLrngHwVelConstrLim -> AAACalRegn01Inin01_Dummy.SysFricLrngHwVelConstrLim
    connect CalRegn01Inin01.SysFricLrngHwVelHiLim -> AAACalRegn01Inin01_Dummy.SysFricLrngHwVelHiLim
    connect CalRegn01Inin01.SysFricLrngHwVelLoLim -> AAACalRegn01Inin01_Dummy.SysFricLrngHwVelLoLim
    connect CalRegn01Inin01.SysFricLrngIgnCycFricChgLim -> AAACalRegn01Inin01_Dummy.SysFricLrngIgnCycFricChgLim
    connect CalRegn01Inin01.SysFricLrngIgnCycFricOffs -> AAACalRegn01Inin01_Dummy.SysFricLrngIgnCycFricOffs
    connect CalRegn01Inin01.SysFricLrngIvsTrsmRatX -> AAACalRegn01Inin01_Dummy.SysFricLrngIvsTrsmRatX
    connect CalRegn01Inin01.SysFricLrngIvsTrsmRatY -> AAACalRegn01Inin01_Dummy.SysFricLrngIvsTrsmRatY
    connect CalRegn01Inin01.SysFricLrngLatAHiLim -> AAACalRegn01Inin01_Dummy.SysFricLrngLatAHiLim
    connect CalRegn01Inin01.SysFricLrngLatALoLim -> AAACalRegn01Inin01_Dummy.SysFricLrngLatALoLim
    connect CalRegn01Inin01.SysFricLrngMaskVehSpd -> AAACalRegn01Inin01_Dummy.SysFricLrngMaskVehSpd
    connect CalRegn01Inin01.SysFricLrngRngCntrThd -> AAACalRegn01Inin01_Dummy.SysFricLrngRngCntrThd
    connect CalRegn01Inin01.SysFricLrngThd -> AAACalRegn01Inin01_Dummy.SysFricLrngThd
    connect CalRegn01Inin01.SysFricLrngTHiLim -> AAACalRegn01Inin01_Dummy.SysFricLrngTHiLim
    connect CalRegn01Inin01.SysFricLrngTLoLim -> AAACalRegn01Inin01_Dummy.SysFricLrngTLoLim
    connect CalRegn01Inin01.SysFricLrngVehSpd -> AAACalRegn01Inin01_Dummy.SysFricLrngVehSpd
    connect CalRegn01Inin01.SysGlbPrmSysKineRat -> AAACalRegn01Inin01_Dummy.SysGlbPrmSysKineRat
    connect CalRegn01Inin01.SysGlbPrmVehSpdBilnrSeln -> AAACalRegn01Inin01_Dummy.SysGlbPrmVehSpdBilnrSeln
    connect CalRegn01Inin01.SysKineAndEffMotAgToRackPosRatScaY -> AAACalRegn01Inin01_Dummy.SysKineAndEffMotAgToRackPosRatScaY
    connect CalRegn01Inin01.SysKineAndEffPinionAgToRackPosRatScaY -> AAACalRegn01Inin01_Dummy.SysKineAndEffPinionAgToRackPosRatScaY
    connect CalRegn01Inin01.SysKineAndEffPinionToRackEffScaY -> AAACalRegn01Inin01_Dummy.SysKineAndEffPinionToRackEffScaY
    connect CalRegn01Inin01.SysKineAndEffRoadWhlFromRackPosScaY -> AAACalRegn01Inin01_Dummy.SysKineAndEffRoadWhlFromRackPosScaY
    connect CalRegn01Inin01.SysKineAndEffSteerArmLenFromRackPosScaY -> AAACalRegn01Inin01_Dummy.SysKineAndEffSteerArmLenFromRackPosScaY
    connect CalRegn01Inin01.TunSelnAuthyVehSpdX -> AAACalRegn01Inin01_Dummy.TunSelnAuthyVehSpdX
    connect CalRegn01Inin01GroupA.BmwHwAgArbnAndEotPosnEotCcwMax -> AAACalRegn01Inin01GroupA_Dummy.BmwHwAgArbnAndEotPosnEotCcwMax
    connect CalRegn01Inin01GroupA.BmwHwAgArbnAndEotPosnEotCcwMin -> AAACalRegn01Inin01GroupA_Dummy.BmwHwAgArbnAndEotPosnEotCcwMin
    connect CalRegn01Inin01GroupA.BmwHwAgArbnAndEotPosnEotCwMax -> AAACalRegn01Inin01GroupA_Dummy.BmwHwAgArbnAndEotPosnEotCwMax
    connect CalRegn01Inin01GroupA.BmwHwAgArbnAndEotPosnEotCwMin -> AAACalRegn01Inin01GroupA_Dummy.BmwHwAgArbnAndEotPosnEotCwMin
    connect CalRegn01Inin01GroupA.BmwPwrPrkgDampgDiScadDampg -> AAACalRegn01Inin01GroupA_Dummy.BmwPwrPrkgDampgDiScadDampg
    connect CalRegn01Inin01GroupA.BmwPwrPrkgDampgMaxRate -> AAACalRegn01Inin01GroupA_Dummy.BmwPwrPrkgDampgMaxRate
    connect CalRegn01Inin01GroupA.EpsStEstimnMtrxA -> AAACalRegn01Inin01GroupA_Dummy.EpsStEstimnMtrxA
    connect CalRegn01Inin01GroupA.EpsStEstimnMtrxB -> AAACalRegn01Inin01GroupA_Dummy.EpsStEstimnMtrxB
    connect CalRegn01Inin01GroupA.EpsStEstimnMtrxC -> AAACalRegn01Inin01GroupA_Dummy.EpsStEstimnMtrxC
    connect CalRegn01Inin01GroupA.EpsStEstimnMtrxD -> AAACalRegn01Inin01GroupA_Dummy.EpsStEstimnMtrxD
    connect CalRegn01Inin01GroupA.HwTqTrakgCtrlFbGain{1..5} -> AAACalRegn01Inin01GroupA_Dummy.HwTqTrakgCtrlFbGain{1..5}
    connect CalRegn01Inin01GroupA.HwTqTrakgCtrlFfGainScaY -> AAACalRegn01Inin01GroupA_Dummy.HwTqTrakgCtrlFfGainScaY
    connect CalRegn01Inin01GroupA.HwTqTrakgCtrlVehSpdScaX -> AAACalRegn01Inin01GroupA_Dummy.HwTqTrakgCtrlVehSpdScaX
    connect CalRegn01Inin01GroupA.PosnTrakgServoEnaBlndFacTblX -> AAACalRegn01Inin01GroupA_Dummy.PosnTrakgServoEnaBlndFacTblX
    connect CalRegn01Inin01GroupA.PosnTrakgServoEnaBlndFacTblY -> AAACalRegn01Inin01GroupA_Dummy.PosnTrakgServoEnaBlndFacTblY
    connect CalRegn01Inin01GroupA.PosnTrakgServoGainArbnFltMtgtn -> AAACalRegn01Inin01GroupA_Dummy.PosnTrakgServoGainArbnFltMtgtn
    connect CalRegn01Inin01GroupA.PullCmpActvCmpLrnTiDecShoTerm -> AAACalRegn01Inin01GroupA_Dummy.PullCmpActvCmpLrnTiDecShoTerm
    connect CalRegn01Inin01GroupA.PullCmpActvCmpLrnTiIncShoTerm -> AAACalRegn01Inin01GroupA_Dummy.PullCmpActvCmpLrnTiIncShoTerm
    connect CalRegn01Inin01GroupA.PullCmpActvCmpLrnTiLongTerm -> AAACalRegn01Inin01GroupA_Dummy.PullCmpActvCmpLrnTiLongTerm
    connect CalRegn01Inin01GroupA.PullCmpActvCmpShoTermRstHwAgThd -> AAACalRegn01Inin01GroupA_Dummy.PullCmpActvCmpShoTermRstHwAgThd
    connect CalRegn01Inin01GroupA.PullCmpActvCmpShoTermRstHwTqThd -> AAACalRegn01Inin01GroupA_Dummy.PullCmpActvCmpShoTermRstHwTqThd
    connect CalRegn01Inin01GroupA.PullCmpActvCmpShoTermRstLatAThd -> AAACalRegn01Inin01GroupA_Dummy.PullCmpActvCmpShoTermRstLatAThd
    connect CalRegn01Inin01GroupA.PullCmpActvCmpShoTermRstYawRateThd -> AAACalRegn01Inin01GroupA_Dummy.PullCmpActvCmpShoTermRstYawRateThd
    connect CalRegn01Inin01GroupA.PullCmpActvEna -> AAACalRegn01Inin01GroupA_Dummy.PullCmpActvEna
    connect CalRegn01Inin01GroupA.PullCmpActvHwTqFilFrqLongTerm -> AAACalRegn01Inin01GroupA_Dummy.PullCmpActvHwTqFilFrqLongTerm
    connect CalRegn01Inin01GroupA.PullCmpActvHwTqFilFrqShoTerm -> AAACalRegn01Inin01GroupA_Dummy.PullCmpActvHwTqFilFrqShoTerm
    connect CalRegn01Inin01GroupA.PullCmpActvLongTermLim -> AAACalRegn01Inin01GroupA_Dummy.PullCmpActvLongTermLim
    connect CalRegn01Inin01GroupA.PullCmpActvLrngEnaAgConfMinMgn -> AAACalRegn01Inin01GroupA_Dummy.PullCmpActvLrngEnaAgConfMinMgn
    connect CalRegn01Inin01GroupA.PullCmpActvLrngEnaHwAgMaxMgn -> AAACalRegn01Inin01GroupA_Dummy.PullCmpActvLrngEnaHwAgMaxMgn
    connect CalRegn01Inin01GroupA.PullCmpActvLrngEnaHwTqMaxMgn -> AAACalRegn01Inin01GroupA_Dummy.PullCmpActvLrngEnaHwTqMaxMgn
    connect CalRegn01Inin01GroupA.PullCmpActvLrngEnaHwVelMaxMgn -> AAACalRegn01Inin01GroupA_Dummy.PullCmpActvLrngEnaHwVelMaxMgn
    connect CalRegn01Inin01GroupA.PullCmpActvLrngEnaLatAMaxMgn -> AAACalRegn01Inin01GroupA_Dummy.PullCmpActvLrngEnaLatAMaxMgn
    connect CalRegn01Inin01GroupA.PullCmpActvLrngEnaTiThd -> AAACalRegn01Inin01GroupA_Dummy.PullCmpActvLrngEnaTiThd
    connect CalRegn01Inin01GroupA.PullCmpActvLrngEnaVehSpdMaxMgn -> AAACalRegn01Inin01GroupA_Dummy.PullCmpActvLrngEnaVehSpdMaxMgn
    connect CalRegn01Inin01GroupA.PullCmpActvLrngEnaVehSpdMinMgn -> AAACalRegn01Inin01GroupA_Dummy.PullCmpActvLrngEnaVehSpdMinMgn
    connect CalRegn01Inin01GroupA.PullCmpActvLrngEnaVehSpdRateMaxMgn -> AAACalRegn01Inin01GroupA_Dummy.PullCmpActvLrngEnaVehSpdRateMaxMgn
    connect CalRegn01Inin01GroupA.PullCmpActvLrngEnaYawRateMaxMgn -> AAACalRegn01Inin01GroupA_Dummy.PullCmpActvLrngEnaYawRateMaxMgn
    connect CalRegn01Inin01GroupA.PullCmpActvOpstSignTiShoTerm -> AAACalRegn01Inin01GroupA_Dummy.PullCmpActvOpstSignTiShoTerm
    connect CalRegn01Inin01GroupA.PullCmpActvOutpMaxRate -> AAACalRegn01Inin01GroupA_Dummy.PullCmpActvOutpMaxRate
    connect CalRegn01Inin01GroupA.PullCmpActvPullCmpShoTermLim -> AAACalRegn01Inin01GroupA_Dummy.PullCmpActvPullCmpShoTermLim
    connect CalRegn01Inin01GroupA.PullCmpActvPullCmpTotLim -> AAACalRegn01Inin01GroupA_Dummy.PullCmpActvPullCmpTotLim
    connect CalRegn01Inin01GroupA.PullCmpActvPullErrLimLongTerm -> AAACalRegn01Inin01GroupA_Dummy.PullCmpActvPullErrLimLongTerm
    connect CalRegn01Inin01GroupA.PullCmpActvPullErrMgnThd -> AAACalRegn01Inin01GroupA_Dummy.PullCmpActvPullErrMgnThd
    connect CalRegn01Inin01GroupA.PullCmpActvPullErrShoTermLim -> AAACalRegn01Inin01GroupA_Dummy.PullCmpActvPullErrShoTermLim
    connect CalRegn01Inin01GroupA.PullCmpActvShoTermRampTi -> AAACalRegn01Inin01GroupA_Dummy.PullCmpActvShoTermRampTi
    connect CalRegn01Inin01GroupA.PullCmpActvVehSpdScaTblX -> AAACalRegn01Inin01GroupA_Dummy.PullCmpActvVehSpdScaTblX
    connect CalRegn01Inin01GroupA.PullCmpActvVehSpdScaTblY -> AAACalRegn01Inin01GroupA_Dummy.PullCmpActvVehSpdScaTblY
    connect CalRegn01Inin01GroupC.CtrldVelRtnDesVelLpFilFrq -> AAACalRegn01Inin01GroupC_Dummy.CtrldVelRtnDesVelLpFilFrq
    connect CalRegn01Inin01GroupC.CtrldVelRtnHwTqLpFilFrq -> AAACalRegn01Inin01GroupC_Dummy.CtrldVelRtnHwTqLpFilFrq
    connect CalRegn01Inin01GroupC.CtrldVelRtnHwTqScaSelnSlewHiLim -> AAACalRegn01Inin01GroupC_Dummy.CtrldVelRtnHwTqScaSelnSlewHiLim
    connect CalRegn01Inin01GroupC.CtrldVelRtnHwTqScaSelnSlewLoLim -> AAACalRegn01Inin01GroupC_Dummy.CtrldVelRtnHwTqScaSelnSlewLoLim
    connect CalRegn01Inin01GroupC.CtrldVelRtnHwTqScaSelnTqThd -> AAACalRegn01Inin01GroupC_Dummy.CtrldVelRtnHwTqScaSelnTqThd
    connect CalRegn01Inin01GroupC.CtrldVelRtnHwTqScaSelnVelThd -> AAACalRegn01Inin01GroupC_Dummy.CtrldVelRtnHwTqScaSelnVelThd
    connect CalRegn01Inin01GroupC.CtrldVelRtnIntgrLimY -> AAACalRegn01Inin01GroupC_Dummy.CtrldVelRtnIntgrLimY
    connect CalRegn01Inin01GroupC.CtrldVelRtnOffsSlewThd -> AAACalRegn01Inin01GroupC_Dummy.CtrldVelRtnOffsSlewThd
    connect CalRegn01Inin01GroupC.CtrldVelRtnOffsThd -> AAACalRegn01Inin01GroupC_Dummy.CtrldVelRtnOffsThd
    connect CalRegn01Inin01GroupC.CtrldVelRtnScaLpFilFrq -> AAACalRegn01Inin01GroupC_Dummy.CtrldVelRtnScaLpFilFrq
    connect CalRegn01Inin01GroupC.FalbckAssiAssiX -> AAACalRegn01Inin01GroupC_Dummy.FalbckAssiAssiX
    connect CalRegn01Inin01GroupC.FalbckAssiAssiY -> AAACalRegn01Inin01GroupC_Dummy.FalbckAssiAssiY
    connect CalRegn01Inin01GroupC.FalbckAssiNotchFil -> AAACalRegn01Inin01GroupC_Dummy.FalbckAssiNotchFil
    connect CalRegn01Inin01GroupC.GlbLimrBndX -> AAACalRegn01Inin01GroupC_Dummy.GlbLimrBndX
    connect CalRegn01Inin01GroupC.GlbLimrBndY -> AAACalRegn01Inin01GroupC_Dummy.GlbLimrBndY
    connect CalRegn01Inin01GroupC.GlbLimrNotchFilStruct -> AAACalRegn01Inin01GroupC_Dummy.GlbLimrNotchFilStruct
    connect CalRegn01Inin01GroupC.GlbLimrVehSpdBilnrSeln -> AAACalRegn01Inin01GroupC_Dummy.GlbLimrVehSpdBilnrSeln
    connect CalRegn01Inin01GroupD.EotProtnDampgVehSpdTbl -> AAACalRegn01Inin01GroupD_Dummy.EotProtnDampgVehSpdTbl
    connect CalRegn01Inin01GroupD.EotProtnDeltaTqThd -> AAACalRegn01Inin01GroupD_Dummy.EotProtnDeltaTqThd
    connect CalRegn01Inin01GroupD.EotProtnEntrGainAuthyThd -> AAACalRegn01Inin01GroupD_Dummy.EotProtnEntrGainAuthyThd
    connect CalRegn01Inin01GroupD.EotProtnEntrGainVehSpdTbl -> AAACalRegn01Inin01GroupD_Dummy.EotProtnEntrGainVehSpdTbl
    connect CalRegn01Inin01GroupD.EotProtnEntrGainX -> AAACalRegn01Inin01GroupD_Dummy.EotProtnEntrGainX
    connect CalRegn01Inin01GroupD.EotProtnEntrGainY -> AAACalRegn01Inin01GroupD_Dummy.EotProtnEntrGainY
    connect CalRegn01Inin01GroupD.EotProtnEntrStLpFilFrq -> AAACalRegn01Inin01GroupD_Dummy.EotProtnEntrStLpFilFrq
    connect CalRegn01Inin01GroupD.EotProtnExitDampgY -> AAACalRegn01Inin01GroupD_Dummy.EotProtnExitDampgY
    connect CalRegn01Inin01GroupD.EotProtnExitStLpFilFrq -> AAACalRegn01Inin01GroupD_Dummy.EotProtnExitStLpFilFrq
    connect CalRegn01Inin01GroupD.EotProtnHwDegDampgX -> AAACalRegn01Inin01GroupD_Dummy.EotProtnHwDegDampgX
    connect CalRegn01Inin01GroupD.EotProtnHwTqLpFilFrq -> AAACalRegn01Inin01GroupD_Dummy.EotProtnHwTqLpFilFrq
    connect CalRegn01Inin01GroupD.EotProtnHwTqScaX -> AAACalRegn01Inin01GroupD_Dummy.EotProtnHwTqScaX
    connect CalRegn01Inin01GroupD.EotProtnLoAuthyEntrGainY -> AAACalRegn01Inin01GroupD_Dummy.EotProtnLoAuthyEntrGainY
    connect CalRegn01Inin01GroupD.EotProtnMotSpdIncptSca -> AAACalRegn01Inin01GroupD_Dummy.EotProtnMotSpdIncptSca
    connect CalRegn01Inin01GroupD.EotProtnMotSpdIncptX -> AAACalRegn01Inin01GroupD_Dummy.EotProtnMotSpdIncptX
    connect CalRegn01Inin01GroupD.EotProtnMotSpdIncptY -> AAACalRegn01Inin01GroupD_Dummy.EotProtnMotSpdIncptY
    connect CalRegn01Inin01GroupD.EotProtnMotVelGain -> AAACalRegn01Inin01GroupD_Dummy.EotProtnMotVelGain
    connect CalRegn01Inin01GroupD.EotProtnNormDampgY -> AAACalRegn01Inin01GroupD_Dummy.EotProtnNormDampgY
    connect CalRegn01Inin01GroupD.EotProtnPosnRampStep -> AAACalRegn01Inin01GroupD_Dummy.EotProtnPosnRampStep
    connect CalRegn01Inin01GroupD.EotProtnRackTrvlLimrAuthyThd -> AAACalRegn01Inin01GroupD_Dummy.EotProtnRackTrvlLimrAuthyThd
    connect CalRegn01Inin01GroupD.EotProtnRackTrvlLimrAuthyThdLimd -> AAACalRegn01Inin01GroupD_Dummy.EotProtnRackTrvlLimrAuthyThdLimd
    connect CalRegn01Inin01GroupD.EotProtnRackTrvlLimrRng -> AAACalRegn01Inin01GroupD_Dummy.EotProtnRackTrvlLimrRng
    connect CalRegn01Inin01GroupD.EotProtnRackTrvlLimrRngLimd -> AAACalRegn01Inin01GroupD_Dummy.EotProtnRackTrvlLimrRngLimd
    connect CalRegn01Inin01GroupD.EotProtnRackTrvlLimrVehSpdThd -> AAACalRegn01Inin01GroupD_Dummy.EotProtnRackTrvlLimrVehSpdThd
    connect CalRegn01Inin01GroupD.EotProtnRunEotVelImpctAndSoftEndStop -> AAACalRegn01Inin01GroupD_Dummy.EotProtnRunEotVelImpctAndSoftEndStop
    connect CalRegn01Inin01GroupD.InertiaCmpVelAssiBasdDampgCoeffX -> AAACalRegn01Inin01GroupD_Dummy.InertiaCmpVelAssiBasdDampgCoeffX
    connect CalRegn01Inin01GroupD.InertiaCmpVelAssiBasdDampgRollgWhlImbRejctnOnY -> AAACalRegn01Inin01GroupD_Dummy.InertiaCmpVelAssiBasdDampgRollgWhlImbRejctnOnY
    connect CalRegn01Inin01GroupD.InertiaCmpVelAssiBasdDampgRollgY -> AAACalRegn01Inin01GroupD_Dummy.InertiaCmpVelAssiBasdDampgRollgY
    connect CalRegn01Inin01GroupD.InertiaCmpVelAssiBasdDampgStatWhlImbRejctnOnY -> AAACalRegn01Inin01GroupD_Dummy.InertiaCmpVelAssiBasdDampgStatWhlImbRejctnOnY
    connect CalRegn01Inin01GroupD.InertiaCmpVelAssiBasdDampgStatY -> AAACalRegn01Inin01GroupD_Dummy.InertiaCmpVelAssiBasdDampgStatY
    connect CalRegn01Inin01GroupD.InertiaCmpVelCmdScaY -> AAACalRegn01Inin01GroupD_Dummy.InertiaCmpVelCmdScaY
    connect CalRegn01Inin01GroupD.InertiaCmpVelDampgDecelGain -> AAACalRegn01Inin01GroupD_Dummy.InertiaCmpVelDampgDecelGain
    connect CalRegn01Inin01GroupD.InertiaCmpVelDampgDecelGainFallSlew -> AAACalRegn01Inin01GroupD_Dummy.InertiaCmpVelDampgDecelGainFallSlew
    connect CalRegn01Inin01GroupD.InertiaCmpVelDampgDecelGainRisngSlewX -> AAACalRegn01Inin01GroupD_Dummy.InertiaCmpVelDampgDecelGainRisngSlewX
    connect CalRegn01Inin01GroupD.InertiaCmpVelDampgDecelGainRisngSlewY -> AAACalRegn01Inin01GroupD_Dummy.InertiaCmpVelDampgDecelGainRisngSlewY
    connect CalRegn01Inin01GroupD.InertiaCmpVelDampgFilFrq -> AAACalRegn01Inin01GroupD_Dummy.InertiaCmpVelDampgFilFrq
    connect CalRegn01Inin01GroupD.InertiaCmpVelDampgFilFrqWhlImbRejctnOn -> AAACalRegn01Inin01GroupD_Dummy.InertiaCmpVelDampgFilFrqWhlImbRejctnOn
    connect CalRegn01Inin01GroupD.InertiaCmpVelDampgGainOffThd -> AAACalRegn01Inin01GroupD_Dummy.InertiaCmpVelDampgGainOffThd
    connect CalRegn01Inin01GroupD.InertiaCmpVelDampgGainOnThd -> AAACalRegn01Inin01GroupD_Dummy.InertiaCmpVelDampgGainOnThd
    connect CalRegn01Inin01GroupD.InertiaCmpVelDampgSpdBlndY -> AAACalRegn01Inin01GroupD_Dummy.InertiaCmpVelDampgSpdBlndY
    connect CalRegn01Inin01GroupD.InertiaCmpVelDampgWhlImbRejctnBlndX -> AAACalRegn01Inin01GroupD_Dummy.InertiaCmpVelDampgWhlImbRejctnBlndX
    connect CalRegn01Inin01GroupD.InertiaCmpVelDampgWhlImbRejctnBlndY -> AAACalRegn01Inin01GroupD_Dummy.InertiaCmpVelDampgWhlImbRejctnBlndY
    connect CalRegn01Inin01GroupD.InertiaCmpVelDecelGainEnaCal -> AAACalRegn01Inin01GroupD_Dummy.InertiaCmpVelDecelGainEnaCal
    connect CalRegn01Inin01GroupD.InertiaCmpVelModWhlImbRejctnBlndX -> AAACalRegn01Inin01GroupD_Dummy.InertiaCmpVelModWhlImbRejctnBlndX
    connect CalRegn01Inin01GroupD.InertiaCmpVelModWhlImbRejctnBlndY -> AAACalRegn01Inin01GroupD_Dummy.InertiaCmpVelModWhlImbRejctnBlndY
    connect CalRegn01Inin01GroupD.InertiaCmpVelMotInertia -> AAACalRegn01Inin01GroupD_Dummy.InertiaCmpVelMotInertia
    connect CalRegn01Inin01GroupD.InertiaCmpVelMotVelBasdOutpScagX -> AAACalRegn01Inin01GroupD_Dummy.InertiaCmpVelMotVelBasdOutpScagX
    connect CalRegn01Inin01GroupD.InertiaCmpVelMotVelBasdOutpScagY -> AAACalRegn01Inin01GroupD_Dummy.InertiaCmpVelMotVelBasdOutpScagY
    connect CalRegn01Inin01GroupD.InertiaCmpVelNotchBlndY -> AAACalRegn01Inin01GroupD_Dummy.InertiaCmpVelNotchBlndY
    connect CalRegn01Inin01GroupD.InertiaCmpVelNotchFilStruct -> AAACalRegn01Inin01GroupD_Dummy.InertiaCmpVelNotchFilStruct
    connect CalRegn01Inin01GroupD.InertiaCmpVelTqSnsrVelFilFrq -> AAACalRegn01Inin01GroupD_Dummy.InertiaCmpVelTqSnsrVelFilFrq
    connect CalRegn01Inin01GroupD.InertiaCmpVelTqSnsrVelSca -> AAACalRegn01Inin01GroupD_Dummy.InertiaCmpVelTqSnsrVelSca
    connect CalRegn01Inin02.BmwHwAgArbnAndEotPosnKineIntegrityDiagcMaxRackLim -> AAACalRegn01Inin02_Dummy.BmwHwAgArbnAndEotPosnKineIntegrityDiagcMaxRackLim
    connect CalRegn01Inin02.EffortScaBlndX -> AAACalRegn01Inin02_Dummy.EffortScaBlndX
    connect CalRegn01Inin02.EffortScaBlndY -> AAACalRegn01Inin02_Dummy.EffortScaBlndY
    connect CalRegn01Inin02.EffortScaRackFThd -> AAACalRegn01Inin02_Dummy.EffortScaRackFThd
    connect CalRegn01Inin02.PosnTrakgServoArbnFltMtgtnLpFilCutOffFrq -> AAACalRegn01Inin02_Dummy.PosnTrakgServoArbnFltMtgtnLpFilCutOffFrq
    connect CalRegn01Inin02.PullCmpActvHwTqFilFrqLrngEna -> AAACalRegn01Inin02_Dummy.PullCmpActvHwTqFilFrqLrngEna
    connect CalRegn01Inin02.PullCmpActvYawRateFilFrq -> AAACalRegn01Inin02_Dummy.PullCmpActvYawRateFilFrq
    connect CalRegn01Inin02.SysFricLrngAvrgFricFrq -> AAACalRegn01Inin02_Dummy.SysFricLrngAvrgFricFrq
    connect CalRegn01Inin02.SysFricLrngBasLineEolFric -> AAACalRegn01Inin02_Dummy.SysFricLrngBasLineEolFric
    connect CalRegn01Inin02.SysFricLrngBasLineFric -> AAACalRegn01Inin02_Dummy.SysFricLrngBasLineFric
    connect CalRegn01Inin02.SysFricLrngBasLineHys -> AAACalRegn01Inin02_Dummy.SysFricLrngBasLineHys
    connect CalRegn01Inin02.SysFricLrngBasLineRngCntr -> AAACalRegn01Inin02_Dummy.SysFricLrngBasLineRngCntr
    connect CalRegn01Inin02.SysFricLrngDataPrepLpFilFrq -> AAACalRegn01Inin02_Dummy.SysFricLrngDataPrepLpFilFrq
    connect CalRegn01Inin02.SysFricLrngDebStep -> AAACalRegn01Inin02_Dummy.SysFricLrngDebStep
    connect CalRegn01Inin02.SysFricLrngEolFricDifHiLim -> AAACalRegn01Inin02_Dummy.SysFricLrngEolFricDifHiLim
    connect CalRegn01Inin02.SysFricLrngEolFricDifLoLim -> AAACalRegn01Inin02_Dummy.SysFricLrngEolFricDifLoLim
    connect CalRegn01Inin02.SysFricLrngEolFricDifScagFac -> AAACalRegn01Inin02_Dummy.SysFricLrngEolFricDifScagFac
    connect CalRegn01Inin02.SysFricLrngFricChgWght -> AAACalRegn01Inin02_Dummy.SysFricLrngFricChgWght
    connect CalRegn01Inin02.SysFricLrngFricDiagcThd -> AAACalRegn01Inin02_Dummy.SysFricLrngFricDiagcThd
    connect CalRegn01Inin02.SysFricLrngFricHysHwAgPt -> AAACalRegn01Inin02_Dummy.SysFricLrngFricHysHwAgPt
    connect CalRegn01Inin02.SysFricLrngFricOffs -> AAACalRegn01Inin02_Dummy.SysFricLrngFricOffs
    connect CalRegn01Inin02.SysFricLrngFricOffsHiLim -> AAACalRegn01Inin02_Dummy.SysFricLrngFricOffsHiLim
    connect CalRegn01Inin02.SysFricLrngFricOffsLoLim -> AAACalRegn01Inin02_Dummy.SysFricLrngFricOffsLoLim
    connect CalRegn01Inin02.SysFricLrngFricOffsLpFilFrq -> AAACalRegn01Inin02_Dummy.SysFricLrngFricOffsLpFilFrq
    connect CalRegn01Inin02.SysFricLrngGain -> AAACalRegn01Inin02_Dummy.SysFricLrngGain
    connect CalRegn01Inin02.SysFricLrngHiFricDebStep -> AAACalRegn01Inin02_Dummy.SysFricLrngHiFricDebStep
    connect CalRegn01Inin02.SysFricLrngHiFricDiagcThd -> AAACalRegn01Inin02_Dummy.SysFricLrngHiFricDiagcThd
    connect CalRegn01Inin02.SysFricLrngHwPosnAuthyThd -> AAACalRegn01Inin02_Dummy.SysFricLrngHwPosnAuthyThd
    connect CalRegn01Inin02.SysFricLrngHwVelConstrLim -> AAACalRegn01Inin02_Dummy.SysFricLrngHwVelConstrLim
    connect CalRegn01Inin02.SysFricLrngHwVelHiLim -> AAACalRegn01Inin02_Dummy.SysFricLrngHwVelHiLim
    connect CalRegn01Inin02.SysFricLrngHwVelLoLim -> AAACalRegn01Inin02_Dummy.SysFricLrngHwVelLoLim
    connect CalRegn01Inin02.SysFricLrngIgnCycFricChgLim -> AAACalRegn01Inin02_Dummy.SysFricLrngIgnCycFricChgLim
    connect CalRegn01Inin02.SysFricLrngIgnCycFricOffs -> AAACalRegn01Inin02_Dummy.SysFricLrngIgnCycFricOffs
    connect CalRegn01Inin02.SysFricLrngIvsTrsmRatX -> AAACalRegn01Inin02_Dummy.SysFricLrngIvsTrsmRatX
    connect CalRegn01Inin02.SysFricLrngIvsTrsmRatY -> AAACalRegn01Inin02_Dummy.SysFricLrngIvsTrsmRatY
    connect CalRegn01Inin02.SysFricLrngLatAHiLim -> AAACalRegn01Inin02_Dummy.SysFricLrngLatAHiLim
    connect CalRegn01Inin02.SysFricLrngLatALoLim -> AAACalRegn01Inin02_Dummy.SysFricLrngLatALoLim
    connect CalRegn01Inin02.SysFricLrngMaskVehSpd -> AAACalRegn01Inin02_Dummy.SysFricLrngMaskVehSpd
    connect CalRegn01Inin02.SysFricLrngRngCntrThd -> AAACalRegn01Inin02_Dummy.SysFricLrngRngCntrThd
    connect CalRegn01Inin02.SysFricLrngThd -> AAACalRegn01Inin02_Dummy.SysFricLrngThd
    connect CalRegn01Inin02.SysFricLrngTHiLim -> AAACalRegn01Inin02_Dummy.SysFricLrngTHiLim
    connect CalRegn01Inin02.SysFricLrngTLoLim -> AAACalRegn01Inin02_Dummy.SysFricLrngTLoLim
    connect CalRegn01Inin02.SysFricLrngVehSpd -> AAACalRegn01Inin02_Dummy.SysFricLrngVehSpd
    connect CalRegn01Inin02.SysGlbPrmSysKineRat -> AAACalRegn01Inin02_Dummy.SysGlbPrmSysKineRat
    connect CalRegn01Inin02.SysGlbPrmVehSpdBilnrSeln -> AAACalRegn01Inin02_Dummy.SysGlbPrmVehSpdBilnrSeln
    connect CalRegn01Inin02.SysKineAndEffMotAgToRackPosRatScaY -> AAACalRegn01Inin02_Dummy.SysKineAndEffMotAgToRackPosRatScaY
    connect CalRegn01Inin02.SysKineAndEffPinionAgToRackPosRatScaY -> AAACalRegn01Inin02_Dummy.SysKineAndEffPinionAgToRackPosRatScaY
    connect CalRegn01Inin02.SysKineAndEffPinionToRackEffScaY -> AAACalRegn01Inin02_Dummy.SysKineAndEffPinionToRackEffScaY
    connect CalRegn01Inin02.SysKineAndEffRoadWhlFromRackPosScaY -> AAACalRegn01Inin02_Dummy.SysKineAndEffRoadWhlFromRackPosScaY
    connect CalRegn01Inin02.SysKineAndEffSteerArmLenFromRackPosScaY -> AAACalRegn01Inin02_Dummy.SysKineAndEffSteerArmLenFromRackPosScaY
    connect CalRegn01Inin02.TunSelnAuthyVehSpdX -> AAACalRegn01Inin02_Dummy.TunSelnAuthyVehSpdX
    connect CalRegn01Inin02GroupA.BmwHwAgArbnAndEotPosnEotCcwMax -> AAACalRegn01Inin02GroupA_Dummy.BmwHwAgArbnAndEotPosnEotCcwMax
    connect CalRegn01Inin02GroupA.BmwHwAgArbnAndEotPosnEotCcwMin -> AAACalRegn01Inin02GroupA_Dummy.BmwHwAgArbnAndEotPosnEotCcwMin
    connect CalRegn01Inin02GroupA.BmwHwAgArbnAndEotPosnEotCwMax -> AAACalRegn01Inin02GroupA_Dummy.BmwHwAgArbnAndEotPosnEotCwMax
    connect CalRegn01Inin02GroupA.BmwHwAgArbnAndEotPosnEotCwMin -> AAACalRegn01Inin02GroupA_Dummy.BmwHwAgArbnAndEotPosnEotCwMin
    connect CalRegn01Inin02GroupA.BmwPwrPrkgDampgDiScadDampg -> AAACalRegn01Inin02GroupA_Dummy.BmwPwrPrkgDampgDiScadDampg
    connect CalRegn01Inin02GroupA.BmwPwrPrkgDampgMaxRate -> AAACalRegn01Inin02GroupA_Dummy.BmwPwrPrkgDampgMaxRate
    connect CalRegn01Inin02GroupA.EpsStEstimnMtrxA -> AAACalRegn01Inin02GroupA_Dummy.EpsStEstimnMtrxA
    connect CalRegn01Inin02GroupA.EpsStEstimnMtrxB -> AAACalRegn01Inin02GroupA_Dummy.EpsStEstimnMtrxB
    connect CalRegn01Inin02GroupA.EpsStEstimnMtrxC -> AAACalRegn01Inin02GroupA_Dummy.EpsStEstimnMtrxC
    connect CalRegn01Inin02GroupA.EpsStEstimnMtrxD -> AAACalRegn01Inin02GroupA_Dummy.EpsStEstimnMtrxD
    connect CalRegn01Inin02GroupA.HwTqTrakgCtrlFbGain{1..5} -> AAACalRegn01Inin02GroupA_Dummy.HwTqTrakgCtrlFbGain{1..5}
    connect CalRegn01Inin02GroupA.HwTqTrakgCtrlFfGainScaY -> AAACalRegn01Inin02GroupA_Dummy.HwTqTrakgCtrlFfGainScaY
    connect CalRegn01Inin02GroupA.HwTqTrakgCtrlVehSpdScaX -> AAACalRegn01Inin02GroupA_Dummy.HwTqTrakgCtrlVehSpdScaX
    connect CalRegn01Inin02GroupA.PosnTrakgServoEnaBlndFacTblX -> AAACalRegn01Inin02GroupA_Dummy.PosnTrakgServoEnaBlndFacTblX
    connect CalRegn01Inin02GroupA.PosnTrakgServoEnaBlndFacTblY -> AAACalRegn01Inin02GroupA_Dummy.PosnTrakgServoEnaBlndFacTblY
    connect CalRegn01Inin02GroupA.PosnTrakgServoGainArbnFltMtgtn -> AAACalRegn01Inin02GroupA_Dummy.PosnTrakgServoGainArbnFltMtgtn
    connect CalRegn01Inin02GroupA.PullCmpActvCmpLrnTiDecShoTerm -> AAACalRegn01Inin02GroupA_Dummy.PullCmpActvCmpLrnTiDecShoTerm
    connect CalRegn01Inin02GroupA.PullCmpActvCmpLrnTiIncShoTerm -> AAACalRegn01Inin02GroupA_Dummy.PullCmpActvCmpLrnTiIncShoTerm
    connect CalRegn01Inin02GroupA.PullCmpActvCmpLrnTiLongTerm -> AAACalRegn01Inin02GroupA_Dummy.PullCmpActvCmpLrnTiLongTerm
    connect CalRegn01Inin02GroupA.PullCmpActvCmpShoTermRstHwAgThd -> AAACalRegn01Inin02GroupA_Dummy.PullCmpActvCmpShoTermRstHwAgThd
    connect CalRegn01Inin02GroupA.PullCmpActvCmpShoTermRstHwTqThd -> AAACalRegn01Inin02GroupA_Dummy.PullCmpActvCmpShoTermRstHwTqThd
    connect CalRegn01Inin02GroupA.PullCmpActvCmpShoTermRstLatAThd -> AAACalRegn01Inin02GroupA_Dummy.PullCmpActvCmpShoTermRstLatAThd
    connect CalRegn01Inin02GroupA.PullCmpActvCmpShoTermRstYawRateThd -> AAACalRegn01Inin02GroupA_Dummy.PullCmpActvCmpShoTermRstYawRateThd
    connect CalRegn01Inin02GroupA.PullCmpActvEna -> AAACalRegn01Inin02GroupA_Dummy.PullCmpActvEna
    connect CalRegn01Inin02GroupA.PullCmpActvHwTqFilFrqLongTerm -> AAACalRegn01Inin02GroupA_Dummy.PullCmpActvHwTqFilFrqLongTerm
    connect CalRegn01Inin02GroupA.PullCmpActvHwTqFilFrqShoTerm -> AAACalRegn01Inin02GroupA_Dummy.PullCmpActvHwTqFilFrqShoTerm
    connect CalRegn01Inin02GroupA.PullCmpActvLongTermLim -> AAACalRegn01Inin02GroupA_Dummy.PullCmpActvLongTermLim
    connect CalRegn01Inin02GroupA.PullCmpActvLrngEnaAgConfMinMgn -> AAACalRegn01Inin02GroupA_Dummy.PullCmpActvLrngEnaAgConfMinMgn
    connect CalRegn01Inin02GroupA.PullCmpActvLrngEnaHwAgMaxMgn -> AAACalRegn01Inin02GroupA_Dummy.PullCmpActvLrngEnaHwAgMaxMgn
    connect CalRegn01Inin02GroupA.PullCmpActvLrngEnaHwTqMaxMgn -> AAACalRegn01Inin02GroupA_Dummy.PullCmpActvLrngEnaHwTqMaxMgn
    connect CalRegn01Inin02GroupA.PullCmpActvLrngEnaHwVelMaxMgn -> AAACalRegn01Inin02GroupA_Dummy.PullCmpActvLrngEnaHwVelMaxMgn
    connect CalRegn01Inin02GroupA.PullCmpActvLrngEnaLatAMaxMgn -> AAACalRegn01Inin02GroupA_Dummy.PullCmpActvLrngEnaLatAMaxMgn
    connect CalRegn01Inin02GroupA.PullCmpActvLrngEnaTiThd -> AAACalRegn01Inin02GroupA_Dummy.PullCmpActvLrngEnaTiThd
    connect CalRegn01Inin02GroupA.PullCmpActvLrngEnaVehSpdMaxMgn -> AAACalRegn01Inin02GroupA_Dummy.PullCmpActvLrngEnaVehSpdMaxMgn
    connect CalRegn01Inin02GroupA.PullCmpActvLrngEnaVehSpdMinMgn -> AAACalRegn01Inin02GroupA_Dummy.PullCmpActvLrngEnaVehSpdMinMgn
    connect CalRegn01Inin02GroupA.PullCmpActvLrngEnaVehSpdRateMaxMgn -> AAACalRegn01Inin02GroupA_Dummy.PullCmpActvLrngEnaVehSpdRateMaxMgn
    connect CalRegn01Inin02GroupA.PullCmpActvLrngEnaYawRateMaxMgn -> AAACalRegn01Inin02GroupA_Dummy.PullCmpActvLrngEnaYawRateMaxMgn
    connect CalRegn01Inin02GroupA.PullCmpActvOpstSignTiShoTerm -> AAACalRegn01Inin02GroupA_Dummy.PullCmpActvOpstSignTiShoTerm
    connect CalRegn01Inin02GroupA.PullCmpActvOutpMaxRate -> AAACalRegn01Inin02GroupA_Dummy.PullCmpActvOutpMaxRate
    connect CalRegn01Inin02GroupA.PullCmpActvPullCmpShoTermLim -> AAACalRegn01Inin02GroupA_Dummy.PullCmpActvPullCmpShoTermLim
    connect CalRegn01Inin02GroupA.PullCmpActvPullCmpTotLim -> AAACalRegn01Inin02GroupA_Dummy.PullCmpActvPullCmpTotLim
    connect CalRegn01Inin02GroupA.PullCmpActvPullErrLimLongTerm -> AAACalRegn01Inin02GroupA_Dummy.PullCmpActvPullErrLimLongTerm
    connect CalRegn01Inin02GroupA.PullCmpActvPullErrMgnThd -> AAACalRegn01Inin02GroupA_Dummy.PullCmpActvPullErrMgnThd
    connect CalRegn01Inin02GroupA.PullCmpActvPullErrShoTermLim -> AAACalRegn01Inin02GroupA_Dummy.PullCmpActvPullErrShoTermLim
    connect CalRegn01Inin02GroupA.PullCmpActvShoTermRampTi -> AAACalRegn01Inin02GroupA_Dummy.PullCmpActvShoTermRampTi
    connect CalRegn01Inin02GroupA.PullCmpActvVehSpdScaTblX -> AAACalRegn01Inin02GroupA_Dummy.PullCmpActvVehSpdScaTblX
    connect CalRegn01Inin02GroupA.PullCmpActvVehSpdScaTblY -> AAACalRegn01Inin02GroupA_Dummy.PullCmpActvVehSpdScaTblY
    connect CalRegn01Inin02GroupC.CtrldVelRtnDesVelLpFilFrq -> AAACalRegn01Inin02GroupC_Dummy.CtrldVelRtnDesVelLpFilFrq
    connect CalRegn01Inin02GroupC.CtrldVelRtnHwTqLpFilFrq -> AAACalRegn01Inin02GroupC_Dummy.CtrldVelRtnHwTqLpFilFrq
    connect CalRegn01Inin02GroupC.CtrldVelRtnHwTqScaSelnSlewHiLim -> AAACalRegn01Inin02GroupC_Dummy.CtrldVelRtnHwTqScaSelnSlewHiLim
    connect CalRegn01Inin02GroupC.CtrldVelRtnHwTqScaSelnSlewLoLim -> AAACalRegn01Inin02GroupC_Dummy.CtrldVelRtnHwTqScaSelnSlewLoLim
    connect CalRegn01Inin02GroupC.CtrldVelRtnHwTqScaSelnTqThd -> AAACalRegn01Inin02GroupC_Dummy.CtrldVelRtnHwTqScaSelnTqThd
    connect CalRegn01Inin02GroupC.CtrldVelRtnHwTqScaSelnVelThd -> AAACalRegn01Inin02GroupC_Dummy.CtrldVelRtnHwTqScaSelnVelThd
    connect CalRegn01Inin02GroupC.CtrldVelRtnIntgrLimY -> AAACalRegn01Inin02GroupC_Dummy.CtrldVelRtnIntgrLimY
    connect CalRegn01Inin02GroupC.CtrldVelRtnOffsSlewThd -> AAACalRegn01Inin02GroupC_Dummy.CtrldVelRtnOffsSlewThd
    connect CalRegn01Inin02GroupC.CtrldVelRtnOffsThd -> AAACalRegn01Inin02GroupC_Dummy.CtrldVelRtnOffsThd
    connect CalRegn01Inin02GroupC.CtrldVelRtnScaLpFilFrq -> AAACalRegn01Inin02GroupC_Dummy.CtrldVelRtnScaLpFilFrq
    connect CalRegn01Inin02GroupC.FalbckAssiAssiX -> AAACalRegn01Inin02GroupC_Dummy.FalbckAssiAssiX
    connect CalRegn01Inin02GroupC.FalbckAssiAssiY -> AAACalRegn01Inin02GroupC_Dummy.FalbckAssiAssiY
    connect CalRegn01Inin02GroupC.FalbckAssiNotchFil -> AAACalRegn01Inin02GroupC_Dummy.FalbckAssiNotchFil
    connect CalRegn01Inin02GroupC.GlbLimrBndX -> AAACalRegn01Inin02GroupC_Dummy.GlbLimrBndX
    connect CalRegn01Inin02GroupC.GlbLimrBndY -> AAACalRegn01Inin02GroupC_Dummy.GlbLimrBndY
    connect CalRegn01Inin02GroupC.GlbLimrNotchFilStruct -> AAACalRegn01Inin02GroupC_Dummy.GlbLimrNotchFilStruct
    connect CalRegn01Inin02GroupC.GlbLimrVehSpdBilnrSeln -> AAACalRegn01Inin02GroupC_Dummy.GlbLimrVehSpdBilnrSeln
    connect CalRegn01Inin02GroupD.EotProtnDampgVehSpdTbl -> AAACalRegn01Inin02GroupD_Dummy.EotProtnDampgVehSpdTbl
    connect CalRegn01Inin02GroupD.EotProtnDeltaTqThd -> AAACalRegn01Inin02GroupD_Dummy.EotProtnDeltaTqThd
    connect CalRegn01Inin02GroupD.EotProtnEntrGainAuthyThd -> AAACalRegn01Inin02GroupD_Dummy.EotProtnEntrGainAuthyThd
    connect CalRegn01Inin02GroupD.EotProtnEntrGainVehSpdTbl -> AAACalRegn01Inin02GroupD_Dummy.EotProtnEntrGainVehSpdTbl
    connect CalRegn01Inin02GroupD.EotProtnEntrGainX -> AAACalRegn01Inin02GroupD_Dummy.EotProtnEntrGainX
    connect CalRegn01Inin02GroupD.EotProtnEntrGainY -> AAACalRegn01Inin02GroupD_Dummy.EotProtnEntrGainY
    connect CalRegn01Inin02GroupD.EotProtnEntrStLpFilFrq -> AAACalRegn01Inin02GroupD_Dummy.EotProtnEntrStLpFilFrq
    connect CalRegn01Inin02GroupD.EotProtnExitDampgY -> AAACalRegn01Inin02GroupD_Dummy.EotProtnExitDampgY
    connect CalRegn01Inin02GroupD.EotProtnExitStLpFilFrq -> AAACalRegn01Inin02GroupD_Dummy.EotProtnExitStLpFilFrq
    connect CalRegn01Inin02GroupD.EotProtnHwDegDampgX -> AAACalRegn01Inin02GroupD_Dummy.EotProtnHwDegDampgX
    connect CalRegn01Inin02GroupD.EotProtnHwTqLpFilFrq -> AAACalRegn01Inin02GroupD_Dummy.EotProtnHwTqLpFilFrq
    connect CalRegn01Inin02GroupD.EotProtnHwTqScaX -> AAACalRegn01Inin02GroupD_Dummy.EotProtnHwTqScaX
    connect CalRegn01Inin02GroupD.EotProtnLoAuthyEntrGainY -> AAACalRegn01Inin02GroupD_Dummy.EotProtnLoAuthyEntrGainY
    connect CalRegn01Inin02GroupD.EotProtnMotSpdIncptSca -> AAACalRegn01Inin02GroupD_Dummy.EotProtnMotSpdIncptSca
    connect CalRegn01Inin02GroupD.EotProtnMotSpdIncptX -> AAACalRegn01Inin02GroupD_Dummy.EotProtnMotSpdIncptX
    connect CalRegn01Inin02GroupD.EotProtnMotSpdIncptY -> AAACalRegn01Inin02GroupD_Dummy.EotProtnMotSpdIncptY
    connect CalRegn01Inin02GroupD.EotProtnMotVelGain -> AAACalRegn01Inin02GroupD_Dummy.EotProtnMotVelGain
    connect CalRegn01Inin02GroupD.EotProtnNormDampgY -> AAACalRegn01Inin02GroupD_Dummy.EotProtnNormDampgY
    connect CalRegn01Inin02GroupD.EotProtnPosnRampStep -> AAACalRegn01Inin02GroupD_Dummy.EotProtnPosnRampStep
    connect CalRegn01Inin02GroupD.EotProtnRackTrvlLimrAuthyThd -> AAACalRegn01Inin02GroupD_Dummy.EotProtnRackTrvlLimrAuthyThd
    connect CalRegn01Inin02GroupD.EotProtnRackTrvlLimrAuthyThdLimd -> AAACalRegn01Inin02GroupD_Dummy.EotProtnRackTrvlLimrAuthyThdLimd
    connect CalRegn01Inin02GroupD.EotProtnRackTrvlLimrRng -> AAACalRegn01Inin02GroupD_Dummy.EotProtnRackTrvlLimrRng
    connect CalRegn01Inin02GroupD.EotProtnRackTrvlLimrRngLimd -> AAACalRegn01Inin02GroupD_Dummy.EotProtnRackTrvlLimrRngLimd
    connect CalRegn01Inin02GroupD.EotProtnRackTrvlLimrVehSpdThd -> AAACalRegn01Inin02GroupD_Dummy.EotProtnRackTrvlLimrVehSpdThd
    connect CalRegn01Inin02GroupD.EotProtnRunEotVelImpctAndSoftEndStop -> AAACalRegn01Inin02GroupD_Dummy.EotProtnRunEotVelImpctAndSoftEndStop
    connect CalRegn01Inin02GroupD.InertiaCmpVelAssiBasdDampgCoeffX -> AAACalRegn01Inin02GroupD_Dummy.InertiaCmpVelAssiBasdDampgCoeffX
    connect CalRegn01Inin02GroupD.InertiaCmpVelAssiBasdDampgRollgWhlImbRejctnOnY -> AAACalRegn01Inin02GroupD_Dummy.InertiaCmpVelAssiBasdDampgRollgWhlImbRejctnOnY
    connect CalRegn01Inin02GroupD.InertiaCmpVelAssiBasdDampgRollgY -> AAACalRegn01Inin02GroupD_Dummy.InertiaCmpVelAssiBasdDampgRollgY
    connect CalRegn01Inin02GroupD.InertiaCmpVelAssiBasdDampgStatWhlImbRejctnOnY -> AAACalRegn01Inin02GroupD_Dummy.InertiaCmpVelAssiBasdDampgStatWhlImbRejctnOnY
    connect CalRegn01Inin02GroupD.InertiaCmpVelAssiBasdDampgStatY -> AAACalRegn01Inin02GroupD_Dummy.InertiaCmpVelAssiBasdDampgStatY
    connect CalRegn01Inin02GroupD.InertiaCmpVelCmdScaY -> AAACalRegn01Inin02GroupD_Dummy.InertiaCmpVelCmdScaY
    connect CalRegn01Inin02GroupD.InertiaCmpVelDampgDecelGain -> AAACalRegn01Inin02GroupD_Dummy.InertiaCmpVelDampgDecelGain
    connect CalRegn01Inin02GroupD.InertiaCmpVelDampgDecelGainFallSlew -> AAACalRegn01Inin02GroupD_Dummy.InertiaCmpVelDampgDecelGainFallSlew
    connect CalRegn01Inin02GroupD.InertiaCmpVelDampgDecelGainRisngSlewX -> AAACalRegn01Inin02GroupD_Dummy.InertiaCmpVelDampgDecelGainRisngSlewX
    connect CalRegn01Inin02GroupD.InertiaCmpVelDampgDecelGainRisngSlewY -> AAACalRegn01Inin02GroupD_Dummy.InertiaCmpVelDampgDecelGainRisngSlewY
    connect CalRegn01Inin02GroupD.InertiaCmpVelDampgFilFrq -> AAACalRegn01Inin02GroupD_Dummy.InertiaCmpVelDampgFilFrq
    connect CalRegn01Inin02GroupD.InertiaCmpVelDampgFilFrqWhlImbRejctnOn -> AAACalRegn01Inin02GroupD_Dummy.InertiaCmpVelDampgFilFrqWhlImbRejctnOn
    connect CalRegn01Inin02GroupD.InertiaCmpVelDampgGainOffThd -> AAACalRegn01Inin02GroupD_Dummy.InertiaCmpVelDampgGainOffThd
    connect CalRegn01Inin02GroupD.InertiaCmpVelDampgGainOnThd -> AAACalRegn01Inin02GroupD_Dummy.InertiaCmpVelDampgGainOnThd
    connect CalRegn01Inin02GroupD.InertiaCmpVelDampgSpdBlndY -> AAACalRegn01Inin02GroupD_Dummy.InertiaCmpVelDampgSpdBlndY
    connect CalRegn01Inin02GroupD.InertiaCmpVelDampgWhlImbRejctnBlndX -> AAACalRegn01Inin02GroupD_Dummy.InertiaCmpVelDampgWhlImbRejctnBlndX
    connect CalRegn01Inin02GroupD.InertiaCmpVelDampgWhlImbRejctnBlndY -> AAACalRegn01Inin02GroupD_Dummy.InertiaCmpVelDampgWhlImbRejctnBlndY
    connect CalRegn01Inin02GroupD.InertiaCmpVelDecelGainEnaCal -> AAACalRegn01Inin02GroupD_Dummy.InertiaCmpVelDecelGainEnaCal
    connect CalRegn01Inin02GroupD.InertiaCmpVelModWhlImbRejctnBlndX -> AAACalRegn01Inin02GroupD_Dummy.InertiaCmpVelModWhlImbRejctnBlndX
    connect CalRegn01Inin02GroupD.InertiaCmpVelModWhlImbRejctnBlndY -> AAACalRegn01Inin02GroupD_Dummy.InertiaCmpVelModWhlImbRejctnBlndY
    connect CalRegn01Inin02GroupD.InertiaCmpVelMotInertia -> AAACalRegn01Inin02GroupD_Dummy.InertiaCmpVelMotInertia
    connect CalRegn01Inin02GroupD.InertiaCmpVelMotVelBasdOutpScagX -> AAACalRegn01Inin02GroupD_Dummy.InertiaCmpVelMotVelBasdOutpScagX
    connect CalRegn01Inin02GroupD.InertiaCmpVelMotVelBasdOutpScagY -> AAACalRegn01Inin02GroupD_Dummy.InertiaCmpVelMotVelBasdOutpScagY
    connect CalRegn01Inin02GroupD.InertiaCmpVelNotchBlndY -> AAACalRegn01Inin02GroupD_Dummy.InertiaCmpVelNotchBlndY
    connect CalRegn01Inin02GroupD.InertiaCmpVelNotchFilStruct -> AAACalRegn01Inin02GroupD_Dummy.InertiaCmpVelNotchFilStruct
    connect CalRegn01Inin02GroupD.InertiaCmpVelTqSnsrVelFilFrq -> AAACalRegn01Inin02GroupD_Dummy.InertiaCmpVelTqSnsrVelFilFrq
    connect CalRegn01Inin02GroupD.InertiaCmpVelTqSnsrVelSca -> AAACalRegn01Inin02GroupD_Dummy.InertiaCmpVelTqSnsrVelSca
    connect CalRegn01Inin03.BmwHwAgArbnAndEotPosnKineIntegrityDiagcMaxRackLim -> AAACalRegn01Inin03_Dummy.BmwHwAgArbnAndEotPosnKineIntegrityDiagcMaxRackLim
    connect CalRegn01Inin03.EffortScaBlndX -> AAACalRegn01Inin03_Dummy.EffortScaBlndX
    connect CalRegn01Inin03.EffortScaBlndY -> AAACalRegn01Inin03_Dummy.EffortScaBlndY
    connect CalRegn01Inin03.EffortScaRackFThd -> AAACalRegn01Inin03_Dummy.EffortScaRackFThd
    connect CalRegn01Inin03.PosnTrakgServoArbnFltMtgtnLpFilCutOffFrq -> AAACalRegn01Inin03_Dummy.PosnTrakgServoArbnFltMtgtnLpFilCutOffFrq
    connect CalRegn01Inin03.PullCmpActvHwTqFilFrqLrngEna -> AAACalRegn01Inin03_Dummy.PullCmpActvHwTqFilFrqLrngEna
    connect CalRegn01Inin03.PullCmpActvYawRateFilFrq -> AAACalRegn01Inin03_Dummy.PullCmpActvYawRateFilFrq
    connect CalRegn01Inin03.SysFricLrngAvrgFricFrq -> AAACalRegn01Inin03_Dummy.SysFricLrngAvrgFricFrq
    connect CalRegn01Inin03.SysFricLrngBasLineEolFric -> AAACalRegn01Inin03_Dummy.SysFricLrngBasLineEolFric
    connect CalRegn01Inin03.SysFricLrngBasLineFric -> AAACalRegn01Inin03_Dummy.SysFricLrngBasLineFric
    connect CalRegn01Inin03.SysFricLrngBasLineHys -> AAACalRegn01Inin03_Dummy.SysFricLrngBasLineHys
    connect CalRegn01Inin03.SysFricLrngBasLineRngCntr -> AAACalRegn01Inin03_Dummy.SysFricLrngBasLineRngCntr
    connect CalRegn01Inin03.SysFricLrngDataPrepLpFilFrq -> AAACalRegn01Inin03_Dummy.SysFricLrngDataPrepLpFilFrq
    connect CalRegn01Inin03.SysFricLrngDebStep -> AAACalRegn01Inin03_Dummy.SysFricLrngDebStep
    connect CalRegn01Inin03.SysFricLrngEolFricDifHiLim -> AAACalRegn01Inin03_Dummy.SysFricLrngEolFricDifHiLim
    connect CalRegn01Inin03.SysFricLrngEolFricDifLoLim -> AAACalRegn01Inin03_Dummy.SysFricLrngEolFricDifLoLim
    connect CalRegn01Inin03.SysFricLrngEolFricDifScagFac -> AAACalRegn01Inin03_Dummy.SysFricLrngEolFricDifScagFac
    connect CalRegn01Inin03.SysFricLrngFricChgWght -> AAACalRegn01Inin03_Dummy.SysFricLrngFricChgWght
    connect CalRegn01Inin03.SysFricLrngFricDiagcThd -> AAACalRegn01Inin03_Dummy.SysFricLrngFricDiagcThd
    connect CalRegn01Inin03.SysFricLrngFricHysHwAgPt -> AAACalRegn01Inin03_Dummy.SysFricLrngFricHysHwAgPt
    connect CalRegn01Inin03.SysFricLrngFricOffs -> AAACalRegn01Inin03_Dummy.SysFricLrngFricOffs
    connect CalRegn01Inin03.SysFricLrngFricOffsHiLim -> AAACalRegn01Inin03_Dummy.SysFricLrngFricOffsHiLim
    connect CalRegn01Inin03.SysFricLrngFricOffsLoLim -> AAACalRegn01Inin03_Dummy.SysFricLrngFricOffsLoLim
    connect CalRegn01Inin03.SysFricLrngFricOffsLpFilFrq -> AAACalRegn01Inin03_Dummy.SysFricLrngFricOffsLpFilFrq
    connect CalRegn01Inin03.SysFricLrngGain -> AAACalRegn01Inin03_Dummy.SysFricLrngGain
    connect CalRegn01Inin03.SysFricLrngHiFricDebStep -> AAACalRegn01Inin03_Dummy.SysFricLrngHiFricDebStep
    connect CalRegn01Inin03.SysFricLrngHiFricDiagcThd -> AAACalRegn01Inin03_Dummy.SysFricLrngHiFricDiagcThd
    connect CalRegn01Inin03.SysFricLrngHwPosnAuthyThd -> AAACalRegn01Inin03_Dummy.SysFricLrngHwPosnAuthyThd
    connect CalRegn01Inin03.SysFricLrngHwVelConstrLim -> AAACalRegn01Inin03_Dummy.SysFricLrngHwVelConstrLim
    connect CalRegn01Inin03.SysFricLrngHwVelHiLim -> AAACalRegn01Inin03_Dummy.SysFricLrngHwVelHiLim
    connect CalRegn01Inin03.SysFricLrngHwVelLoLim -> AAACalRegn01Inin03_Dummy.SysFricLrngHwVelLoLim
    connect CalRegn01Inin03.SysFricLrngIgnCycFricChgLim -> AAACalRegn01Inin03_Dummy.SysFricLrngIgnCycFricChgLim
    connect CalRegn01Inin03.SysFricLrngIgnCycFricOffs -> AAACalRegn01Inin03_Dummy.SysFricLrngIgnCycFricOffs
    connect CalRegn01Inin03.SysFricLrngIvsTrsmRatX -> AAACalRegn01Inin03_Dummy.SysFricLrngIvsTrsmRatX
    connect CalRegn01Inin03.SysFricLrngIvsTrsmRatY -> AAACalRegn01Inin03_Dummy.SysFricLrngIvsTrsmRatY
    connect CalRegn01Inin03.SysFricLrngLatAHiLim -> AAACalRegn01Inin03_Dummy.SysFricLrngLatAHiLim
    connect CalRegn01Inin03.SysFricLrngLatALoLim -> AAACalRegn01Inin03_Dummy.SysFricLrngLatALoLim
    connect CalRegn01Inin03.SysFricLrngMaskVehSpd -> AAACalRegn01Inin03_Dummy.SysFricLrngMaskVehSpd
    connect CalRegn01Inin03.SysFricLrngRngCntrThd -> AAACalRegn01Inin03_Dummy.SysFricLrngRngCntrThd
    connect CalRegn01Inin03.SysFricLrngThd -> AAACalRegn01Inin03_Dummy.SysFricLrngThd
    connect CalRegn01Inin03.SysFricLrngTHiLim -> AAACalRegn01Inin03_Dummy.SysFricLrngTHiLim
    connect CalRegn01Inin03.SysFricLrngTLoLim -> AAACalRegn01Inin03_Dummy.SysFricLrngTLoLim
    connect CalRegn01Inin03.SysFricLrngVehSpd -> AAACalRegn01Inin03_Dummy.SysFricLrngVehSpd
    connect CalRegn01Inin03.SysGlbPrmSysKineRat -> AAACalRegn01Inin03_Dummy.SysGlbPrmSysKineRat
    connect CalRegn01Inin03.SysGlbPrmVehSpdBilnrSeln -> AAACalRegn01Inin03_Dummy.SysGlbPrmVehSpdBilnrSeln
    connect CalRegn01Inin03.SysKineAndEffMotAgToRackPosRatScaY -> AAACalRegn01Inin03_Dummy.SysKineAndEffMotAgToRackPosRatScaY
    connect CalRegn01Inin03.SysKineAndEffPinionAgToRackPosRatScaY -> AAACalRegn01Inin03_Dummy.SysKineAndEffPinionAgToRackPosRatScaY
    connect CalRegn01Inin03.SysKineAndEffPinionToRackEffScaY -> AAACalRegn01Inin03_Dummy.SysKineAndEffPinionToRackEffScaY
    connect CalRegn01Inin03.SysKineAndEffRoadWhlFromRackPosScaY -> AAACalRegn01Inin03_Dummy.SysKineAndEffRoadWhlFromRackPosScaY
    connect CalRegn01Inin03.SysKineAndEffSteerArmLenFromRackPosScaY -> AAACalRegn01Inin03_Dummy.SysKineAndEffSteerArmLenFromRackPosScaY
    connect CalRegn01Inin03.TunSelnAuthyVehSpdX -> AAACalRegn01Inin03_Dummy.TunSelnAuthyVehSpdX
    connect CalRegn01Inin03GroupA.BmwHwAgArbnAndEotPosnEotCcwMax -> AAACalRegn01Inin03GroupA_Dummy.BmwHwAgArbnAndEotPosnEotCcwMax
    connect CalRegn01Inin03GroupA.BmwHwAgArbnAndEotPosnEotCcwMin -> AAACalRegn01Inin03GroupA_Dummy.BmwHwAgArbnAndEotPosnEotCcwMin
    connect CalRegn01Inin03GroupA.BmwHwAgArbnAndEotPosnEotCwMax -> AAACalRegn01Inin03GroupA_Dummy.BmwHwAgArbnAndEotPosnEotCwMax
    connect CalRegn01Inin03GroupA.BmwHwAgArbnAndEotPosnEotCwMin -> AAACalRegn01Inin03GroupA_Dummy.BmwHwAgArbnAndEotPosnEotCwMin
    connect CalRegn01Inin03GroupA.BmwPwrPrkgDampgDiScadDampg -> AAACalRegn01Inin03GroupA_Dummy.BmwPwrPrkgDampgDiScadDampg
    connect CalRegn01Inin03GroupA.BmwPwrPrkgDampgMaxRate -> AAACalRegn01Inin03GroupA_Dummy.BmwPwrPrkgDampgMaxRate
    connect CalRegn01Inin03GroupA.EpsStEstimnMtrxA -> AAACalRegn01Inin03GroupA_Dummy.EpsStEstimnMtrxA
    connect CalRegn01Inin03GroupA.EpsStEstimnMtrxB -> AAACalRegn01Inin03GroupA_Dummy.EpsStEstimnMtrxB
    connect CalRegn01Inin03GroupA.EpsStEstimnMtrxC -> AAACalRegn01Inin03GroupA_Dummy.EpsStEstimnMtrxC
    connect CalRegn01Inin03GroupA.EpsStEstimnMtrxD -> AAACalRegn01Inin03GroupA_Dummy.EpsStEstimnMtrxD
    connect CalRegn01Inin03GroupA.HwTqTrakgCtrlFbGain{1..5} -> AAACalRegn01Inin03GroupA_Dummy.HwTqTrakgCtrlFbGain{1..5}
    connect CalRegn01Inin03GroupA.HwTqTrakgCtrlFfGainScaY -> AAACalRegn01Inin03GroupA_Dummy.HwTqTrakgCtrlFfGainScaY
    connect CalRegn01Inin03GroupA.HwTqTrakgCtrlVehSpdScaX -> AAACalRegn01Inin03GroupA_Dummy.HwTqTrakgCtrlVehSpdScaX
    connect CalRegn01Inin03GroupA.PosnTrakgServoEnaBlndFacTblX -> AAACalRegn01Inin03GroupA_Dummy.PosnTrakgServoEnaBlndFacTblX
    connect CalRegn01Inin03GroupA.PosnTrakgServoEnaBlndFacTblY -> AAACalRegn01Inin03GroupA_Dummy.PosnTrakgServoEnaBlndFacTblY
    connect CalRegn01Inin03GroupA.PosnTrakgServoGainArbnFltMtgtn -> AAACalRegn01Inin03GroupA_Dummy.PosnTrakgServoGainArbnFltMtgtn
    connect CalRegn01Inin03GroupA.PullCmpActvCmpLrnTiDecShoTerm -> AAACalRegn01Inin03GroupA_Dummy.PullCmpActvCmpLrnTiDecShoTerm
    connect CalRegn01Inin03GroupA.PullCmpActvCmpLrnTiIncShoTerm -> AAACalRegn01Inin03GroupA_Dummy.PullCmpActvCmpLrnTiIncShoTerm
    connect CalRegn01Inin03GroupA.PullCmpActvCmpLrnTiLongTerm -> AAACalRegn01Inin03GroupA_Dummy.PullCmpActvCmpLrnTiLongTerm
    connect CalRegn01Inin03GroupA.PullCmpActvCmpShoTermRstHwAgThd -> AAACalRegn01Inin03GroupA_Dummy.PullCmpActvCmpShoTermRstHwAgThd
    connect CalRegn01Inin03GroupA.PullCmpActvCmpShoTermRstHwTqThd -> AAACalRegn01Inin03GroupA_Dummy.PullCmpActvCmpShoTermRstHwTqThd
    connect CalRegn01Inin03GroupA.PullCmpActvCmpShoTermRstLatAThd -> AAACalRegn01Inin03GroupA_Dummy.PullCmpActvCmpShoTermRstLatAThd
    connect CalRegn01Inin03GroupA.PullCmpActvCmpShoTermRstYawRateThd -> AAACalRegn01Inin03GroupA_Dummy.PullCmpActvCmpShoTermRstYawRateThd
    connect CalRegn01Inin03GroupA.PullCmpActvEna -> AAACalRegn01Inin03GroupA_Dummy.PullCmpActvEna
    connect CalRegn01Inin03GroupA.PullCmpActvHwTqFilFrqLongTerm -> AAACalRegn01Inin03GroupA_Dummy.PullCmpActvHwTqFilFrqLongTerm
    connect CalRegn01Inin03GroupA.PullCmpActvHwTqFilFrqShoTerm -> AAACalRegn01Inin03GroupA_Dummy.PullCmpActvHwTqFilFrqShoTerm
    connect CalRegn01Inin03GroupA.PullCmpActvLongTermLim -> AAACalRegn01Inin03GroupA_Dummy.PullCmpActvLongTermLim
    connect CalRegn01Inin03GroupA.PullCmpActvLrngEnaAgConfMinMgn -> AAACalRegn01Inin03GroupA_Dummy.PullCmpActvLrngEnaAgConfMinMgn
    connect CalRegn01Inin03GroupA.PullCmpActvLrngEnaHwAgMaxMgn -> AAACalRegn01Inin03GroupA_Dummy.PullCmpActvLrngEnaHwAgMaxMgn
    connect CalRegn01Inin03GroupA.PullCmpActvLrngEnaHwTqMaxMgn -> AAACalRegn01Inin03GroupA_Dummy.PullCmpActvLrngEnaHwTqMaxMgn
    connect CalRegn01Inin03GroupA.PullCmpActvLrngEnaHwVelMaxMgn -> AAACalRegn01Inin03GroupA_Dummy.PullCmpActvLrngEnaHwVelMaxMgn
    connect CalRegn01Inin03GroupA.PullCmpActvLrngEnaLatAMaxMgn -> AAACalRegn01Inin03GroupA_Dummy.PullCmpActvLrngEnaLatAMaxMgn
    connect CalRegn01Inin03GroupA.PullCmpActvLrngEnaTiThd -> AAACalRegn01Inin03GroupA_Dummy.PullCmpActvLrngEnaTiThd
    connect CalRegn01Inin03GroupA.PullCmpActvLrngEnaVehSpdMaxMgn -> AAACalRegn01Inin03GroupA_Dummy.PullCmpActvLrngEnaVehSpdMaxMgn
    connect CalRegn01Inin03GroupA.PullCmpActvLrngEnaVehSpdMinMgn -> AAACalRegn01Inin03GroupA_Dummy.PullCmpActvLrngEnaVehSpdMinMgn
    connect CalRegn01Inin03GroupA.PullCmpActvLrngEnaVehSpdRateMaxMgn -> AAACalRegn01Inin03GroupA_Dummy.PullCmpActvLrngEnaVehSpdRateMaxMgn
    connect CalRegn01Inin03GroupA.PullCmpActvLrngEnaYawRateMaxMgn -> AAACalRegn01Inin03GroupA_Dummy.PullCmpActvLrngEnaYawRateMaxMgn
    connect CalRegn01Inin03GroupA.PullCmpActvOpstSignTiShoTerm -> AAACalRegn01Inin03GroupA_Dummy.PullCmpActvOpstSignTiShoTerm
    connect CalRegn01Inin03GroupA.PullCmpActvOutpMaxRate -> AAACalRegn01Inin03GroupA_Dummy.PullCmpActvOutpMaxRate
    connect CalRegn01Inin03GroupA.PullCmpActvPullCmpShoTermLim -> AAACalRegn01Inin03GroupA_Dummy.PullCmpActvPullCmpShoTermLim
    connect CalRegn01Inin03GroupA.PullCmpActvPullCmpTotLim -> AAACalRegn01Inin03GroupA_Dummy.PullCmpActvPullCmpTotLim
    connect CalRegn01Inin03GroupA.PullCmpActvPullErrLimLongTerm -> AAACalRegn01Inin03GroupA_Dummy.PullCmpActvPullErrLimLongTerm
    connect CalRegn01Inin03GroupA.PullCmpActvPullErrMgnThd -> AAACalRegn01Inin03GroupA_Dummy.PullCmpActvPullErrMgnThd
    connect CalRegn01Inin03GroupA.PullCmpActvPullErrShoTermLim -> AAACalRegn01Inin03GroupA_Dummy.PullCmpActvPullErrShoTermLim
    connect CalRegn01Inin03GroupA.PullCmpActvShoTermRampTi -> AAACalRegn01Inin03GroupA_Dummy.PullCmpActvShoTermRampTi
    connect CalRegn01Inin03GroupA.PullCmpActvVehSpdScaTblX -> AAACalRegn01Inin03GroupA_Dummy.PullCmpActvVehSpdScaTblX
    connect CalRegn01Inin03GroupA.PullCmpActvVehSpdScaTblY -> AAACalRegn01Inin03GroupA_Dummy.PullCmpActvVehSpdScaTblY
    connect CalRegn01Inin03GroupC.CtrldVelRtnDesVelLpFilFrq -> AAACalRegn01Inin03GroupC_Dummy.CtrldVelRtnDesVelLpFilFrq
    connect CalRegn01Inin03GroupC.CtrldVelRtnHwTqLpFilFrq -> AAACalRegn01Inin03GroupC_Dummy.CtrldVelRtnHwTqLpFilFrq
    connect CalRegn01Inin03GroupC.CtrldVelRtnHwTqScaSelnSlewHiLim -> AAACalRegn01Inin03GroupC_Dummy.CtrldVelRtnHwTqScaSelnSlewHiLim
    connect CalRegn01Inin03GroupC.CtrldVelRtnHwTqScaSelnSlewLoLim -> AAACalRegn01Inin03GroupC_Dummy.CtrldVelRtnHwTqScaSelnSlewLoLim
    connect CalRegn01Inin03GroupC.CtrldVelRtnHwTqScaSelnTqThd -> AAACalRegn01Inin03GroupC_Dummy.CtrldVelRtnHwTqScaSelnTqThd
    connect CalRegn01Inin03GroupC.CtrldVelRtnHwTqScaSelnVelThd -> AAACalRegn01Inin03GroupC_Dummy.CtrldVelRtnHwTqScaSelnVelThd
    connect CalRegn01Inin03GroupC.CtrldVelRtnIntgrLimY -> AAACalRegn01Inin03GroupC_Dummy.CtrldVelRtnIntgrLimY
    connect CalRegn01Inin03GroupC.CtrldVelRtnOffsSlewThd -> AAACalRegn01Inin03GroupC_Dummy.CtrldVelRtnOffsSlewThd
    connect CalRegn01Inin03GroupC.CtrldVelRtnOffsThd -> AAACalRegn01Inin03GroupC_Dummy.CtrldVelRtnOffsThd
    connect CalRegn01Inin03GroupC.CtrldVelRtnScaLpFilFrq -> AAACalRegn01Inin03GroupC_Dummy.CtrldVelRtnScaLpFilFrq
    connect CalRegn01Inin03GroupC.FalbckAssiAssiX -> AAACalRegn01Inin03GroupC_Dummy.FalbckAssiAssiX
    connect CalRegn01Inin03GroupC.FalbckAssiAssiY -> AAACalRegn01Inin03GroupC_Dummy.FalbckAssiAssiY
    connect CalRegn01Inin03GroupC.FalbckAssiNotchFil -> AAACalRegn01Inin03GroupC_Dummy.FalbckAssiNotchFil
    connect CalRegn01Inin03GroupC.GlbLimrBndX -> AAACalRegn01Inin03GroupC_Dummy.GlbLimrBndX
    connect CalRegn01Inin03GroupC.GlbLimrBndY -> AAACalRegn01Inin03GroupC_Dummy.GlbLimrBndY
    connect CalRegn01Inin03GroupC.GlbLimrNotchFilStruct -> AAACalRegn01Inin03GroupC_Dummy.GlbLimrNotchFilStruct
    connect CalRegn01Inin03GroupC.GlbLimrVehSpdBilnrSeln -> AAACalRegn01Inin03GroupC_Dummy.GlbLimrVehSpdBilnrSeln
    connect CalRegn01Inin03GroupD.EotProtnDampgVehSpdTbl -> AAACalRegn01Inin03GroupD_Dummy.EotProtnDampgVehSpdTbl
    connect CalRegn01Inin03GroupD.EotProtnDeltaTqThd -> AAACalRegn01Inin03GroupD_Dummy.EotProtnDeltaTqThd
    connect CalRegn01Inin03GroupD.EotProtnEntrGainAuthyThd -> AAACalRegn01Inin03GroupD_Dummy.EotProtnEntrGainAuthyThd
